VERSION ""

NS_ :

BS_:
BU_: ACC GW LAS BDC
BO_ 898 ACC_382: 64 ACC
 SG_ ACC_TarVehLngRange : 487|12@0+ (0.1000000000,0.0000000000) [0.0000000000|300.0000000000] "m"  LAS,GW
 SG_ ACC_Target5ZoneID : 449|5@0+ (1.0000000000,0.0000000000) [0.0000000000|31.0000000000] ""  LAS,GW,mADC
 SG_ ACC_Target5HeadingAngle : 443|10@0+ (0.0100000000,-3.1400000000) [-3.1400000000|3.1400000000] "rad"  LAS,GW,mADC
 SG_ ACC_Target5Direction : 446|3@0+ (1.0000000000,0.0000000000) [0.0000000000|7.0000000000] ""  LAS,GW,mADC
 SG_ ACC_Target5LatRange : 424|10@0+ (0.1000000000,-50.0000000000) [-50.0000000000|50.0000000000] "m"  LAS,GW,mADC
 SG_ ACC_Target5LngRange : 420|12@0+ (0.1000000000,-100.0000000000) [-100.0000000000|300.0000000000] "m"  LAS,GW,mADC
 SG_ ACC_Target5Type : 408|4@0+ (1.0000000000,0.0000000000) [0.0000000000|15.0000000000] ""  LAS,GW,mADC
 SG_ ACC_Target5ID : 414|6@0+ (1.0000000000,0.0000000000) [0.0000000000|63.0000000000] ""  LAS,GW,mADC
 SG_ ACC_Target5Detection : 401|3@0+ (1.0000000000,0.0000000000) [0.0000000000|7.0000000000] ""  LAS,GW,mADC
 SG_ ACC_Target4ZoneID : 406|5@0+ (1.0000000000,0.0000000000) [0.0000000000|31.0000000000] ""  LAS,GW,mADC
 SG_ ACC_Target4HeadingAngle : 384|10@0+ (0.0100000000,-3.1400000000) [-3.1400000000|3.1400000000] "rad"  LAS,GW,mADC
 SG_ ACC_Target4Direction : 387|3@0+ (1.0000000000,0.0000000000) [0.0000000000|7.0000000000] ""  LAS,GW,mADC
 SG_ ACC_Target4LatRange : 381|10@0+ (0.1000000000,-50.0000000000) [-50.0000000000|50.0000000000] "m"  LAS,GW,mADC
 SG_ ACC_Target4LngRange : 361|12@0+ (0.1000000000,-100.0000000000) [-100.0000000000|300.0000000000] "m"  LAS,GW,mADC
 SG_ ACC_Target4Type : 365|4@0+ (1.0000000000,0.0000000000) [0.0000000000|15.0000000000] ""  LAS,GW,mADC
 SG_ ACC_Target4ID : 355|6@0+ (1.0000000000,0.0000000000) [0.0000000000|63.0000000000] ""  LAS,GW,mADC
 SG_ ACC_Target4Detection : 358|3@0+ (1.0000000000,0.0000000000) [0.0000000000|7.0000000000] ""  LAS,GW,mADC
 SG_ ACC_Target3ZoneID : 347|5@0+ (1.0000000000,0.0000000000) [0.0000000000|31.0000000000] ""  LAS,GW,mADC
 SG_ ACC_Target3HeadingAngle : 341|10@0+ (0.0100000000,-3.1400000000) [-3.1400000000|3.1400000000] "rad"  LAS,GW,mADC
 SG_ ACC_Target3Direction : 328|3@0+ (1.0000000000,0.0000000000) [0.0000000000|7.0000000000] ""  LAS,GW,mADC
 SG_ ACC_Target3LatRange : 322|10@0+ (0.1000000000,-50.0000000000) [-50.0000000000|50.0000000000] "m"  LAS,GW,mADC
 SG_ ACC_Target3LngRange : 318|12@0+ (0.1000000000,-100.0000000000) [-100.0000000000|300.0000000000] "m"  LAS,GW,mADC
 SG_ ACC_Target3Type : 306|4@0+ (1.0000000000,0.0000000000) [0.0000000000|15.0000000000] ""  LAS,GW,mADC
 SG_ ACC_Target3ID : 296|6@0+ (1.0000000000,0.0000000000) [0.0000000000|63.0000000000] ""  LAS,GW,mADC
 SG_ ACC_Target3Detection : 299|3@0+ (1.0000000000,0.0000000000) [0.0000000000|7.0000000000] ""  LAS,GW,mADC
 SG_ ACC_Target2ZoneID : 288|5@0+ (1.0000000000,0.0000000000) [0.0000000000|31.0000000000] ""  LAS,GW,mADC
 SG_ ACC_Target2HeadingAngle : 282|10@0+ (0.0100000000,-3.1400000000) [-3.1400000000|3.1400000000] "rad"  LAS,GW,mADC
 SG_ ACC_Target2Direction : 285|3@0+ (1.0000000000,0.0000000000) [0.0000000000|7.0000000000] ""  LAS,GW,mADC
 SG_ ACC_Target2LatRange : 279|10@0+ (0.1000000000,-50.0000000000) [-50.0000000000|50.0000000000] "m"  LAS,GW,mADC
 SG_ ACC_Target2LngRange : 259|12@0+ (0.1000000000,-100.0000000000) [-100.0000000000|300.0000000000] "m"  LAS,GW,mADC
 SG_ ACC_Target2Type : 263|4@0+ (1.0000000000,0.0000000000) [0.0000000000|15.0000000000] ""  LAS,GW,mADC
 SG_ ACC_Target2ID : 253|6@0+ (1.0000000000,0.0000000000) [0.0000000000|63.0000000000] ""  LAS,GW,mADC
 SG_ ACC_Target2Detection : 240|3@0+ (1.0000000000,0.0000000000) [0.0000000000|7.0000000000] ""  LAS,GW,mADC
 SG_ ACC_Target1ZoneID : 247|5@0+ (1.0000000000,0.0000000000) [0.0000000000|31.0000000000] ""  LAS,GW,mADC
 SG_ ACC_Target1HeadingAngle : 225|10@0+ (0.0100000000,-3.1400000000) [-3.1400000000|3.1400000000] "rad"  LAS,GW,mADC
 SG_ ACC_Target1Direction : 202|3@0+ (1.0000000000,0.0000000000) [0.0000000000|7.0000000000] ""  LAS,GW,mADC
 SG_ ACC_Target1LatRange : 219|10@0+ (0.1000000000,-50.0000000000) [-50.0000000000|50.0000000000] "m"  LAS,GW,mADC
 SG_ ACC_Target1LngRange : 215|12@0+ (0.1000000000,-100.0000000000) [-100.0000000000|300.0000000000] "m"  LAS,GW,mADC
 SG_ ACC_Target1Type : 206|4@0+ (1.0000000000,0.0000000000) [0.0000000000|15.0000000000] ""  LAS,GW,mADC
 SG_ ACC_Target1ID : 196|6@0+ (1.0000000000,0.0000000000) [0.0000000000|63.0000000000] ""  LAS,GW,mADC
 SG_ ACC_Target1Detection : 199|3@0+ (1.0000000000,0.0000000000) [0.0000000000|7.0000000000] ""  LAS,GW,mADC
 SG_ ACC_RollingCounter_3E6 : 179|4@0+ (1.0000000000,0.0000000000) [0.0000000000|15.0000000000] ""  LAS,GW
 SG_ ACC_CRCCheck_3E6 : 191|8@0+ (1.0000000000,0.0000000000) [0.0000000000|255.0000000000] ""  LAS,GW
 SG_ ACC_CRCCheck_35C : 127|8@0+ (1.0000000000,0.0000000000) [0.0000000000|255.0000000000] ""  LAS,GW
 SG_ ACC_RollingCounter_35C : 115|4@0+ (1.0000000000,0.0000000000) [0.0000000000|15.0000000000] ""  LAS,GW
 SG_ ACC_CRCCheck_35D : 63|8@0+ (1.0000000000,0.0000000000) [0.0000000000|255.0000000000] ""  LAS,GW
 SG_ ACC_RollingCounter_35D : 51|4@0+ (1.0000000000,0.0000000000) [0.0000000000|15.0000000000] ""  LAS,GW
 SG_ ACC_LaneEquationStatus : 181|2@0+ (1.0000000000,0.0000000000) [0.0000000000|3.0000000000] ""  LAS,GW,mADC
 SG_ ACC_LaneEquationC3 : 161|12@0+ (0.0000004768,-0.0009760857) [-0.0009760857|0.0009760857] ""  LAS,GW,mADC
 SG_ ACC_LaneEquationC2 : 157|12@0+ (0.0000152588,-0.0312347412) [-0.0312347412|0.0312347412] ""  LAS,GW,mADC
 SG_ ACC_LaneEquationC1 : 137|12@0+ (0.0004882813,-1.0000000000) [-1.0000000000|0.9990234375] "rad"  LAS,GW,mADC
 SG_ ACC_LaneQuality : 134|6@0+ (0.0156250000,0.0000000000) [0.0000000000|0.9843750000] ""  LAS,GW

BO_ 676 GW_2A4: 64 GW
 SG_ LCDAR_AEBVehilceHoldReq : 131|1@0+ (1.0000000000,0.0000000000) [0.0000000000|1.0000000000] ""  ACC,LAS
 SG_ LCDAR_LDWShakeLevStatus : 133|2@0+ (1.0000000000,0.0000000000) [0.0000000000|3.0000000000] ""  ACC,LAS
 SG_ LCDAR_LDWVibrationWarningReq : 135|2@0+ (1.0000000000,0.0000000000) [0.0000000000|3.0000000000] ""  ACC,LAS
 SG_ LCDA_BSDLCAMode : 14|2@0+ (1.0000000000,0.0000000000) [0.0000000000|3.0000000000] ""  mADC,LAS,ACC
 SG_ LCDAR_RCTBStatus : 17|2@0+ (1.0000000000,0.0000000000) [0.0000000000|3.0000000000] ""  ACC,LAS,mADC
 SG_ LCDAR_CRCCheck_2AF : 63|8@0+ (1.0000000000,0.0000000000) [0.0000000000|255.0000000000] ""  LAS,ACC
 SG_ LCDAR_RollingCounter_2AF : 51|4@0+ (1.0000000000,0.0000000000) [0.0000000000|15.0000000000] ""  LAS,ACC
 SG_ LCDAR_ELK_oAlert : 25|2@0+ (1.0000000000,0.0000000000) [0.0000000000|3.0000000000] ""  LAS
 SG_ LCDAR_ELK_oStatus : 27|2@0+ (1.0000000000,0.0000000000) [0.0000000000|3.0000000000] ""  LAS
 SG_ LCDAR_Left_ELK_oAlert : 29|2@0+ (1.0000000000,0.0000000000) [0.0000000000|3.0000000000] ""  LAS
 SG_ LCDAR_RCTBActive : 19|1@0+ (1.0000000000,0.0000000000) [0.0000000000|1.0000000000] ""  ACC,LAS,mADC
 SG_ LCDAR_RCTBTargetDecel : 39|16@0+ (0.0005000000,-16.0000000000) [-16.0000000000|16.0000000000] "m/s2"  ACC,LAS
 SG_ LCDAR_SystemStatus : 12|3@0+ (1.0000000000,0.0000000000) [0.0000000000|7.0000000000] ""  ACC,LAS,mADC

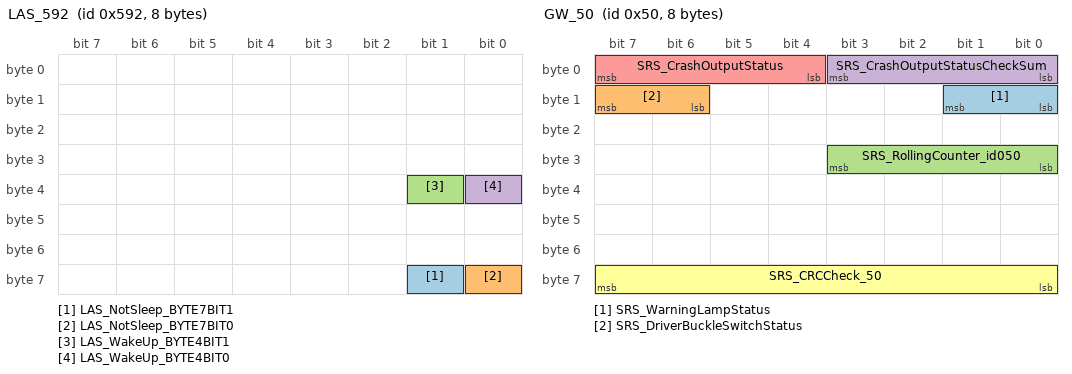
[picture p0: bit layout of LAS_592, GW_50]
BO_ 1426 LAS_592: 8 LAS
 SG_ LAS_NotSleep_BYTE7BIT1 : 57|1@0+ (1.0000000000,0.0000000000) [0.0000000000|1.0000000000] ""  GW
 SG_ LAS_NotSleep_BYTE7BIT0 : 56|1@0+ (1.0000000000,0.0000000000) [0.0000000000|1.0000000000] ""  GW
 SG_ LAS_WakeUp_BYTE4BIT1 : 33|1@0+ (1.0000000000,0.0000000000) [0.0000000000|1.0000000000] ""  GW
 SG_ LAS_WakeUp_BYTE4BIT0 : 32|1@0+ (1.0000000000,0.0000000000) [0.0000000000|1.0000000000] ""  GW

BO_ 80 GW_50: 8 GW
 SG_ SRS_WarningLampStatus : 9|2@0+ (1.0000000000,0.0000000000) [0.0000000000|3.0000000000] ""  ACC,LAS,mADC
 SG_ SRS_DriverBuckleSwitchStatus : 15|2@0+ (1.0000000000,0.0000000000) [0.0000000000|3.0000000000] ""  ACC,LAS,APA,mADC
 SG_ SRS_RollingCounter_id050 : 27|4@0+ (1.0000000000,0.0000000000) [0.0000000000|15.0000000000] ""  ACC,LAS,mADC
 SG_ SRS_CrashOutputStatusCheckSum : 3|4@0+ (1.0000000000,0.0000000000) [0.0000000000|15.0000000000] ""  ACC,LAS,mADC
 SG_ SRS_CrashOutputStatus : 7|4@0+ (1.0000000000,0.0000000000) [0.0000000000|15.0000000000] ""  ACC,LAS,APA,mADC
 SG_ SRS_CRCCheck_50 : 63|8@0+ (1.0000000000,0.0000000000) [0.0000000000|255.0000000000] ""  ACC,LAS,mADC

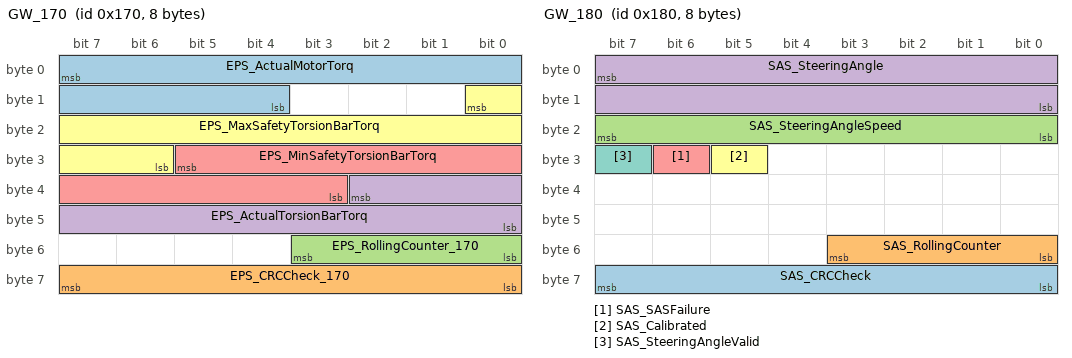
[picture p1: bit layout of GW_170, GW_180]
BO_ 368 GW_170: 8 GW
 SG_ EPS_ActualMotorTorq : 7|12@0+ (0.0100000000,-20.4800000000) [-20.4800000000|20.4600000000] "Nm"  LAS,mADC
 SG_ EPS_CRCCheck_170 : 63|8@0+ (1.0000000000,0.0000000000) [0.0000000000|255.0000000000] ""  mADC,ACC,LAS
 SG_ EPS_RollingCounter_170 : 51|4@0+ (1.0000000000,0.0000000000) [0.0000000000|15.0000000000] ""  ACC,LAS,mADC
 SG_ EPS_ActualTorsionBarTorq : 34|11@0+ (0.0200000000,-20.4800000000) [-20.4800000000|20.4400000000] "Nm"  LAS,mADC
 SG_ EPS_MinSafetyTorsionBarTorq : 29|11@0+ (0.0200000000,-20.4800000000) [-20.4800000000|20.4400000000] "Nm"  LAS,mADC
 SG_ EPS_MaxSafetyTorsionBarTorq : 8|11@0+ (0.0200000000,-20.4800000000) [-20.4800000000|20.4400000000] "Nm"  LAS,mADC

BO_ 384 GW_180: 8 GW
 SG_ SAS_CRCCheck : 63|8@0+ (1.0000000000,0.0000000000) [0.0000000000|255.0000000000] ""  APA,ACC,LAS,mADC
 SG_ SAS_RollingCounter : 51|4@0+ (1.0000000000,0.0000000000) [0.0000000000|15.0000000000] ""  APA,ACC,LAS,mADC
 SG_ SAS_SteeringAngleSpeed : 23|8@0+ (4.0000000000,0.0000000000) [0.0000000000|1016.0000000000] "deg/s"  APA,ACC,LAS,mADC
 SG_ SAS_SteeringAngle : 7|16@0- (0.1000000000,0.0000000000) [-780.0000000000|780.0000000000] "degree"  APA,ACC,LAS,mADC
 SG_ SAS_SASFailure : 30|1@0+ (1.0000000000,0.0000000000) [0.0000000000|1.0000000000] ""  APA,ACC,LAS,mADC
 SG_ SAS_Calibrated : 29|1@0+ (1.0000000000,0.0000000000) [0.0000000000|1.0000000000] ""  APA,ACC,LAS,mADC
 SG_ SAS_SteeringAngleValid : 31|1@0+ (1.0000000000,0.0000000000) [0.0000000000|1.0000000000] ""  APA,ACC,LAS,mADC

BO_ 580 ACC_244: 64 ACC
 SG_ ACC_AEBSpeedDropLevel : 162|2@0+ (1.0000000000,0.0000000000) [0.0000000000|3.0000000000] ""  LAS,mADC,GW
 SG_ ADS_ResetFlag_244 : 449|2@0+ (1.0000000000,0.0000000000) [0.0000000000|3.0000000000] ""  LAS,mADC,GW
 SG_ ADS_Authernticator_244 : 463|56@0+ (1.0000000000,0.0000000000) [0.0000000000|0.0000000000] ""  LAS,mADC,GW
 SG_ ADS_MesssageCounter_244 : 455|6@0+ (1.0000000000,0.0000000000) [0.0000000000|63.0000000000] ""  LAS,mADC,GW
 SG_ ADS_EOMTOReq : 155|2@0+ (1.0000000000,0.0000000000) [0.0000000000|3.0000000000] ""  LAS,GW
 SG_ ACC_HandsOnReq : 158|3@0+ (1.0000000000,0.0000000000) [0.0000000000|7.0000000000] ""  LAS,GW,APA,mADC
 SG_ ACC_LatTakeoverReq : 138|2@0+ (1.0000000000,0.0000000000) [0.0000000000|3.0000000000] ""  LAS,GW,APA,mADC
 SG_ ACC_LngTakeOverReq : 140|2@0+ (1.0000000000,0.0000000000) [0.0000000000|3.0000000000] ""  LAS,GW,APA,mADC
 SG_ ACC_LDWShakeLevStatus : 21|2@0+ (1.0000000000,0.0000000000) [0.0000000000|3.0000000000] ""  LAS,GW,mADC
 SG_ ACC_TextInfoForDriver : 30|6@0+ (1.0000000000,0.0000000000) [0.0000000000|63.0000000000] ""  LAS,GW,mADC
 SG_ ADS__RollingCounter_244 : 427|4@0+ (1.0000000000,0.0000000000) [0.0000000000|15.0000000000] ""  LAS,GW,mADC
 SG_ ADS_CRCCheck_244 : 439|16@0+ (1.0000000000,0.0000000000) [0.0000000000|65535.0000000000] ""  LAS,GW,mADC
 SG_ ACC_CRCCheck_25E : 127|8@0+ (1.0000000000,0.0000000000) [0.0000000000|255.0000000000] ""  LAS,GW,mADC
 SG_ ACC_RollingCounter_25E : 115|4@0+ (1.0000000000,0.0000000000) [0.0000000000|15.0000000000] ""  LAS,GW,mADC
 SG_ ACC_AEBCtrlType : 104|4@0+ (1.0000000000,0.0000000000) [0.0000000000|15.0000000000] ""  GW,LAS,APA,mADC
 SG_ ACC_FuelCutOffPrevention : 116|1@0+ (1.0000000000,0.0000000000) [0.0000000000|1.0000000000] ""  LAS,GW
 SG_ ACC_AccTrqReq : 88|14@0+ (5.0000000000,-5000.0000000000) [-5000.0000000000|5000.0000000000] "NM"  LAS,GW,mADC
 SG_ ACC_AccTrqReqActive : 106|1@0+ (1.0000000000,0.0000000000) [0.0000000000|1.0000000000] ""  LAS,GW,mADC
 SG_ ACC_AEBVehilceHoldReq : 90|1@0+ (1.0000000000,0.0000000000) [0.0000000000|1.0000000000] ""  LAS,GW,mADC
 SG_ ACC_FCWPreWarning : 91|1@0+ (1.0000000000,0.0000000000) [0.0000000000|1.0000000000] ""  LAS,GW,APA,mADC
 SG_ ACC_FCWLatentWarning : 92|1@0+ (1.0000000000,0.0000000000) [0.0000000000|1.0000000000] ""  LAS,GW,mADC
 SG_ ACC_FCWActive : 93|1@0+ (1.0000000000,0.0000000000) [0.0000000000|1.0000000000] ""  LAS,GW,mADC
 SG_ ACC_PrefillActive : 94|1@0+ (1.0000000000,0.0000000000) [0.0000000000|1.0000000000] ""  LAS,GW,mADC
 SG_ ACC_AWBActive : 95|1@0+ (1.0000000000,0.0000000000) [0.0000000000|1.0000000000] ""  LAS,GW,APA,mADC
 SG_ ACC_AWBlevel : 83|4@0+ (1.0000000000,0.0000000000) [0.0000000000|15.0000000000] ""  LAS,GW,mADC
 SG_ ACC_ABAActive : 84|1@0+ (1.0000000000,0.0000000000) [0.0000000000|1.0000000000] ""  LAS,GW,mADC
 SG_ ACC_ABAlevel : 86|2@0+ (1.0000000000,0.0000000000) [0.0000000000|3.0000000000] ""  LAS,GW,mADC
 SG_ ACC_AEBActive : 87|1@0+ (1.0000000000,0.0000000000) [0.0000000000|1.0000000000] ""  GW,APA,LAS,mADC
 SG_ ACC_AEBTargetDeceleration : 71|16@0+ (0.0005000000,-16.0000000000) [-16.0000000000|16.0000000000] "m/s2"  LAS,GW,mADC
 SG_ ACC_EmergencyDataRrdReq : 23|2@0+ (1.0000000000,0.0000000000) [0.0000000000|3.0000000000] ""  LAS,APA,GW,mADC
 SG_ ACC_CRCCheck_24E : 63|8@0+ (1.0000000000,0.0000000000) [0.0000000000|255.0000000000] ""  LAS,GW,mADC
 SG_ ACC_RollingCounter_24E : 51|4@0+ (1.0000000000,0.0000000000) [0.0000000000|15.0000000000] ""  LAS,GW,mADC
 SG_ ACC_Driveoff_Request : 55|1@0+ (1.0000000000,0.0000000000) [0.0000000000|1.0000000000] ""  LAS,GW,mADC
 SG_ ACC_ACCMode : 54|3@0+ (1.0000000000,0.0000000000) [0.0000000000|7.0000000000] ""  LAS,GW,APA,mADC
 SG_ ACC_CDDActive : 44|1@0+ (1.0000000000,0.0000000000) [0.0000000000|1.0000000000] ""  LAS,GW,mADC
 SG_ ACC_EngineStartStopRequest : 41|2@0+ (1.0000000000,0.0000000000) [0.0000000000|3.0000000000] ""  LAS,GW,mADC
 SG_ ACC_DecToStop : 31|1@0+ (1.0000000000,0.0000000000) [0.0000000000|1.0000000000] ""  LAS,GW,mADC
 SG_ ACC_TCUCreepProhibition : 32|1@0+ (1.0000000000,0.0000000000) [0.0000000000|1.0000000000] ""  LAS,GW
 SG_ ACC_LKAStatus : 13|2@0+ (1.0000000000,0.0000000000) [0.0000000000|3.0000000000] ""  LAS,GW,mADC
 SG_ ACC_LDWVibrationWarningReq : 11|2@0+ (1.0000000000,0.0000000000) [0.0000000000|3.0000000000] ""  LAS,GW,mADC
 SG_ ACC_LDWStatus : 9|2@0+ (1.0000000000,0.0000000000) [0.0000000000|3.0000000000] ""  LAS,GW,mADC
 SG_ ACC_ACCTargetAcceleration : 7|8@0+ (0.0500000000,-5.0000000000) [-5.0000000000|7.7500000000] "m/s2"  LAS,GW,mADC

BO_ 664 GW_298: 8 GW
 SG_ BCM_DriverDoorLockStatus : 44|2@0+ (1.0000000000,0.0000000000) [0.0000000000|3.0000000000] ""  ACC,LAS,APA,mADC
 SG_ BCM_LeftRearDoorStatus : 40|1@0+ (1.0000000000,0.0000000000) [0.0000000000|1.0000000000] ""  ACC,LAS,APA,mADC

BO_ 775 ACC_307: 64 ACC
 SG_ ACC_CSLmodeStatus : 14|1@0+ (1.0000000000,0.0000000000) [0.0000000000|1.0000000000] ""  LAS,mADC,GW
 SG_ ACC_CSLEnableStatus : 19|1@0+ (1.0000000000,0.0000000000) [0.0000000000|1.0000000000] ""  LAS,mADC,GW
 SG_ ACC_AEBTargetSelected : 235|3@0+ (1.0000000000,0.0000000000) [0.0000000000|7.0000000000] ""  LAS,GW
 SG_ ACC_AEBFeatureConfig : 84|4@0+ (1.0000000000,0.0000000000) [0.0000000000|15.0000000000] ""  LAS,GW
 SG_ ACC_LatDeviationDis : 55|3@0+ (1.0000000000,0.0000000000) [0.0000000000|7.0000000000] ""  LAS,GW
 SG_ ACC_LatDeviationReason : 34|3@0+ (1.0000000000,0.0000000000) [0.0000000000|7.0000000000] ""  LAS,GW,mADC
 SG_ ACC_IACCSuspendReason : 39|3@0+ (1.0000000000,0.0000000000) [0.0000000000|7.0000000000] ""  LAS,GW,mADC
 SG_ ACC_IACCProhibitionTime : 226|7@0+ (1.0000000000,0.0000000000) [0.0000000000|127.0000000000] "s"  LAS,GW,mADC
 SG_ ACC_Line_RR_Id : 479|8@0+ (1.0000000000,0.0000000000) [0.0000000000|255.0000000000] ""  LAS,GW,mADC
 SG_ ACC_Line_R_Id : 471|8@0+ (1.0000000000,0.0000000000) [0.0000000000|255.0000000000] ""  LAS,GW,mADC
 SG_ ACC_Line_LL_Id : 463|8@0+ (1.0000000000,0.0000000000) [0.0000000000|255.0000000000] ""  LAS,GW,mADC
 SG_ ACC_Line_L_Id : 455|8@0+ (1.0000000000,0.0000000000) [0.0000000000|255.0000000000] ""  LAS,GW,mADC
 SG_ ACC_RRLanecolor : 494|3@0+ (1.0000000000,0.0000000000) [0.0000000000|7.0000000000] ""  LAS,GW,mADC
 SG_ ACC_RLanecolor : 481|3@0+ (1.0000000000,0.0000000000) [0.0000000000|7.0000000000] ""  LAS,GW,mADC
 SG_ ACC_LLLanecolor : 484|3@0+ (1.0000000000,0.0000000000) [0.0000000000|7.0000000000] ""  LAS,GW,mADC
 SG_ ACC_LLanecolor : 487|3@0+ (1.0000000000,0.0000000000) [0.0000000000|7.0000000000] ""  LAS,GW,mADC
 SG_ ACC_RLaneDistanceFus : 415|7@0+ (0.0500000000,-5.0000000000) [-5.0000000000|1.0000000000] "m"  LAS,GW,mADC
 SG_ ACC_LLaneDistanceFus : 407|7@0+ (0.0500000000,-1.0000000000) [-1.0000000000|5.0000000000] "m"  LAS,GW,mADC
 SG_ ACC_RRLaneDis : 399|8@0+ (0.0500000000,-12.0000000000) [-12.0000000000|0.0000000000] "m"  LAS,GW,mADC
 SG_ ACC_LLLaneDis : 391|8@0+ (0.0500000000,0.0000000000) [0.0000000000|12.0000000000] "m"  LAS,GW,mADC
 SG_ ACC_Target7ZoneID : 375|5@0+ (1.0000000000,0.0000000000) [0.0000000000|31.0000000000] ""  LAS,GW,mADC
 SG_ ACC_Target7HeadingAngle : 353|10@0+ (0.0100000000,-3.1400000000) [-3.1400000000|3.1400000000] "rad"  LAS,GW,mADC
 SG_ ACC_Target7Direction : 330|3@0+ (1.0000000000,0.0000000000) [0.0000000000|7.0000000000] ""  LAS,GW,mADC
 SG_ ACC_Target7LatRange : 347|10@0+ (0.1000000000,-50.0000000000) [-50.0000000000|50.0000000000] "m"  LAS,GW,mADC
 SG_ ACC_Target7LngRange : 343|12@0+ (0.1000000000,-100.0000000000) [-100.0000000000|300.0000000000] "m"  LAS,GW,mADC
 SG_ ACC_Target7Type : 334|4@0+ (1.0000000000,0.0000000000) [0.0000000000|15.0000000000] ""  LAS,GW,mADC
 SG_ ACC_Target7ID : 324|6@0+ (1.0000000000,0.0000000000) [0.0000000000|63.0000000000] ""  LAS,GW,mADC
 SG_ ACC_Target7Detection : 327|3@0+ (1.0000000000,0.0000000000) [0.0000000000|7.0000000000] ""  LAS,GW,mADC
 SG_ ACC_Target6ZoneID : 311|5@0+ (1.0000000000,0.0000000000) [0.0000000000|31.0000000000] ""  LAS,GW,mADC
 SG_ ACC_Target6HeadingAngle : 289|10@0+ (0.0100000000,-3.1400000000) [-3.1400000000|3.1400000000] "rad"  LAS,GW,mADC
 SG_ ACC_Target6Direction : 266|3@0+ (1.0000000000,0.0000000000) [0.0000000000|7.0000000000] ""  LAS,GW,mADC
 SG_ ACC_Target6LatRange : 283|10@0+ (0.1000000000,-50.0000000000) [-50.0000000000|50.0000000000] "m"  LAS,GW,mADC
 SG_ ACC_Target6LngRange : 279|12@0+ (0.1000000000,-100.0000000000) [-100.0000000000|300.0000000000] "m"  LAS,GW,mADC
 SG_ ACC_Target6Type : 270|4@0+ (1.0000000000,0.0000000000) [0.0000000000|15.0000000000] ""  LAS,GW,mADC
 SG_ ACC_Target6ID : 260|6@0+ (1.0000000000,0.0000000000) [0.0000000000|63.0000000000] ""  LAS,GW,mADC
 SG_ ACC_Target6Detection : 263|3@0+ (1.0000000000,0.0000000000) [0.0000000000|7.0000000000] ""  LAS,GW,mADC
 SG_ ACC_AEBEnable : 27|2@0+ (1.0000000000,0.0000000000) [0.0000000000|3.0000000000] ""  LAS,GW,mADC
 SG_ ACC_VehicleStartRemindSts : 425|3@0+ (1.0000000000,0.0000000000) [0.0000000000|7.0000000000] ""  LAS,GW,mADC
 SG_ ACC_CRCCheck_35F : 255|8@0+ (1.0000000000,0.0000000000) [0.0000000000|255.0000000000] ""  LAS,GW,mADC
 SG_ ACC_RollingCounter_35F : 243|4@0+ (1.0000000000,0.0000000000) [0.0000000000|15.0000000000] ""  LAS,GW,mADC
 SG_ ACC_CSLAEnableStatus : 245|2@0+ (1.0000000000,0.0000000000) [0.0000000000|3.0000000000] ""  LAS,GW
 SG_ ACC_CSLSetReq : 227|1@0+ (1.0000000000,0.0000000000) [0.0000000000|1.0000000000] ""  LAS,GW,mADC
 SG_ ACC_CRCCheck_344 : 191|8@0+ (1.0000000000,0.0000000000) [0.0000000000|255.0000000000] ""  LAS,GW,mADC
 SG_ ACC_RollingCounter_344 : 179|4@0+ (1.0000000000,0.0000000000) [0.0000000000|15.0000000000] ""  LAS,GW,mADC
 SG_ ACC_CRCCheck_322 : 127|8@0+ (1.0000000000,0.0000000000) [0.0000000000|255.0000000000] ""  LAS,GW,mADC
 SG_ ACC_RollingCounter_322 : 115|4@0+ (1.0000000000,0.0000000000) [0.0000000000|15.0000000000] ""  LAS,GW,mADC
 SG_ ACC_ACCTargetRelSpd : 92|9@0+ (1.0000000000,-250.0000000000) [-250.0000000000|250.0000000000] "km/h"  LAS,GW
 SG_ ACC_FRadarCalibrationStatus : 94|2@0+ (1.0000000000,0.0000000000) [0.0000000000|3.0000000000] ""  LAS,GW,mADC
 SG_ ACC_CRCCheck_35E : 63|8@0+ (1.0000000000,0.0000000000) [0.0000000000|255.0000000000] ""  LAS,GW,mADC
 SG_ ACC_RollingCounter_35E : 51|4@0+ (1.0000000000,0.0000000000) [0.0000000000|15.0000000000] ""  LAS,GW,mADC
 SG_ ACC_FCWSettingStatus : 30|3@0+ (1.0000000000,0.0000000000) [0.0000000000|7.0000000000] ""  LAS,GW,mADC
 SG_ ACC_ACCEPBrequest : 23|1@0+ (1.0000000000,0.0000000000) [0.0000000000|1.0000000000] ""  LAS,GW,mADC
 SG_ ACC_ObjValid : 13|1@0+ (1.0000000000,0.0000000000) [0.0000000000|1.0000000000] ""  LAS,GW
 SG_ ACC_TimeGapSet : 18|3@0+ (1.0000000000,0.0000000000) [0.0000000000|7.0000000000] ""  LAS,GW,mADC
 SG_ ACC_DistanceLevel : 22|3@0+ (1.0000000000,0.0000000000) [0.0000000000|7.0000000000] ""  LAS,GW,mADC
 SG_ ACC_SetSpeed : 6|8@0+ (1.0000000000,0.0000000000) [0.0000000000|254.0000000000] "Km/h"  LAS,GW,mADC

BO_ 786 ACC_312: 64 ACC
 SG_ ACC_SBUNCountDown : 27|5@0+ (1.0000000000,0.0000000000) [0.0000000000|31.0000000000] ""  LAS,mADC,GW
 SG_ ACC_RRLaneQuality : 475|6@0+ (0.0156250000,0.0000000000) [0.0000000000|0.9843750000] ""  LAS,mADC,GW
 SG_ ACC_LLaneQuality : 471|6@0+ (0.0156250000,0.0000000000) [0.0000000000|0.9843750000] ""  LAS,mADC,GW
 SG_ ACC_horizenLongPos : 463|8@0+ (1.0000000000,0.0000000000) [0.0000000000|200.0000000000] "m"  LAS,mADC,GW
 SG_ ACC_ACCSysdeactiveReason : 371|5@0+ (1.0000000000,0.0000000000) [0.0000000000|31.0000000000] ""  LAS,mADC,GW
 SG_ ACC_AEBTargetFourWheelProb : 276|7@0+ (1.0000000000,0.0000000000) [0.0000000000|100.0000000000] "%"  LAS,GW
 SG_ ACC_AEBTargetProb : 38|7@0+ (1.0000000000,0.0000000000) [0.0000000000|100.0000000000] "%"  LAS,GW,mADC
 SG_ ACC_AEBTargetStatus : 278|2@0+ (1.0000000000,0.0000000000) [0.0000000000|3.0000000000] ""  LAS,mADC,GW
 SG_ ACC_AEBTargetAy : 270|8@0+ (0.1000000000,-12.0000000000) [-12.0000000000|12.0000000000] "m/s2"  LAS,mADC,GW
 SG_ ACC_AEBTargetAx : 263|9@0+ (0.1000000000,-16.0000000000) [-16.0000000000|16.0000000000] "m/s2"  LAS,mADC,GW
 SG_ ACC_CRCCheck_312 : 503|16@0+ (1.0000000000,0.0000000000) [0.0000000000|65535.0000000000] ""  LAS,mADC,GW
 SG_ ADS_SpdLimitedStatus : 79|2@0+ (1.0000000000,0.0000000000) [0.0000000000|3.0000000000] ""  LAS,mADC,GW
 SG_ ADS_AutoHeadlightshift_Req : 163|1@0+ (1.0000000000,0.0000000000) [0.0000000000|1.0000000000] ""  LAS,mADC,GW
 SG_ ADS_UDLCTurnLightReq : 154|3@0+ (1.0000000000,0.0000000000) [0.0000000000|7.0000000000] ""  LAS,mADC,GW
 SG_ ACC_Selflearning_status : 13|2@0+ (1.0000000000,0.0000000000) [0.0000000000|3.0000000000] ""  LAS,GW,mADC
 SG_ ACC_Selflearning_angle : 238|11@0+ (0.0100000000,-10.2500000000) [-10.2500000000|10.2200000000] "degree"  LAS,GW,mADC
 SG_ ADS_NDAAudioWarEnableStatus : 107|1@0+ (1.0000000000,0.0000000000) [0.0000000000|1.0000000000] ""  LAS,GW,mADC
 SG_ ADS_ADSVoiceRequest : 102|9@0+ (1.0000000000,0.0000000000) [0.0000000000|511.0000000000] ""  LAS,mADC,GW
 SG_ ADS_EOMWarnning : 71|3@0+ (1.0000000000,0.0000000000) [0.0000000000|7.0000000000] ""  LAS,GW,APA
 SG_ ADS_CRCCheck_3D7 : 255|8@0+ (1.0000000000,0.0000000000) [0.0000000000|255.0000000000] ""  LAS,GW
 SG_ ADS_RollingCounter_3D7 : 243|4@0+ (1.0000000000,0.0000000000) [0.0000000000|15.0000000000] ""  LAS,GW
 SG_ ACC_DriverWindowControl : 198|7@0+ (1.0000000000,0.0000000000) [0.0000000000|100.0000000000] "%"  LAS,GW,mADC
 SG_ ACC_AEBTargetDirection : 47|3@0+ (1.0000000000,0.0000000000) [0.0000000000|7.0000000000] ""  LAS,GW,mADC
 SG_ ACC_AEBTargetDetection : 44|1@0+ (1.0000000000,0.0000000000) [0.0000000000|1.0000000000] ""  LAS,GW,mADC
 SG_ ACC_AEBTargetType : 43|4@0+ (1.0000000000,0.0000000000) [0.0000000000|15.0000000000] ""  LAS,GW,mADC
 SG_ ACC_CRCCheck_3E4 : 63|8@0+ (1.0000000000,0.0000000000) [0.0000000000|255.0000000000] ""  LAS,GW,mADC
 SG_ ACC_RollingCounter_3E4 : 51|4@0+ (1.0000000000,0.0000000000) [0.0000000000|15.0000000000] ""  LAS,GW,mADC

BO_ 832 GW_340: 8 GW
 SG_ AC_FrBlowType : 2|3@0+ (1.0000000000,0.0000000000) [0.0000000000|7.0000000000] ""  ACC,LAS

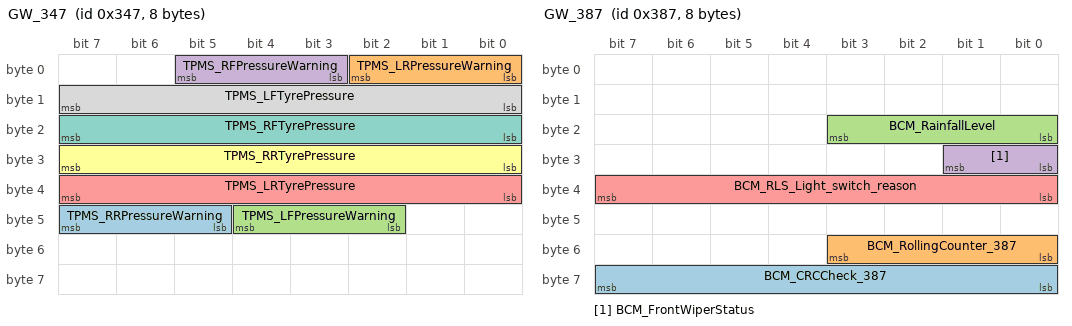
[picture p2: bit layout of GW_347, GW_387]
BO_ 839 GW_347: 8 GW
 SG_ TPMS_RRPressureWarning : 47|3@0+ (1.0000000000,0.0000000000) [0.0000000000|7.0000000000] ""  ACC,LAS,mADC
 SG_ TPMS_LRPressureWarning : 2|3@0+ (1.0000000000,0.0000000000) [0.0000000000|7.0000000000] ""  ACC,LAS,mADC
 SG_ TPMS_LFPressureWarning : 44|3@0+ (1.0000000000,0.0000000000) [0.0000000000|7.0000000000] ""  ACC,LAS,mADC
 SG_ TPMS_RFPressureWarning : 5|3@0+ (1.0000000000,0.0000000000) [0.0000000000|7.0000000000] ""  ACC,LAS,mADC
 SG_ TPMS_LRTyrePressure : 39|8@0+ (1.3730000000,0.0000000000) [0.0000000000|350.1150000000] "KPa"  ACC,LAS
 SG_ TPMS_RRTyrePressure : 31|8@0+ (1.3730000000,0.0000000000) [0.0000000000|350.1150000000] "KPa"  ACC,LAS
 SG_ TPMS_RFTyrePressure : 23|8@0+ (1.3730000000,0.0000000000) [0.0000000000|350.1150000000] "KPa"  ACC,LAS
 SG_ TPMS_LFTyrePressure : 15|8@0+ (1.3730000000,0.0000000000) [0.0000000000|350.1150000000] "KPa"  ACC,LAS

BO_ 869 GW_365: 32 GW
 SG_ IMS_DriverREyeDetect : 229|2@0+ (1.0000000000,0.0000000000) [0.0000000000|3.0000000000] ""  ACC,LAS,mADC
 SG_ IMS_DriverLEyeDetect : 231|2@0+ (1.0000000000,0.0000000000) [0.0000000000|3.0000000000] ""  ACC,LAS,mADC
 SG_ IMS_JawOffsetValue : 91|4@0+ (1.0000000000,0.0000000000) [0.0000000000|15.0000000000] "cm"  ACC,LAS,mADC
 SG_ IMS_BrowOffsetValue : 95|4@0+ (1.0000000000,0.0000000000) [0.0000000000|15.0000000000] "cm"  ACC,LAS,mADC
 SG_ IMS_DriverEyeClosestatus : 27|3@0+ (1.0000000000,0.0000000000) [0.0000000000|7.0000000000] ""  ACC,LAS,mADC
 SG_ IMS_RollingCounter_3A7 : 179|4@0+ (1.0000000000,0.0000000000) [0.0000000000|15.0000000000] ""  ACC,LAS
 SG_ IMS_CRCCheck_3A7 : 191|8@0+ (1.0000000000,0.0000000000) [0.0000000000|255.0000000000] ""  ACC,LAS
 SG_ IMS_RollingCounter_360 : 115|4@0+ (1.0000000000,0.0000000000) [0.0000000000|15.0000000000] ""  ACC,LAS
 SG_ IMS_CRCCheck_360 : 127|8@0+ (1.0000000000,0.0000000000) [0.0000000000|255.0000000000] ""  ACC,LAS
 SG_ IMS_HeadDetectSts_Yaw : 87|8@0+ (1.0000000000,-75.0000000000) [-75.0000000000|75.0000000000] "度"  ACC,LAS,mADC
 SG_ IMS_HeadDetectSts_Roll : 79|8@0+ (1.0000000000,-45.0000000000) [-45.0000000000|45.0000000000] "度"  ACC,LAS,mADC
 SG_ IMS_HeadDetectSts_Pitch : 71|8@0+ (1.0000000000,-25.0000000000) [-25.0000000000|45.0000000000] "度"  ACC,LAS,mADC
 SG_ IMS_RollingCounter_356 : 51|4@0+ (1.0000000000,0.0000000000) [0.0000000000|15.0000000000] ""  ACC,LAS
 SG_ IMS_CRCCheck_356 : 63|8@0+ (1.0000000000,0.0000000000) [0.0000000000|255.0000000000] ""  ACC,LAS
 SG_ IMS_IMSStatus : 0|3@0+ (1.0000000000,0.0000000000) [0.0000000000|7.0000000000] ""  ACC,LAS,mADC
 SG_ IMS_EyeGazeStatus : 21|8@0+ (1.0000000000,-75.0000000000) [-75.0000000000|75.0000000000] "度"  ACC,LAS,mADC
 SG_ IMS_EyeDetectSatus : 13|8@0+ (1.0000000000,0.0000000000) [0.0000000000|100.0000000000] "%"  ACC,LAS,mADC
 SG_ IMS_DrowsinessStatus : 3|3@0+ (1.0000000000,0.0000000000) [0.0000000000|7.0000000000] ""  ACC,LAS,mADC
 SG_ IMS_DriverHeadDetect : 5|2@0+ (1.0000000000,0.0000000000) [0.0000000000|3.0000000000] ""  ACC,LAS,mADC
 SG_ IMS_DistractionStatus : 7|2@0+ (1.0000000000,0.0000000000) [0.0000000000|3.0000000000] ""  ACC,LAS,mADC

BO_ 870 GW_366: 8 GW
 SG_ AC_EnvironmentalTemp : 23|8@0+ (0.5000000000,-40.0000000000) [-40.0000000000|87.0000000000] "degreeC"  ACC,LAS,mADC
 SG_ AC_EnvironmentalTempVD : 8|1@0+ (1.0000000000,0.0000000000) [0.0000000000|1.0000000000] ""  ACC,LAS,mADC

BO_ 903 GW_387: 8 GW
 SG_ BCM_CRCCheck_387 : 63|8@0+ (1.0000000000,0.0000000000) [0.0000000000|255.0000000000] ""  ACC,LAS,mADC
 SG_ BCM_RollingCounter_387 : 51|4@0+ (1.0000000000,0.0000000000) [0.0000000000|15.0000000000] ""  ACC,LAS,mADC
 SG_ BCM_RainfallLevel : 19|4@0+ (1.0000000000,0.0000000000) [0.0000000000|15.0000000000] ""  ACC,LAS,APA,mADC
 SG_ BCM_FrontWiperStatus : 25|2@0+ (1.0000000000,0.0000000000) [0.0000000000|3.0000000000] ""  APA,ACC,LAS,mADC
 SG_ BCM_RLS_Light_switch_reason : 39|8@0+ (1.0000000000,0.0000000000) [0.0000000000|255.0000000000] ""  ACC,APA,mADC,LAS,mADC

BO_ 912 GW_390: 8 GW
 SG_ BCM_SOH_LifePercent : 15|8@0+ (1.0000000000,0.0000000000) [0.0000000000|255.0000000000] "%"  ACC,LAS
 SG_ BCM_PMSLevel : 5|3@0+ (1.0000000000,0.0000000000) [0.0000000000|7.0000000000] ""  ACC,LAS,mADC

BO_ 918 GW_396: 8 GW
 SG_ BCM_SunroofStatus : 0|1@0+ (1.0000000000,0.0000000000) [0.0000000000|1.0000000000] ""  ACC,LAS,APA,mADC

BO_ 1287 GW_507: 64 GW
 SG_ HU_LDWSenStyle : 246|2@0+ (1.0000000000,0.0000000000) [0.0000000000|3.0000000000] ""  ACC,LAS,mADC
 SG_ HU_OverspeedWarningOffRatioset_EU : 287|6@0+ (0.5000000000,-3.0000000000) [-3.0000000000|63.0000000000] "%"  ACC,LAS,mADC
 SG_ HU_TSRSpeedLimitChangeSoundEn : 273|2@0+ (1.0000000000,0.0000000000) [0.0000000000|3.0000000000] ""  ACC,LAS,mADC
 SG_ HU_TSREnable : 275|2@0+ (1.0000000000,0.0000000000) [0.0000000000|3.0000000000] ""  ACC,LAS,mADC
 SG_ HU_CSLWarnOffsetTp : 222|2@0+ (1.0000000000,0.0000000000) [0.0000000000|3.0000000000] ""  ACC,LAS,mADC
 SG_ HU_CSLEnable : 208|2@0+ (1.0000000000,0.0000000000) [0.0000000000|3.0000000000] ""  ACC,LAS,mADC
 SG_ HU_CSLmode : 210|2@0+ (1.0000000000,0.0000000000) [0.0000000000|3.0000000000] ""  ACC,LAS,mADC
 SG_ HU_VC_CruiseSetSpeed : 151|8@0+ (1.0000000000,0.0000000000) [0.0000000000|255.0000000000] ""  ACC,LAS,mADC
 SG_ HU_VC_CruiseSetDistance : 142|3@0+ (1.0000000000,0.0000000000) [0.0000000000|7.0000000000] ""  ACC,LAS,mADC
 SG_ HU_VC_CruiseControl : 138|3@0+ (1.0000000000,0.0000000000) [0.0000000000|7.0000000000] ""  ACC,LAS,mADC
 SG_ HU_FCWSetting : 165|3@0+ (1.0000000000,0.0000000000) [0.0000000000|7.0000000000] ""  LAS,ACC,mADC
 SG_ HU_AutoBrakeEnable : 132|2@0+ (1.0000000000,0.0000000000) [0.0000000000|3.0000000000] ""  ACC,LAS,APA,mADC
 SG_ HU_IACCEnable : 29|2@0+ (1.0000000000,0.0000000000) [0.0000000000|3.0000000000] ""  LAS,mADC
 SG_ HU_HMAEnable : 75|2@0+ (1.0000000000,0.0000000000) [0.0000000000|3.0000000000] ""  LAS,mADC
 SG_ HU_TSRSwitch : 11|1@0+ (1.0000000000,0.0000000000) [0.0000000000|1.0000000000] ""  LAS,mADC
 SG_ HU_LASWarningModeSelection : 10|3@0+ (1.0000000000,0.0000000000) [0.0000000000|7.0000000000] ""  APA,mADC,LAS
 SG_ HU_LASModeSelection : 5|3@0+ (1.0000000000,0.0000000000) [0.0000000000|7.0000000000] ""  LAS,mADC
 SG_ HU_OverspeedWarningOffset : 239|6@0+ (1.0000000000,-10.0000000000) [-10.0000000000|47.0000000000] "km/h"  LAS,mADC
 SG_ HU_OverspeedWarningEnable : 33|2@0+ (1.0000000000,0.0000000000) [0.0000000000|3.0000000000] ""  LAS,mADC
 SG_ HU_OverspeedSoundWarEnable : 31|2@0+ (1.0000000000,0.0000000000) [0.0000000000|3.0000000000] ""  LAS,mADC
 SG_ HU_NDAAudioWarEnable : 169|2@0+ (1.0000000000,0.0000000000) [0.0000000000|3.0000000000] ""  ACC,LAS,mADC

BO_ 1302 GW_516: 32 GW
 SG_ HU_LocalTimeSystem : 111|2@0+ (1.0000000000,0.0000000000) [0.0000000000|3.0000000000] ""  APA,ACC,LAS,mADC
 SG_ HU_LocalTimeSecond : 109|6@0+ (1.0000000000,0.0000000000) [0.0000000000|59.0000000000] "second"  APA,ACC,LAS,mADC
 SG_ HU_LocalTimeMinute : 101|6@0+ (1.0000000000,0.0000000000) [0.0000000000|59.0000000000] "minute"  APA,ACC,LAS,mADC
 SG_ HU_LocalTimeHour : 92|5@0+ (1.0000000000,0.0000000000) [0.0000000000|23.0000000000] "hour"  APA,ACC,LAS,mADC
 SG_ HU_LocalTimeDate : 84|5@0+ (1.0000000000,0.0000000000) [1.0000000000|31.0000000000] "day"  APA,ACC,LAS,mADC
 SG_ HU_LocalTimeYear : 119|8@0+ (1.0000000000,2013.0000000000) [2013.0000000000|2268.0000000000] "year"  APA,ACC,LAS,mADC
 SG_ HU_LocalTimeMonth : 75|4@0+ (1.0000000000,0.0000000000) [1.0000000000|12.0000000000] "month"  APA,ACC,LAS,mADC
 SG_ HU_LocalTimeValid : 71|1@0+ (1.0000000000,0.0000000000) [0.0000000000|1.0000000000] ""  APA,ACC,LAS,mADC
 SG_ HU_CurrentLocationLatitude : 35|28@0+ (0.0000010000,-134.2177270000) [-90.0000000000|90.0000000000] "degree"  APA,ACC,LAS,mADC
 SG_ HU_CurrentLocationLongitude : 4|29@0+ (0.0000010000,-268.4354550000) [-180.0000000000|180.0000000000] "degree"  APA,ACC,LAS,mADC
 SG_ HU_CurrentLocationValid : 7|1@0+ (1.0000000000,0.0000000000) [0.0000000000|1.0000000000] ""  APA,ACC,LAS,mADC

BO_ 1328 GW_530: 8 GW
 SG_ IP_TotalOdometer : 23|24@0+ (0.1000000000,0.0000000000) [0.0000000000|999999.0000000000] "Km"  LAS,ACC,APA,mADC

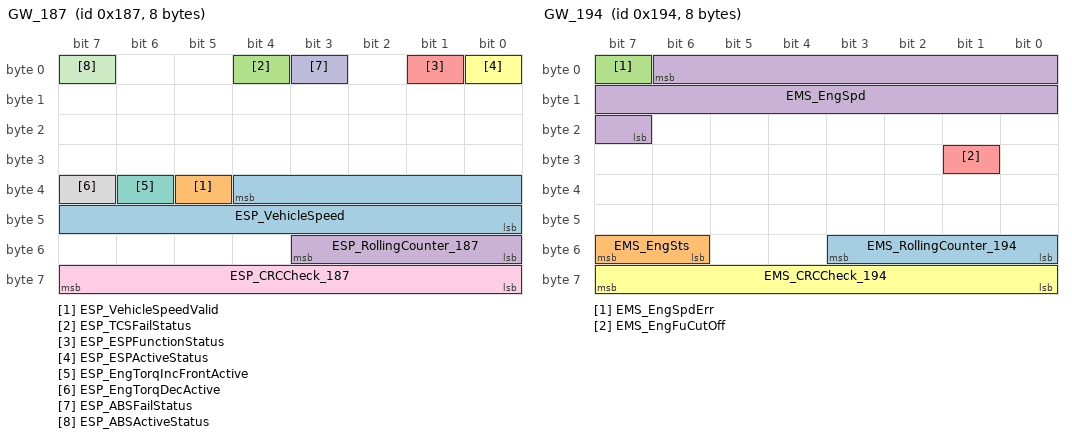
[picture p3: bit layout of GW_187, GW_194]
BO_ 391 GW_187: 8 GW
 SG_ ESP_VehicleSpeed : 36|13@0+ (0.0562500000,0.0000000000) [0.0000000000|360.0000000000] "km/h"  APA,ACC,LAS
 SG_ ESP_VehicleSpeedValid : 37|1@0+ (1.0000000000,0.0000000000) [0.0000000000|1.0000000000] ""  APA,ACC,LAS
 SG_ ESP_TCSFailStatus : 4|1@0+ (1.0000000000,0.0000000000) [0.0000000000|1.0000000000] ""  APA,ACC,LAS
 SG_ ESP_RollingCounter_187 : 51|4@0+ (1.0000000000,0.0000000000) [0.0000000000|15.0000000000] ""  ACC,LAS,APA
 SG_ ESP_ESPFunctionStatus : 1|1@0+ (1.0000000000,0.0000000000) [0.0000000000|1.0000000000] ""  APA,ACC,LAS
 SG_ ESP_ESPActiveStatus : 0|1@0+ (1.0000000000,0.0000000000) [0.0000000000|1.0000000000] ""  APA,ACC,LAS
 SG_ ESP_EngTorqIncFrontActive : 38|1@0+ (1.0000000000,0.0000000000) [0.0000000000|1.0000000000] ""  LAS,ACC,APA
 SG_ ESP_EngTorqDecActive : 39|1@0+ (1.0000000000,0.0000000000) [0.0000000000|1.0000000000] ""  LAS,ACC,APA
 SG_ ESP_CRCCheck_187 : 63|8@0+ (1.0000000000,0.0000000000) [0.0000000000|255.0000000000] ""  APA,ACC,LAS
 SG_ ESP_ABSFailStatus : 3|1@0+ (1.0000000000,0.0000000000) [0.0000000000|1.0000000000] ""  APA,ACC,LAS
 SG_ ESP_ABSActiveStatus : 7|1@0+ (1.0000000000,0.0000000000) [0.0000000000|1.0000000000] ""  ACC,LAS,APA

BO_ 407 GW_197: 8 GW
 SG_ ESP_RollingCounter_197 : 51|4@0+ (1.0000000000,0.0000000000) [0.0000000000|15.0000000000] ""  ACC,LAS,APA
 SG_ ESP_CRCCheck_197 : 63|8@0+ (1.0000000000,0.0000000000) [0.0000000000|255.0000000000] ""  APA,ACC,LAS

BO_ 404 GW_194: 8 GW
 SG_ EMS_RollingCounter_194 : 51|4@0+ (1.0000000000,0.0000000000) [0.0000000000|15.0000000000] ""  ACC,LAS
 SG_ EMS_EngSts : 55|2@0+ (1.0000000000,0.0000000000) [0.0000000000|3.0000000000] ""  APA,ACC,LAS
 SG_ EMS_EngSpdErr : 7|1@0+ (1.0000000000,0.0000000000) [0.0000000000|1.0000000000] ""  ACC,LAS
 SG_ EMS_EngSpd : 6|16@0+ (0.2500000000,0.0000000000) [0.0000000000|16383.5000000000] "Rpm"  ACC,LAS
 SG_ EMS_EngFuCutOff : 25|1@0+ (1.0000000000,0.0000000000) [0.0000000000|1.0000000000] ""  LAS,ACC
 SG_ EMS_CRCCheck_194 : 63|8@0+ (1.0000000000,0.0000000000) [0.0000000000|255.0000000000] ""  ACC,LAS,APA

BO_ 381 GW_17D: 64 GW
 SG_ PCU_PwrIndcdRealTqRearWhl : 391|15@0+ (1.0000000000,-5400.0000000000) [-5400.0000000000|12000.0000000000] "Nm"  ACC,LAS,APA,mADC
 SG_ PCU_PwrIndcdDrvrReqTqWhlRear : 392|15@0+ (1.0000000000,-5400.0000000000) [-5400.0000000000|12000.0000000000] "Nm"  ACC,LAS
 SG_ PCU_PwrTrainSts : 311|2@0+ (1.0000000000,0.0000000000) [0.0000000000|3.0000000000] ""  ACC,LAS,APA
 SG_ PCU_BrkPedlSts : 291|2@0+ (1.0000000000,0.0000000000) [0.0000000000|3.0000000000] ""  ACC,LAS,APA
 SG_ PCU_AccPedlVld : 288|1@0+ (1.0000000000,0.0000000000) [0.0000000000|1.0000000000] ""  ACC,LAS,APA,mADC
 SG_ PCU_AccPedl : 303|8@0+ (0.3920000000,0.0000000000) [0.0000000000|99.9600000000] "pct"  ACC,LAS,APA,mADC
 SG_ PCU_QECACC : 230|2@0+ (1.0000000000,0.0000000000) [0.0000000000|3.0000000000] ""  ACC,LAS,mADC
 SG_ PCU_PwrIndcdRealTqWhlFailr : 225|1@0+ (1.0000000000,0.0000000000) [0.0000000000|1.0000000000] ""  ACC,LAS,APA,mADC
 SG_ PCU_PwrIndcdRealTqFrontWhl : 199|15@0+ (1.0000000000,-5400.0000000000) [-5400.0000000000|12000.0000000000] "Nm"  ACC,LAS,APA,mADC
 SG_ PCU_PwrIndcdDrvrReqTqWhlFront : 200|15@0+ (1.0000000000,-5400.0000000000) [-5400.0000000000|12000.0000000000] "Nm"  ACC,LAS,APA,mADC
 SG_ PCU_ECGPOvrd : 231|1@0+ (1.0000000000,0.0000000000) [0.0000000000|1.0000000000] ""  ACC,LAS,mADC
 SG_ PCU_AccReqPossible : 228|1@0+ (1.0000000000,0.0000000000) [0.0000000000|1.0000000000] ""  ACC,LAS,mADC
 SG_ PCU_TarGearReqValid : 111|1@0+ (1.0000000000,0.0000000000) [0.0000000000|1.0000000000] ""  ACC,LAS
 SG_ PCU_TarGearReq : 99|4@0+ (1.0000000000,0.0000000000) [0.0000000000|15.0000000000] ""  ACC,LAS
 SG_ PCU_RealAccPedlVld : 79|1@0+ (1.0000000000,0.0000000000) [0.0000000000|1.0000000000] ""  ACC,LAS,APA,mADC
 SG_ PCU_RealAccPedl : 71|8@0+ (0.3920000000,0.0000000000) [0.0000000000|99.9600000000] "%"  LAS,APA,mADC,ACC

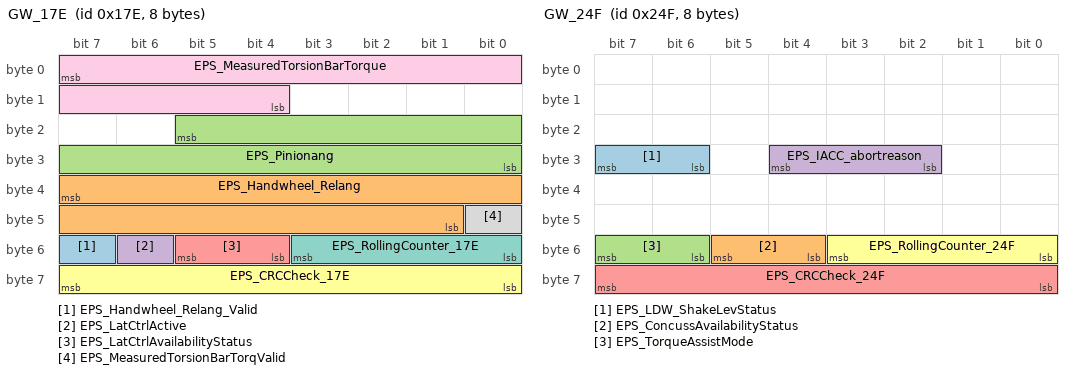
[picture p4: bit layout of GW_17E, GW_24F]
BO_ 382 GW_17E: 8 GW
 SG_ EPS_Handwheel_Relang_Valid : 55|1@0+ (1.0000000000,0.0000000000) [0.0000000000|1.0000000000] ""  LAS,mADC
 SG_ EPS_Handwheel_Relang : 39|15@0+ (0.1000000000,-1080.0000000000) [-1080.0000000000|1080.0000000000] "degree"  LAS,mADC
 SG_ EPS_Pinionang : 21|14@0+ (0.1000000000,-720.0000000000) [-720.0000000000|720.0000000000] "degree"  LAS,mADC
 SG_ EPS_LatCtrlActive : 54|1@0+ (1.0000000000,0.0000000000) [0.0000000000|1.0000000000] ""  LAS,mADC
 SG_ EPS_LatCtrlAvailabilityStatus : 53|2@0+ (1.0000000000,0.0000000000) [0.0000000000|3.0000000000] ""  LAS,mADC
 SG_ EPS_CRCCheck_17E : 63|8@0+ (1.0000000000,0.0000000000) [0.0000000000|255.0000000000] ""  ACC,LAS,mADC
 SG_ EPS_RollingCounter_17E : 51|4@0+ (1.0000000000,0.0000000000) [0.0000000000|15.0000000000] ""  ACC,LAS,mADC
 SG_ EPS_MeasuredTorsionBarTorqValid : 40|1@0+ (1.0000000000,0.0000000000) [0.0000000000|1.0000000000] ""  ACC,LAS,mADC
 SG_ EPS_MeasuredTorsionBarTorque : 7|12@0+ (0.0100000000,-20.4800000000) [-20.4800000000|20.4600000000] "Nm"  ACC,LAS,mADC

BO_ 442 ACC_1BA: 32 ACC
 SG_ ADS_Authernticator_1BA : 207|56@0+ (1.0000000000,0.0000000000) [0.0000000000|0.0000000000] ""  LAS,mADC,GW
 SG_ ADS_ResetFlag_1BA : 193|2@0+ (1.0000000000,0.0000000000) [0.0000000000|3.0000000000] ""  LAS,mADC,GW
 SG_ ADS_MesssageCounter_1BA : 199|6@0+ (1.0000000000,0.0000000000) [0.0000000000|63.0000000000] ""  LAS,mADC,GW
 SG_ ACC_LKAinhaitWarning : 111|2@0+ (1.0000000000,0.0000000000) [0.0000000000|3.0000000000] ""  LAS,mADC,GW
 SG_ ACC_CRCCheck_1BA_0 : 63|8@0+ (1.0000000000,0.0000000000) [0.0000000000|255.0000000000] ""  LAS,GW,mADC
 SG_ ACC_RollingCounter_1BA_0 : 51|4@0+ (1.0000000000,0.0000000000) [0.0000000000|15.0000000000] ""  LAS,GW,mADC
 SG_ ACC_LatAngReqActive : 35|1@0+ (1.0000000000,0.0000000000) [0.0000000000|1.0000000000] ""  LAS,GW,mADC
 SG_ ACC_LatAngReq : 17|14@0+ (0.1000000000,-720.0000000000) [-720.0000000000|720.0000000000] "degree"  LAS,GW,mADC
 SG_ ACC_MotorTorqueMinLimitRequest : 12|11@0+ (0.0200000000,-20.4800000000) [-20.4800000000|20.4400000000] "Nm"  LAS,GW,mADC
 SG_ ACC_MotorTorqueMaxLimitRequest : 7|11@0+ (0.0200000000,-20.4800000000) [-20.4800000000|20.4400000000] "Nm"  LAS,GW,mADC

BO_ 523 GW_20B: 64 GW
 SG_ ESP_AEBSpeedDropActive : 181|2@0+ (1.0000000000,0.0000000000) [0.0000000000|3.0000000000] ""  ACC,LAS,mADC
 SG_ ESP_VehicleStandstillVld : 286|1@0+ (1.0000000000,0.0000000000) [0.0000000000|1.0000000000] ""  ACC,LAS,mADC
 SG_ IBCU_BrkPedlStsGbVld : 303|2@0+ (1.0000000000,0.0000000000) [0.0000000000|2.0000000000] ""  ACC,LAS,APA,mADC
 SG_ IBCU_BrkPedoplStsGb : 295|8@0+ (1.0000000000,0.0000000000) [0.0000000000|255.0000000000] "%"  ACC,LAS,APA,mADC
 SG_ ESP_Vehicle_Speed_Reference : 103|13@0+ (0.0562500000,0.0000000000) [0.0000000000|360.0000000000] "km/h"  ACC,LAS,APA
 SG_ IBCU_precheckStatus : 309|2@0+ (1.0000000000,0.0000000000) [0.0000000000|3.0000000000] ""  ACC,LAS,APA
 SG_ IBCU_BrakeDiscHighTempWarning : 283|2@0+ (1.0000000000,0.0000000000) [0.0000000000|3.0000000000] ""  ACC,LAS,APA
 SG_ ESP_RollingCounter_20B : 491|4@0+ (1.0000000000,0.0000000000) [0.0000000000|15.0000000000] ""  ACC,LAS,mADC
 SG_ ESP_CRCCheck_20B : 503|16@0+ (1.0000000000,0.0000000000) [0.0000000000|65535.0000000000] ""  ACC,LAS,mADC
 SG_ Wheel_Speed_RR_Valid_Data : 71|1@0+ (1.0000000000,0.0000000000) [0.0000000000|1.0000000000] ""  APA,ACC,LAS,mADC
 SG_ Wheel_Speed_RR_Pulse : 231|8@0+ (1.0000000000,0.0000000000) [0.0000000000|254.0000000000] ""  APA,ACC,LAS,mADC
 SG_ Wheel_Speed_RR_Direction : 70|2@0+ (1.0000000000,0.0000000000) [0.0000000000|3.0000000000] ""  APA,ACC,LAS,mADC
 SG_ Wheel_Speed_RR_Data : 68|13@0+ (0.0562500000,0.0000000000) [0.0000000000|360.0000000000] "km/h"  APA,ACC,LAS,mADC
 SG_ Wheel_Speed_RL_Valid_Data : 87|1@0+ (1.0000000000,0.0000000000) [0.0000000000|1.0000000000] ""  APA,ACC,LAS,mADC
 SG_ Wheel_Speed_RL_Pulse : 239|8@0+ (1.0000000000,0.0000000000) [0.0000000000|254.0000000000] ""  APA,ACC,LAS,mADC
 SG_ Wheel_Speed_RL_Direction : 86|2@0+ (1.0000000000,0.0000000000) [0.0000000000|3.0000000000] ""  APA,ACC,LAS,mADC
 SG_ Wheel_Speed_RL_Data : 84|13@0+ (0.0562500000,0.0000000000) [0.0000000000|360.0000000000] "km/h"  APA,ACC,LAS,mADC
 SG_ Wheel_Speed_FR_Valid_Data : 7|1@0+ (1.0000000000,0.0000000000) [0.0000000000|1.0000000000] ""  APA,ACC,LAS,mADC
 SG_ Wheel_Speed_FR_Pulse : 223|8@0+ (1.0000000000,0.0000000000) [0.0000000000|254.0000000000] ""  APA,ACC,LAS,mADC
 SG_ Wheel_Speed_FR_Direction : 6|2@0+ (1.0000000000,0.0000000000) [0.0000000000|3.0000000000] ""  APA,ACC,LAS,mADC
 SG_ Wheel_Speed_FR_Data : 4|13@0+ (0.0562500000,0.0000000000) [0.0000000000|360.0000000000] "km/h"  APA,ACC,LAS,mADC
 SG_ Wheel_Speed_FL_Valid_Data : 23|1@0+ (1.0000000000,0.0000000000) [0.0000000000|1.0000000000] ""  APA,ACC,LAS,mADC
 SG_ Wheel_Speed_FL_Pulse : 215|8@0+ (1.0000000000,0.0000000000) [0.0000000000|254.0000000000] ""  APA,ACC,LAS,mADC
 SG_ Wheel_Speed_FL_Direction : 22|2@0+ (1.0000000000,0.0000000000) [0.0000000000|3.0000000000] ""  APA,ACC,LAS,mADC
 SG_ Wheel_Speed_FL_Data : 20|13@0+ (0.0562500000,0.0000000000) [0.0000000000|360.0000000000] "km/h"  APA,ACC,LAS,mADC
 SG_ ESP_VehicleStandstill : 267|1@0+ (1.0000000000,0.0000000000) [0.0000000000|1.0000000000] ""  APA,ACC,LAS,mADC
 SG_ ESP_VDCActive : 266|1@0+ (1.0000000000,0.0000000000) [0.0000000000|1.0000000000] ""  ACC,LAS,mADC
 SG_ ESP_TCSActive : 265|1@0+ (1.0000000000,0.0000000000) [0.0000000000|1.0000000000] ""  ACC,LAS,mADC
 SG_ ESP_RollingCounter_277 : 307|4@0+ (1.0000000000,0.0000000000) [0.0000000000|15.0000000000] ""  APA,ACC,LAS
 SG_ ESP_RollingCounter_258 : 243|4@0+ (1.0000000000,0.0000000000) [0.0000000000|15.0000000000] ""  APA,ACC,LAS
 SG_ ESP_RollingCounter_208 : 115|4@0+ (1.0000000000,0.0000000000) [0.0000000000|15.0000000000] ""  APA,ACC,LAS
 SG_ ESP_RollingCounter_206 : 51|4@0+ (1.0000000000,0.0000000000) [0.0000000000|15.0000000000] ""  APA,ACC,LAS
 SG_ ESP_QDCACC : 279|2@0+ (1.0000000000,0.0000000000) [0.0000000000|3.0000000000] ""  ACC,LAS,mADC
 SG_ ESP_PrefillAvailable : 259|1@0+ (1.0000000000,0.0000000000) [0.0000000000|1.0000000000] ""  ACC,LAS,APA,mADC
 SG_ ESP_PrefillActive : 260|1@0+ (1.0000000000,0.0000000000) [0.0000000000|1.0000000000] ""  ACC,LAS,APA,mADC
 SG_ ESP_OnlyABSActive : 264|1@0+ (1.0000000000,0.0000000000) [0.0000000000|1.0000000000] ""  ACC,LAS,mADC
 SG_ ESP_MasCylBrakePressureValid : 199|1@0+ (1.0000000000,0.0000000000) [0.0000000000|1.0000000000] ""  APA,ACC,LAS,mADC
 SG_ ESP_MasCylBrakePressure : 195|12@0+ (0.1000000000,0.0000000000) [0.0000000000|250.0000000000] "Bar"  APA,ACC,LAS,mADC
 SG_ ESP_HDC_STATUS : 274|2@0+ (1.0000000000,0.0000000000) [0.0000000000|3.0000000000] ""  ACC,LAS,mADC
 SG_ ESP_CRCCheck_277 : 319|8@0+ (1.0000000000,0.0000000000) [0.0000000000|255.0000000000] ""  APA,ACC,LAS
 SG_ ESP_CRCCheck_258 : 255|8@0+ (1.0000000000,0.0000000000) [0.0000000000|255.0000000000] ""  ACC,LAS,APA
 SG_ ESP_CRCCheck_208 : 127|8@0+ (1.0000000000,0.0000000000) [0.0000000000|255.0000000000] ""  APA,ACC,LAS
 SG_ ESP_CRCCheck_206 : 63|8@0+ (1.0000000000,0.0000000000) [0.0000000000|255.0000000000] ""  APA,ACC,LAS
 SG_ ESP_CDD_Available : 268|1@0+ (1.0000000000,0.0000000000) [0.0000000000|1.0000000000] ""  ACC,LAS,mADC
 SG_ ESP_CDD_Active : 269|1@0+ (1.0000000000,0.0000000000) [0.0000000000|1.0000000000] ""  ACC,LAS,mADC
 SG_ ESP_BrakeOverHeatBrakeDiscTemp : 270|1@0+ (1.0000000000,0.0000000000) [0.0000000000|1.0000000000] ""  ACC,LAS,mADC
 SG_ ESP_BrakeForce : 263|1@0+ (1.0000000000,0.0000000000) [0.0000000000|1.0000000000] ""  ACC,LAS,APA,mADC
 SG_ ESP_AWBavailable : 271|1@0+ (1.0000000000,0.0000000000) [0.0000000000|1.0000000000] ""  ACC,LAS,mADC
 SG_ ESP_AWBactive : 256|1@0+ (1.0000000000,0.0000000000) [0.0000000000|1.0000000000] ""  ACC,LAS,mADC
 SG_ ESP_AutoHoldAvailable : 246|1@0+ (1.0000000000,0.0000000000) [0.0000000000|1.0000000000] ""  LAS,ACC
 SG_ ESP_AutoHoldActive : 247|1@0+ (1.0000000000,0.0000000000) [0.0000000000|1.0000000000] ""  LAS,ACC,mADC
 SG_ ESP_AEBdecActive : 257|1@0+ (1.0000000000,0.0000000000) [0.0000000000|1.0000000000] ""  ACC,LAS,mADC
 SG_ ESP_AEBAvailable : 258|1@0+ (1.0000000000,0.0000000000) [0.0000000000|1.0000000000] ""  ACC,LAS,mADC
 SG_ ESP_ABAavailable : 261|1@0+ (1.0000000000,0.0000000000) [0.0000000000|1.0000000000] ""  ACC,LAS,mADC
 SG_ ESP_ABAactive : 262|1@0+ (1.0000000000,0.0000000000) [0.0000000000|1.0000000000] ""  ACC,LAS,mADC

BO_ 591 GW_24F: 8 GW
 SG_ EPS_LDW_ShakeLevStatus : 31|2@0+ (1.0000000000,0.0000000000) [0.0000000000|3.0000000000] ""  LAS,mADC
 SG_ EPS_ConcussAvailabilityStatus : 53|2@0+ (1.0000000000,0.0000000000) [0.0000000000|3.0000000000] ""  ACC,LAS,APA,mADC
 SG_ EPS_TorqueAssistMode : 55|2@0+ (1.0000000000,0.0000000000) [0.0000000000|3.0000000000] ""  ACC,LAS,APA,mADC
 SG_ EPS_IACC_abortreason : 28|3@0+ (1.0000000000,0.0000000000) [0.0000000000|7.0000000000] ""  LAS,APA,mADC
 SG_ EPS_CRCCheck_24F : 63|8@0+ (1.0000000000,0.0000000000) [0.0000000000|255.0000000000] ""  ACC,LAS,APA,mADC
 SG_ EPS_RollingCounter_24F : 51|4@0+ (1.0000000000,0.0000000000) [0.0000000000|15.0000000000] ""  ACC,LAS,APA,mADC

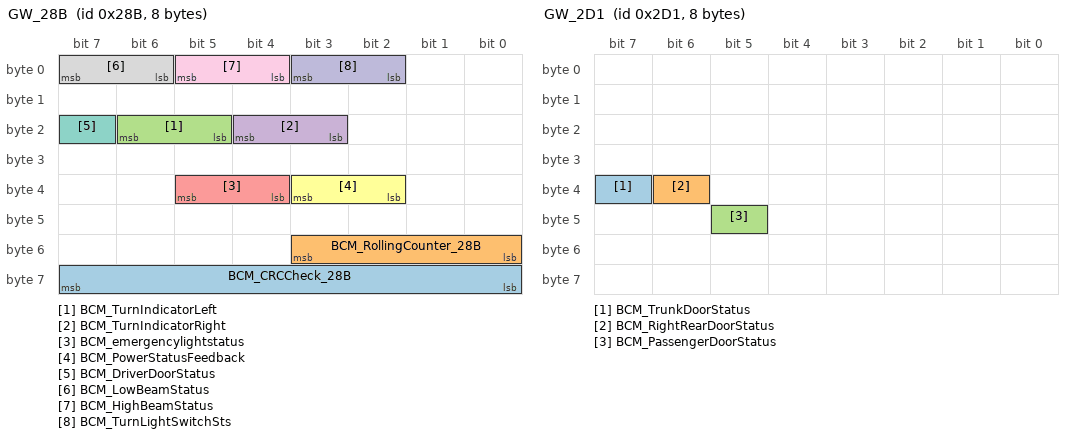
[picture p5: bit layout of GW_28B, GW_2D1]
BO_ 651 GW_28B: 8 GW
 SG_ BCM_CRCCheck_28B : 63|8@0+ (1.0000000000,0.0000000000) [0.0000000000|255.0000000000] ""  LAS,ACC,mADC
 SG_ BCM_RollingCounter_28B : 51|4@0+ (1.0000000000,0.0000000000) [0.0000000000|15.0000000000] ""  LAS,ACC,mADC
 SG_ BCM_TurnIndicatorLeft : 22|2@0+ (1.0000000000,0.0000000000) [0.0000000000|3.0000000000] ""  ACC,LAS,APA,mADC
 SG_ BCM_TurnIndicatorRight : 20|2@0+ (1.0000000000,0.0000000000) [0.0000000000|3.0000000000] ""  ACC,LAS,APA,mADC
 SG_ BCM_emergencylightstatus : 37|2@0+ (1.0000000000,0.0000000000) [0.0000000000|3.0000000000] ""  LAS,APA,mADC,ACC
 SG_ BCM_PowerStatusFeedback : 35|2@0+ (1.0000000000,0.0000000000) [0.0000000000|3.0000000000] ""  APA,ACC,LAS,mADC
 SG_ BCM_DriverDoorStatus : 23|1@0+ (1.0000000000,0.0000000000) [0.0000000000|1.0000000000] ""  APA,ACC,LAS,mADC
 SG_ BCM_LowBeamStatus : 7|2@0+ (1.0000000000,0.0000000000) [0.0000000000|3.0000000000] ""  LAS,APA,mADC
 SG_ BCM_HighBeamStatus : 5|2@0+ (1.0000000000,0.0000000000) [0.0000000000|3.0000000000] ""  LAS,APA,mADC
 SG_ BCM_TurnLightSwitchSts : 3|2@0+ (1.0000000000,0.0000000000) [0.0000000000|3.0000000000] ""  APA,LAS,ACC,mADC

BO_ 721 GW_2D1: 8 GW
 SG_ BCM_TrunkDoorStatus : 39|1@0+ (1.0000000000,0.0000000000) [0.0000000000|1.0000000000] ""  ACC,LAS,APA,mADC
 SG_ BCM_RightRearDoorStatus : 38|1@0+ (1.0000000000,0.0000000000) [0.0000000000|1.0000000000] ""  ACC,LAS,APA,mADC
 SG_ BCM_PassengerDoorStatus : 45|1@0+ (1.0000000000,0.0000000000) [0.0000000000|1.0000000000] ""  ACC,LAS,APA,mADC

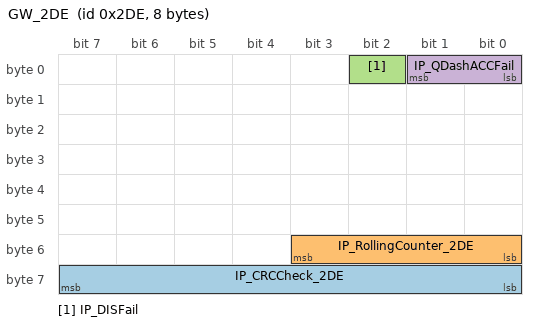
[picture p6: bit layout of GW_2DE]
BO_ 734 GW_2DE: 8 GW
 SG_ IP_CRCCheck_2DE : 63|8@0+ (1.0000000000,0.0000000000) [0.0000000000|255.0000000000] ""  ACC,APA,LAS,mADC
 SG_ IP_RollingCounter_2DE : 51|4@0+ (1.0000000000,0.0000000000) [0.0000000000|15.0000000000] ""  ACC,APA,LAS,mADC
 SG_ IP_DISFail : 2|1@0+ (1.0000000000,0.0000000000) [0.0000000000|1.0000000000] ""  ACC,LAS,mADC
 SG_ IP_QDashACCFail : 1|2@0+ (1.0000000000,0.0000000000) [0.0000000000|3.0000000000] ""  ACC,LAS,mADC

BO_ 794 ACC_31A: 64 ACC
 SG_ AD_AEBSysFltSts : 328|3@0+ (1.0000000000,0.0000000000) [0.0000000000|7.0000000000] ""  LAS,mADC,GW
 SG_ AD_FCWSysFltSts : 331|3@0+ (1.0000000000,0.0000000000) [0.0000000000|7.0000000000] ""  LAS,mADC,GW
 SG_ ACC_LDWSenStyle : 299|2@0+ (1.0000000000,0.0000000000) [0.0000000000|3.0000000000] ""  LAS,GW,mADC
 SG_ ACC_AEBTargetLatRelSpeed : 293|10@0+ (0.1250000000,-64.0000000000) [-64.0000000000|63.8750000000] "m/s"  LAS,GW,mADC
 SG_ ACC_HandsoffWarningExitReason : 42|3@0+ (1.0000000000,0.0000000000) [0.0000000000|7.0000000000] ""  LAS,GW
 SG_ ACC_LngTakeOverReqReason : 232|5@0+ (1.0000000000,0.0000000000) [0.0000000000|31.0000000000] ""  LAS,GW,mADC
 SG_ ACC_ELKAlert : 25|2@0+ (1.0000000000,0.0000000000) [0.0000000000|3.0000000000] ""  LAS,GW,mADC
 SG_ ACC_CRCCheck_367 : 255|8@0+ (1.0000000000,0.0000000000) [0.0000000000|255.0000000000] ""  LAS,GW
 SG_ ACC_RollingCounter_367 : 243|4@0+ (1.0000000000,0.0000000000) [0.0000000000|15.0000000000] ""  LAS,GW
 SG_ ACC_LatPathHeadingAngle : 227|11@0- (0.1000000000,0.0000000000) [-90.0000000000|90.0000000000] "degree"  LAS,GW,mADC
 SG_ ACC_LatPathDY : 221|10@0- (0.0100000000,0.0000000000) [-5.0000000000|5.0000000000] "m"  LAS,GW
 SG_ ACC_ELKEnableStatus : 222|1@0+ (1.0000000000,0.0000000000) [0.0000000000|1.0000000000] ""  LAS,GW,mADC
 SG_ ACC_ELKInterventionMode : 210|2@0+ (1.0000000000,0.0000000000) [0.0000000000|3.0000000000] ""  LAS,GW,mADC
 SG_ ACC_ELKMode : 213|3@0+ (1.0000000000,0.0000000000) [0.0000000000|7.0000000000] ""  LAS,GW,mADC
 SG_ ACC_CRCCheck_30D : 191|8@0+ (1.0000000000,0.0000000000) [0.0000000000|255.0000000000] ""  LAS,GW
 SG_ ACC_RollingCounter_30D : 179|4@0+ (1.0000000000,0.0000000000) [0.0000000000|15.0000000000] ""  LAS,GW
 SG_ ACC_RRLaneDetection : 174|2@0+ (1.0000000000,0.0000000000) [0.0000000000|3.0000000000] ""  LAS,GW,mADC
 SG_ ACC_LLLaneDetection : 167|2@0+ (1.0000000000,0.0000000000) [0.0000000000|3.0000000000] ""  LAS,GW,mADC
 SG_ ACC_HighBeamControl : 182|2@0+ (1.0000000000,0.0000000000) [0.0000000000|3.0000000000] ""  LAS,GW
 SG_ ACC_TargetBasedLateralControl : 150|2@0+ (1.0000000000,0.0000000000) [0.0000000000|3.0000000000] ""  LAS,GW,mADC
 SG_ ACC_IACCHWATextInfoForDriver : 128|6@0+ (1.0000000000,0.0000000000) [0.0000000000|63.0000000000] ""  LAS,GW,mADC
 SG_ ACC_EmergencyLightingRequest : 148|2@0+ (1.0000000000,0.0000000000) [0.0000000000|3.0000000000] ""  LAS,GW,mADC
 SG_ ACC_DriverHandsOffStatus : 137|2@0+ (1.0000000000,0.0000000000) [0.0000000000|3.0000000000] ""  LAS,GW,mADC
 SG_ ACC_IACCHWAMode : 135|3@0+ (1.0000000000,0.0000000000) [0.0000000000|7.0000000000] ""  LAS,GW,APA,mADC
 SG_ ACC_CRCCheck_30A : 127|8@0+ (1.0000000000,0.0000000000) [0.0000000000|255.0000000000] ""  LAS,GW
 SG_ ACC_RollingCounter_30A : 115|4@0+ (1.0000000000,0.0000000000) [0.0000000000|15.0000000000] ""  LAS,GW
 SG_ ACC_LaneChangeStatus : 117|2@0+ (1.0000000000,0.0000000000) [0.0000000000|3.0000000000] ""  LAS,GW,mADC
 SG_ ACC_RoadCurvatureFar : 109|7@0+ (0.0005000000,-0.0300000000) [-0.0300000000|0.0300000000] "1/m"  LAS,GW
 SG_ ACC_RoadCurvatureNear : 100|7@0+ (0.0005000000,-0.0300000000) [-0.0300000000|0.0300000000] "1/m"  LAS,GW
 SG_ ACC_RoadCurvature : 91|7@0+ (0.0005000000,-0.0300000000) [-0.0300000000|0.0300000000] "1/m"  LAS,GW
 SG_ ACC_IACCHWAEnable : 79|2@0+ (1.0000000000,0.0000000000) [0.0000000000|3.0000000000] ""  LAS,GW,mADC
 SG_ ACC_RLaneMarkerType : 71|4@0+ (1.0000000000,0.0000000000) [0.0000000000|15.0000000000] ""  LAS,GW,mADC
 SG_ ACC_LLaneMarkerType : 95|4@0+ (1.0000000000,0.0000000000) [0.0000000000|15.0000000000] ""  LAS,GW,mADC
 SG_ ACC_HostLaneRightStatus : 87|4@0+ (1.0000000000,0.0000000000) [0.0000000000|15.0000000000] ""  LAS,GW,mADC
 SG_ ACC_HostLaneLeftStatus : 83|4@0+ (1.0000000000,0.0000000000) [0.0000000000|15.0000000000] ""  LAS,GW,mADC
 SG_ ACC_LASWarningModeSelectionSts : 74|3@0+ (1.0000000000,0.0000000000) [0.0000000000|7.0000000000] ""  GW,LAS,mADC
 SG_ ACC_LASModeSelectionStatus : 66|3@0+ (1.0000000000,0.0000000000) [0.0000000000|7.0000000000] ""  LAS,GW,mADC
 SG_ ACC_CRCCheck_36D : 63|8@0+ (1.0000000000,0.0000000000) [0.0000000000|255.0000000000] ""  LAS,GW
 SG_ ACC_RollingCounter_36D : 51|4@0+ (1.0000000000,0.0000000000) [0.0000000000|15.0000000000] ""  LAS,GW
 SG_ ACC_FRadarFailureStatus : 53|2@0+ (1.0000000000,0.0000000000) [0.0000000000|3.0000000000] ""  LAS,GW,mADC
 SG_ ACC_AEBTargetLatRange : 21|10@0+ (0.1000000000,-50.0000000000) [-50.0000000000|50.0000000000] "m"  LAS,GW,mADC
 SG_ ACC_AEBTargetRelSpeed : 14|9@0+ (1.0000000000,-250.0000000000) [-250.0000000000|250.0000000000] "km/h"  LAS,GW,mADC
 SG_ ACC_AEBTargetLngRange : 7|9@0+ (0.5000000000,-70.0000000000) [-70.0000000000|180.0000000000] "m"  LAS,GW,mADC
 SG_ ACC_Voiceinfo : 47|5@0+ (1.0000000000,0.0000000000) [0.0000000000|31.0000000000] ""  LAS,GW,mADC
 SG_ ACC_AEBTargetmode : 33|2@0+ (1.0000000000,0.0000000000) [0.0000000000|3.0000000000] ""  LAS,GW,mADC
 SG_ ACC_AEBTextInfo : 37|4@0+ (1.0000000000,0.0000000000) [0.0000000000|15.0000000000] ""  LAS,GW,mADC
 SG_ ACC_AEBStatus : 39|2@0+ (1.0000000000,0.0000000000) [0.0000000000|3.0000000000] ""  LAS,GW,mADC

BO_ 853 GW_355: 8 GW
 SG_ EMS_CRCCheck_355 : 63|8@0+ (1.0000000000,0.0000000000) [0.0000000000|255.0000000000] ""  ACC,LAS
 SG_ EMS_RollingCounter_355 : 51|4@0+ (1.0000000000,0.0000000000) [0.0000000000|15.0000000000] ""  ACC,LAS

CM_ BO_ 898  " ";
CM_ SG_ 898 ACC_Target5ZoneID  " ";
CM_ SG_ 898 ACC_Target5HeadingAngle  " ";
CM_ SG_ 898 ACC_Target5Direction  " ";
CM_ SG_ 898 ACC_Target5LatRange  " ";
CM_ SG_ 898 ACC_Target5LngRange  " ";
CM_ SG_ 898 ACC_Target5Type  " ";
CM_ SG_ 898 ACC_Target5ID  " ";
CM_ SG_ 898 ACC_Target5Detection  " ";
CM_ SG_ 898 ACC_Target4ZoneID  "ACC 主控则ACC发送，LAS 主控则LAS发送 ";
CM_ SG_ 898 ACC_Target4HeadingAngle  "ACC 主控则ACC发送，LAS 主控则LAS发送 ";
CM_ SG_ 898 ACC_Target4Direction  "ACC 主控则ACC发送，LAS 主控则LAS发送 ";
CM_ SG_ 898 ACC_Target4LatRange  "ACC 主控则ACC发送，LAS 主控则LAS发送 ";
CM_ SG_ 898 ACC_Target4LngRange  "ACC 主控则ACC发送，LAS 主控则LAS发送 ";
CM_ SG_ 898 ACC_Target4Type  "ACC 主控则ACC发送，LAS 主控则LAS发送 ";
CM_ SG_ 898 ACC_Target4ID  "ACC 主控则ACC发送，LAS 主控则LAS发送 ";
CM_ SG_ 898 ACC_Target4Detection  "ACC 主控则ACC发送，LAS 主控则LAS发送 ";
CM_ SG_ 898 ACC_Target3ZoneID  "ACC 主控则ACC发送，LAS 主控则LAS发送 ";
CM_ SG_ 898 ACC_Target3HeadingAngle  "ACC 主控则ACC发送，LAS 主控则LAS发送 ";
CM_ SG_ 898 ACC_Target3Direction  "ACC 主控则ACC发送，LAS 主控则LAS发送 ";
CM_ SG_ 898 ACC_Target3LatRange  "ACC 主控则ACC发送，LAS 主控则LAS发送 ";
CM_ SG_ 898 ACC_Target3LngRange  "ACC 主控则ACC发送，LAS 主控则LAS发送 ";
CM_ SG_ 898 ACC_Target3Type  "ACC 主控则ACC发送，LAS 主控则LAS发送 ";
CM_ SG_ 898 ACC_Target3ID  "ACC 主控则ACC发送，LAS 主控则LAS发送 ";
CM_ SG_ 898 ACC_Target3Detection  "ACC 主控则ACC发送，LAS 主控则LAS发送 ";
CM_ SG_ 898 ACC_Target2ZoneID  "ACC 主控则ACC发送，LAS 主控则LAS发送 ";
CM_ SG_ 898 ACC_Target2HeadingAngle  "ACC 主控则ACC发送，LAS 主控则LAS发送 ";
CM_ SG_ 898 ACC_Target2Direction  "ACC 主控则ACC发送，LAS 主控则LAS发送 ";
CM_ SG_ 898 ACC_Target2LatRange  "ACC 主控则ACC发送，LAS 主控则LAS发送 ";
CM_ SG_ 898 ACC_Target2LngRange  "ACC 主控则ACC发送，LAS 主控则LAS发送 ";
CM_ SG_ 898 ACC_Target2Type  "ACC 主控则ACC发送，LAS 主控则LAS发送 ";
CM_ SG_ 898 ACC_Target2ID  "ACC 主控则ACC发送，LAS 主控则LAS发送 ";
CM_ SG_ 898 ACC_Target2Detection  "ACC 主控则ACC发送，LAS 主控则LAS发送 ";
CM_ SG_ 898 ACC_Target1ZoneID  "ACC 主控则ACC发送，LAS 主控则LAS发送 ";
CM_ SG_ 898 ACC_Target1HeadingAngle  "ACC 主控则ACC发送，LAS 主控则LAS发送 ";
CM_ SG_ 898 ACC_Target1Direction  "ACC 主控则ACC发送，LAS 主控则LAS发送 ";
CM_ SG_ 898 ACC_Target1LatRange  "ACC 主控则ACC发送，LAS 主控则LAS发送 ";
CM_ SG_ 898 ACC_Target1LngRange  "ACC 主控则ACC发送，LAS 主控则LAS发送 ";
CM_ SG_ 898 ACC_Target1Type  "ACC 主控则ACC发送，LAS 主控则LAS发送 ";
CM_ SG_ 898 ACC_Target1ID  "ACC 主控则ACC发送，LAS 主控则LAS发送 ";
CM_ SG_ 898 ACC_Target1Detection  "ACC 主控则ACC发送，LAS 主控则LAS发送 ";
CM_ SG_ 898 ACC_RollingCounter_3E6  " ";
CM_ SG_ 898 ACC_CRCCheck_3E6  "ACC 主控则ACC发送，LAS 主控则LAS发送 ";
CM_ SG_ 898 ACC_CRCCheck_35C  "ACC 主控则ACC发送，LAS 主控则LAS发送 ";
CM_ SG_ 898 ACC_RollingCounter_35C  "ACC 主控则ACC发送，LAS 主控则LAS发送 ";
CM_ SG_ 898 ACC_CRCCheck_35D  " ";
CM_ SG_ 898 ACC_RollingCounter_35D  " ";
CM_ SG_ 898 ACC_LaneEquationStatus  "ACC 主控则ACC发送，LAS 主控则LAS发送 ";
CM_ SG_ 898 ACC_LaneEquationC3  "ACC 主控则ACC发送，LAS 主控则LAS发送 ";
CM_ SG_ 898 ACC_LaneEquationC2  "ACC 主控则ACC发送，LAS 主控则LAS发送 ";
CM_ SG_ 898 ACC_LaneEquationC1  "ACC 主控则ACC发送，LAS 主控则LAS发送 ";
CM_ SG_ 898 ACC_LaneQuality  "ACC 主控则ACC发送，LAS 主控则LAS发送 ";

CM_ BO_ 676  " ";
CM_ SG_ 676 LCDAR_RCTBStatus  "ACC 主控则ACC接收，LAS 主控则LAS接收 ";
CM_ SG_ 676 LCDAR_CRCCheck_2AF  " ";
CM_ SG_ 676 LCDAR_RollingCounter_2AF  "rolling counter ";
CM_ SG_ 676 LCDAR_ELK_oAlert  " ";
CM_ SG_ 676 LCDAR_ELK_oStatus  " ";
CM_ SG_ 676 LCDAR_Left_ELK_oAlert  " ";
CM_ SG_ 676 LCDAR_RCTBActive  "ACC 主控则ACC接收，LAS 主控则LAS接收 ";
CM_ SG_ 676 LCDAR_RCTBTargetDecel  "ACC 主控则ACC接收，LAS 主控则LAS接收 ";

CM_ BO_ 1426  " ";
CM_ SG_ 1426 LAS_NotSleep_BYTE7BIT1  " ";
CM_ SG_ 1426 LAS_NotSleep_BYTE7BIT0  " ";
CM_ SG_ 1426 LAS_WakeUp_BYTE4BIT1  " ";
CM_ SG_ 1426 LAS_WakeUp_BYTE4BIT0  " ";

CM_ BO_ 80  " ";
CM_ SG_ 80 SRS_DriverBuckleSwitchStatus  " ";
CM_ SG_ 80 SRS_RollingCounter_id050  "ACM接收为AT专用 ";

CM_ BO_ 368  " ";
CM_ SG_ 368 EPS_ActualMotorTorq  " ";
CM_ SG_ 368 EPS_CRCCheck_170  "平台为10ms，CD569特例为8ms ";
CM_ SG_ 368 EPS_RollingCounter_170  "平台为10ms，CD569特例为8ms ";
CM_ SG_ 368 EPS_ActualTorsionBarTorq  "平台为10ms，CD569特例为8ms ";
CM_ SG_ 368 EPS_MinSafetyTorsionBarTorq  "平台为10ms，CD569特例为8ms ";
CM_ SG_ 368 EPS_MaxSafetyTorsionBarTorq  "平台为10ms，CD569特例为8ms ";

CM_ BO_ 384  " ";
CM_ SG_ 384 SAS_SteeringAngle  "APA配置接收方无BDC ";

CM_ BO_ 580  " ";
CM_ SG_ 580 ACC_AEBSpeedDropLevel  " ";
CM_ SG_ 580 ADS_ResetFlag_244  " ";
CM_ SG_ 580 ADS_Authernticator_244  " ";
CM_ SG_ 580 ADS_MesssageCounter_244  " ";
CM_ SG_ 580 ADS_EOMTOReq  "ACC 主控则ACC发送，LAS 主控则LAS发送 ";
CM_ SG_ 580 ACC_HandsOnReq  "ACC 主控则ACC发送，LAS 主控则LAS发送 ";
CM_ SG_ 580 ACC_LatTakeoverReq  "ACC 主控则ACC发送，LAS 主控则LAS发送 ";
CM_ SG_ 580 ACC_LngTakeOverReq  "ACC 主控则ACC发送，LAS 主控则LAS发送 ";
CM_ SG_ 580 ACC_LDWShakeLevStatus  "ACC 主控则ACC发送，LAS 主控则LAS发送 ";
CM_ SG_ 580 ACC_TextInfoForDriver  "ACC 主控则ACC发送，LAS 主控则LAS发送 ";
CM_ SG_ 580 ADS__RollingCounter_244  "ACC 主控则ACC发送，LAS 主控则LAS发送 ";
CM_ SG_ 580 ADS_CRCCheck_244  "ACC 主控则ACC发送，LAS 主控则LAS发送 ";
CM_ SG_ 580 ACC_CRCCheck_25E  "ACC 主控则ACC发送，LAS 主控则LAS发送 ";
CM_ SG_ 580 ACC_RollingCounter_25E  "ACC 主控则ACC发送，LAS 主控则LAS发送 ";
CM_ SG_ 580 ACC_AEBCtrlType  "ACC 主控则ACC发送，LAS 主控则LAS发送 ";
CM_ SG_ 580 ACC_FuelCutOffPrevention  " ";
CM_ SG_ 580 ACC_AccTrqReq  "ACC 主控则ACC发送，LAS 主控则LAS发送 ";
CM_ SG_ 580 ACC_AccTrqReqActive  "ACC 主控则ACC发送，LAS 主控则LAS发送 ";
CM_ SG_ 580 ACC_AEBVehilceHoldReq  "ACC 主控则ACC发送，LAS 主控则LAS发送 ";
CM_ SG_ 580 ACC_FCWPreWarning  "ACC 主控则ACC发送，LAS 主控则LAS发送 ";
CM_ SG_ 580 ACC_FCWLatentWarning  "ACC 主控则ACC发送，LAS 主控则LAS发送 ";
CM_ SG_ 580 ACC_FCWActive  "ACC 主控则ACC发送，LAS 主控则LAS发送 ";
CM_ SG_ 580 ACC_PrefillActive  "ACC 主控则ACC发送，LAS 主控则LAS发送 ";
CM_ SG_ 580 ACC_AWBActive  "ACC 主控则ACC发送，LAS 主控则LAS发送 ";
CM_ SG_ 580 ACC_AWBlevel  "ACC 主控则ACC发送，LAS 主控则LAS发送 ";
CM_ SG_ 580 ACC_ABAActive  "ACC 主控则ACC发送，LAS 主控则LAS发送 ";
CM_ SG_ 580 ACC_ABAlevel  "ACC 主控则ACC发送，LAS 主控则LAS发送 ";
CM_ SG_ 580 ACC_AEBActive  "ACC 主控则ACC发送，LAS 主控则LAS发送 ";
CM_ SG_ 580 ACC_AEBTargetDeceleration  "ACC 主控则ACC发送，LAS 主控则LAS发送 ";
CM_ SG_ 580 ACC_EmergencyDataRrdReq  "ACC 主控则ACC发送，LAS 主控则LAS发送 ";
CM_ SG_ 580 ACC_CRCCheck_24E  "ACC 主控则ACC发送，LAS 主控则LAS发送 ";
CM_ SG_ 580 ACC_RollingCounter_24E  "ACC 主控则ACC发送，LAS 主控则LAS发送 ";
CM_ SG_ 580 ACC_Driveoff_Request  "ACC 主控则ACC发送，LAS 主控则LAS发送 ";
CM_ SG_ 580 ACC_ACCMode  "ACC 主控则ACC发送，LAS 主控则LAS发送 ";
CM_ SG_ 580 ACC_CDDActive  "ACC 主控则ACC发送，LAS 主控则LAS发送 ";
CM_ SG_ 580 ACC_EngineStartStopRequest  "1、0x1= EngineAutoStopRequest (请求发动机进入STOP状态)；
0x2=EngineAutoStartRequest(请求发动机进入到START状态)；
2、ACC 主控则ACC发送，LAS 主控则LAS发送 ";
CM_ SG_ 580 ACC_DecToStop  "ACC 主控则ACC发送，LAS 主控则LAS发送 ";
CM_ SG_ 580 ACC_TCUCreepProhibition  "ACC 主控则ACC发送，LAS 主控则LAS发送 ";
CM_ SG_ 580 ACC_LKAStatus  "ACC 主控则ACC发送，LAS 主控则LAS发送 ";
CM_ SG_ 580 ACC_LDWVibrationWarningReq  "ACC 主控则ACC发送，LAS 主控则LAS发送，其余由APA或AVM发送 ";
CM_ SG_ 580 ACC_LDWStatus  "ACC 主控则ACC发送，LAS 主控则LAS发送，其余由APA或AVM发送 ";
CM_ SG_ 580 ACC_ACCTargetAcceleration  "1、ACC target acceleration for transmission.
2、ACC 主控则ACC发送，LAS 主控则LAS发送 ";

CM_ BO_ 664  " ";

CM_ BO_ 775  " ";
CM_ SG_ 775 ACC_CSLmodeStatus  " ";
CM_ SG_ 775 ACC_CSLEnableStatus  " ";
CM_ SG_ 775 ACC_AEBTargetSelected  "同C236 ";
CM_ SG_ 775 ACC_AEBFeatureConfig  "同C236 ";
CM_ SG_ 775 ACC_Line_RR_Id  "同一条车线未打断车线ID不变，一定距离内车线ID不重复 ";
CM_ SG_ 775 ACC_Line_R_Id  "同一条车线未打断车线ID不变，一定距离内车线ID不重复 ";
CM_ SG_ 775 ACC_Line_LL_Id  "同一条车线未打断车线ID不变，一定距离内车线ID不重复 ";
CM_ SG_ 775 ACC_Line_L_Id  "同一条车线未打断车线ID不变，一定距离内车线ID不重复 ";
CM_ SG_ 775 ACC_RLaneDistanceFus  "ACC 主控则ACC发送，LAS 主控则LAS发送 ";
CM_ SG_ 775 ACC_LLaneDistanceFus  "ACC 主控则ACC发送，LAS 主控则LAS发送 ";
CM_ SG_ 775 ACC_RRLaneDis  "ACC 主控则ACC发送，LAS 主控则LAS发送 ";
CM_ SG_ 775 ACC_LLLaneDis  "ACC 主控则ACC发送，LAS 主控则LAS发送 ";
CM_ SG_ 775 ACC_Target7ZoneID  "ACC 主控则ACC发送，LAS 主控则LAS发送 ";
CM_ SG_ 775 ACC_Target7HeadingAngle  "ACC 主控则ACC发送，LAS 主控则LAS发送 ";
CM_ SG_ 775 ACC_Target7Direction  "ACC 主控则ACC发送，LAS 主控则LAS发送 ";
CM_ SG_ 775 ACC_Target7LatRange  "ACC 主控则ACC发送，LAS 主控则LAS发送 ";
CM_ SG_ 775 ACC_Target7LngRange  "ACC 主控则ACC发送，LAS 主控则LAS发送 ";
CM_ SG_ 775 ACC_Target7Type  "ACC 主控则ACC发送，LAS 主控则LAS发送 ";
CM_ SG_ 775 ACC_Target7ID  "ACC 主控则ACC发送，LAS 主控则LAS发送 ";
CM_ SG_ 775 ACC_Target7Detection  "ACC 主控则ACC发送，LAS 主控则LAS发送 ";
CM_ SG_ 775 ACC_Target6ZoneID  "ACC 主控则ACC发送，LAS 主控则LAS发送 ";
CM_ SG_ 775 ACC_Target6HeadingAngle  "ACC 主控则ACC发送，LAS 主控则LAS发送 ";
CM_ SG_ 775 ACC_Target6Direction  "ACC 主控则ACC发送，LAS 主控则LAS发送 ";
CM_ SG_ 775 ACC_Target6LatRange  "ACC 主控则ACC发送，LAS 主控则LAS发送 ";
CM_ SG_ 775 ACC_Target6LngRange  "ACC 主控则ACC发送，LAS 主控则LAS发送 ";
CM_ SG_ 775 ACC_Target6Type  "ACC 主控则ACC发送，LAS 主控则LAS发送 ";
CM_ SG_ 775 ACC_Target6ID  "ACC 主控则ACC发送，LAS 主控则LAS发送 ";
CM_ SG_ 775 ACC_Target6Detection  "ACC 主控则ACC发送，LAS 主控则LAS发送 ";
CM_ SG_ 775 ACC_AEBEnable  "ACC 主控则ACC发送，LAS 主控则LAS发送 ";
CM_ SG_ 775 ACC_VehicleStartRemindSts  "ACC 主控则ACC发送，LAS 主控则LAS发送 ";
CM_ SG_ 775 ACC_CRCCheck_35F  "ACC 主控则ACC发送，LAS 主控则LAS发送 ";
CM_ SG_ 775 ACC_RollingCounter_35F  "ACC 主控则ACC发送，LAS 主控则LAS发送 ";
CM_ SG_ 775 ACC_CSLAEnableStatus  "ACC 主控则ACC发送，LAS 主控则LAS发送 ";
CM_ SG_ 775 ACC_CSLSetReq  "ACC 主控则ACC发送，LAS 主控则LAS发送 ";
CM_ SG_ 775 ACC_CRCCheck_344  "ACC 主控则ACC发送，LAS 主控则LAS发送 ";
CM_ SG_ 775 ACC_RollingCounter_344  "ACC 主控则ACC发送，LAS 主控则LAS发送 ";
CM_ SG_ 775 ACC_CRCCheck_322  "ACC 主控则ACC发送，LAS 主控则LAS发送 ";
CM_ SG_ 775 ACC_RollingCounter_322  "ACC 主控则ACC发送，LAS 主控则LAS发送 ";
CM_ SG_ 775 ACC_ACCTargetRelSpd  "ACC 主控则ACC发送，LAS 主控则LAS发送 ";
CM_ SG_ 775 ACC_CRCCheck_35E  "ACC 主控则ACC发送，LAS 主控则LAS发送 ";
CM_ SG_ 775 ACC_RollingCounter_35E  "ACC 主控则ACC发送，LAS 主控则LAS发送 ";
CM_ SG_ 775 ACC_FCWSettingStatus  "ACC 主控则ACC发送，LAS 主控则LAS发送 ";
CM_ SG_ 775 ACC_ACCEPBrequest  "ACC 主控则ACC发送，LAS 主控则LAS发送 ";
CM_ SG_ 775 ACC_ObjValid  "ACC 主控则ACC发送，LAS 主控则LAS发送 ";
CM_ SG_ 775 ACC_TimeGapSet  "ACC 主控则ACC发送，LAS 主控则LAS发送 ";
CM_ SG_ 775 ACC_DistanceLevel  "ACC 主控则ACC发送，LAS 主控则LAS发送 ";
CM_ SG_ 775 ACC_SetSpeed  "ACC 主控则ACC发送，LAS 主控则LAS发送 ";

CM_ BO_ 786  " ";
CM_ SG_ 786 ACC_SBUNCountDown  " ";
CM_ SG_ 786 ACC_RRLaneQuality  " ";
CM_ SG_ 786 ACC_LLaneQuality  " ";
CM_ SG_ 786 ACC_horizenLongPos  " ";
CM_ SG_ 786 ACC_ACCSysdeactiveReason  " ";
CM_ SG_ 786 ACC_AEBTargetFourWheelProb  "新增，取值范围同 ACC_AEBTargetProb ";
CM_ SG_ 786 ACC_AEBTargetProb  "借鉴C385 ";
CM_ SG_ 786 ADS_SpdLimitedStatus  " ";
CM_ SG_ 786 ADS_AutoHeadlightshift_Req  " ";
CM_ SG_ 786 ADS_UDLCTurnLightReq  " ";
CM_ SG_ 786 ACC_Selflearning_status  "ACC 主控则ACC发送，LAS 主控则LAS发送 ";
CM_ SG_ 786 ACC_Selflearning_angle  "ACC 主控则ACC发送，LAS 主控则LAS发送 ";
CM_ SG_ 786 ADS_NDAAudioWarEnableStatus  "ACC 主控则ACC发送，LAS 主控则LAS发送 ";
CM_ SG_ 786 ADS_ADSVoiceRequest  "ACC 主控则ACC发送，LAS 主控则LAS发送 ";
CM_ SG_ 786 ADS_EOMWarnning  " ";
CM_ SG_ 786 ADS_CRCCheck_3D7  " ";
CM_ SG_ 786 ADS_RollingCounter_3D7  " ";
CM_ SG_ 786 ACC_DriverWindowControl  "ACC 主控则ACC发送，LAS 主控则LAS发送 ";
CM_ SG_ 786 ACC_AEBTargetDirection  "ACC 主控则ACC发送，LAS 主控则LAS发送 ";
CM_ SG_ 786 ACC_AEBTargetDetection  "ACC 主控则ACC发送，LAS 主控则LAS发送 ";
CM_ SG_ 786 ACC_AEBTargetType  "ACC 主控则ACC发送，LAS 主控则LAS发送 ";
CM_ SG_ 786 ACC_CRCCheck_3E4  "ACC 主控则ACC发送，LAS 主控则LAS发送 ";
CM_ SG_ 786 ACC_RollingCounter_3E4  "ACC 主控则ACC发送，LAS 主控则LAS发送 ";

CM_ BO_ 832  "源端B_TMS_340或
HybridA_TMS_398,6 ";

CM_ BO_ 839  " ";
CM_ SG_ 839 TPMS_RRPressureWarning  "1、无效值是为转DBC
2、ACC 主控则ACC接收，LAS 主控则LAS接收 ";
CM_ SG_ 839 TPMS_LRPressureWarning  "1、无效值是为转DBC
2、ACC 主控则ACC接收，LAS 主控则LAS接收 ";
CM_ SG_ 839 TPMS_LFPressureWarning  "1、无效值是为转DBC
2、ACC 主控则ACC接收，LAS 主控则LAS接收 ";
CM_ SG_ 839 TPMS_RFPressureWarning  "1、无效值是为转DBC
2、ACC 主控则ACC接收，LAS 主控则LAS接收 ";
CM_ SG_ 839 TPMS_LRTyrePressure  "ACC 主控则ACC接收，LAS 主控则LAS接收 ";
CM_ SG_ 839 TPMS_RRTyrePressure  "ACC 主控则ACC接收，LAS 主控则LAS接收 ";
CM_ SG_ 839 TPMS_RFTyrePressure  "ACC 主控则ACC接收，LAS 主控则LAS接收 ";
CM_ SG_ 839 TPMS_LFTyrePressure  "ACC 主控则ACC接收，LAS 主控则LAS接收 ";

CM_ BO_ 869  " ";
CM_ SG_ 869 IMS_JawOffsetValue  " ";
CM_ SG_ 869 IMS_BrowOffsetValue  " ";
CM_ SG_ 869 IMS_HeadDetectSts_Yaw  " ";
CM_ SG_ 869 IMS_HeadDetectSts_Roll  " ";
CM_ SG_ 869 IMS_HeadDetectSts_Pitch  " ";
CM_ SG_ 869 IMS_IMSStatus  " ";
CM_ SG_ 869 IMS_EyeGazeStatus  " ";
CM_ SG_ 869 IMS_EyeDetectSatus  "10以下认为闭眼 ";
CM_ SG_ 869 IMS_DrowsinessStatus  " ";
CM_ SG_ 869 IMS_DriverHeadDetect  " ";
CM_ SG_ 869 IMS_DistractionStatus  " ";

CM_ BO_ 870  "源端B_TMS_366或
HybridA_TMS_398,3
（C857之前项目源端BCAN，C857之后项目源端HybridA） ";

CM_ BO_ 903  " ";

CM_ BO_ 912  " ";
CM_ SG_ 912 BCM_PMSLevel  "无效值是为转DBC ";

CM_ BO_ 918  " ";

CM_ BO_ 1287  " ";
CM_ SG_ 1287 HU_CSLWarnOffsetTp  " ";
CM_ SG_ 1287 HU_CSLEnable  " ";
CM_ SG_ 1287 HU_CSLmode  " ";
CM_ SG_ 1287 HU_VC_CruiseSetSpeed  "ACC 主控则ACC接收，LAS 主控则LAS接收 ";
CM_ SG_ 1287 HU_VC_CruiseSetDistance  "ACC 主控则ACC接收，LAS 主控则LAS接收 ";
CM_ SG_ 1287 HU_VC_CruiseControl  "ACC 主控则ACC接收，LAS 主控则LAS接收 ";
CM_ SG_ 1287 HU_FCWSetting  "ACC 主控则ACC接收，LAS 主控则LAS接收 ";
CM_ SG_ 1287 HU_AutoBrakeEnable  "ACC 主控则ACC接收，LAS 主控则LAS接收 ";
CM_ SG_ 1287 HU_IACCEnable  "513(周期)和514(事件)，当前多数项目使用514(事件)报文。 ";
CM_ SG_ 1287 HU_HMAEnable  "513(周期)和514(事件)，当前多数项目使用514(事件)报文。 ";
CM_ SG_ 1287 HU_TSRSwitch  "513(周期)和514(事件)，当前多数项目使用514(事件)报文。 ";
CM_ SG_ 1287 HU_LASWarningModeSelection  "513(周期)和514(事件)，当前多数项目使用514(事件)报文。 ";
CM_ SG_ 1287 HU_LASModeSelection  "513(周期)和514(事件)，当前多数项目使用514(事件)报文。 ";
CM_ SG_ 1287 HU_OverspeedWarningOffset  "513(周期)和514(事件)，当前多数项目使用514(事件)报文。 ";
CM_ SG_ 1287 HU_OverspeedWarningEnable  "513(周期)和514(事件)，当前多数项目使用514(事件)报文。 ";
CM_ SG_ 1287 HU_OverspeedSoundWarEnable  "513(周期)和514(事件)，当前多数项目使用514(事件)报文。 ";
CM_ SG_ 1287 HU_NDAAudioWarEnable  "ACC 主控则ACC接收，LAS 主控则LAS接收 ";

CM_ BO_ 1302  " ";

CM_ BO_ 1328  " ";
CM_ SG_ 1328 IP_TotalOdometer  "GW报文转发 ";

CM_ BO_ 391  "源端CHS_EPBi/IBCU_17A,0 ";
CM_ SG_ 391 ESP_VehicleSpeed  "TCU接收为DCT专用
ACM接收为AT/DCT专用 ";
CM_ SG_ 391 ESP_VehicleSpeedValid  "TCU接收为DCT专用 ";
CM_ SG_ 391 ESP_RollingCounter_187  "AT/DCT ";
CM_ SG_ 391 ESP_ESPActiveStatus  "TCU接收为DCT专用 ";
CM_ SG_ 391 ESP_EngTorqIncFrontActive  "ACC 主控则ACC接收，LAS 主控则LAS接收 ";
CM_ SG_ 391 ESP_EngTorqDecActive  "ACC 主控则ACC接收，LAS 主控则LAS接收 ";
CM_ SG_ 391 ESP_CRCCheck_187  "AT/DCT ";

CM_ BO_ 407  "源端CHS_IBCU/EPBi_17A,1 ";
CM_ SG_ 407 ESP_CRCCheck_197  " ";

CM_ BO_ 404  "源端HybridA_EMS/PDCU_17C,1 ";
CM_ SG_ 404 EMS_EngSts  "APA配置接收方无BDC ";
CM_ SG_ 404 EMS_EngFuCutOff  "ACC 主控则ACC接收，LAS 主控则LAS接收 ";

CM_ BO_ 381  " ";
CM_ SG_ 381 PCU_PwrIndcdRealTqRearWhl  "ACC 主控则ACC接收，LAS 主控则LAS接收 ";
CM_ SG_ 381 PCU_PwrIndcdDrvrReqTqWhlRear  "ACC 主控则ACC接收，LAS 主控则LAS接收 ";
CM_ SG_ 381 PCU_PwrTrainSts  "ACC 主控则ACC接收，LAS 主控则LAS接收 ";
CM_ SG_ 381 PCU_BrkPedlSts  "ACC 主控则ACC接收，LAS 主控则LAS接收 ";
CM_ SG_ 381 PCU_AccPedlVld  "ACC 主控则ACC接收，LAS 主控则LAS接收 ";
CM_ SG_ 381 PCU_AccPedl  "RMU法规要求
ACC 主控则ACC接收，LAS 主控则LAS接收 ";
CM_ SG_ 381 PCU_QECACC  "ACC 主控则ACC接收，LAS 主控则LAS接收 ";
CM_ SG_ 381 PCU_PwrIndcdRealTqWhlFailr  "ACC 主控则ACC接收，LAS 主控则LAS接收 ";
CM_ SG_ 381 PCU_PwrIndcdRealTqFrontWhl  "ACC 主控则ACC接收，LAS 主控则LAS接收 ";
CM_ SG_ 381 PCU_PwrIndcdDrvrReqTqWhlFront  "ACC 主控则ACC接收，LAS 主控则LAS接收 ";
CM_ SG_ 381 PCU_ECGPOvrd  "ACC 主控则ACC接收，LAS 主控则LAS接收 ";
CM_ SG_ 381 PCU_AccReqPossible  "ACC 主控则ACC接收，LAS 主控则LAS接收 ";
CM_ SG_ 381 PCU_TarGearReqValid  "ACC 主控则ACC接收，LAS 主控则LAS接收 ";
CM_ SG_ 381 PCU_TarGearReq  "ACC 主控则ACC接收，LAS 主控则LAS接收 ";
CM_ SG_ 381 PCU_RealAccPedlVld  "ACC 主控则ACC接收，LAS 主控则LAS接收 ";
CM_ SG_ 381 PCU_RealAccPedl  "APA配置接收方无BDC ";

CM_ BO_ 382  " ";
CM_ SG_ 382 EPS_Handwheel_Relang_Valid  " ";
CM_ SG_ 382 EPS_Handwheel_Relang  " ";
CM_ SG_ 382 EPS_Pinionang  " ";
CM_ SG_ 382 EPS_LatCtrlActive  "平台为10ms，CD569特例为8ms ";
CM_ SG_ 382 EPS_LatCtrlAvailabilityStatus  "平台为10ms，CD569特例为8ms ";
CM_ SG_ 382 EPS_CRCCheck_17E  "平台为10ms，CD569特例为8ms ";
CM_ SG_ 382 EPS_RollingCounter_17E  "1.rolling counter
2.平台为10ms，CD569特例为8ms ";
CM_ SG_ 382 EPS_MeasuredTorsionBarTorqValid  "平台为10ms，CD569特例为8ms ";
CM_ SG_ 382 EPS_MeasuredTorsionBarTorque  "平台为10ms，CD569特例为8ms ";

CM_ BO_ 442  " ";
CM_ SG_ 442 ADS_Authernticator_1BA  " ";
CM_ SG_ 442 ADS_ResetFlag_1BA  " ";
CM_ SG_ 442 ADS_MesssageCounter_1BA  " ";
CM_ SG_ 442 ACC_LKAinhaitWarning  " ";
CM_ SG_ 442 ACC_CRCCheck_1BA_0  "ACC 主控则ACC发送，LAS 主控则LAS发送 ";
CM_ SG_ 442 ACC_RollingCounter_1BA_0  "ACC 主控则ACC发送，LAS 主控则LAS发送 ";
CM_ SG_ 442 ACC_LatAngReqActive  "ACC 主控则ACC发送，LAS 主控则LAS发送 ";
CM_ SG_ 442 ACC_LatAngReq  "ACC 主控则ACC发送，LAS 主控则LAS发送 ";
CM_ SG_ 442 ACC_MotorTorqueMinLimitRequest  "ACC 主控则ACC发送，LAS 主控则LAS发送 ";
CM_ SG_ 442 ACC_MotorTorqueMaxLimitRequest  "ACC 主控则ACC发送，LAS 主控则LAS发送 ";

CM_ BO_ 523  " ";
CM_ SG_ 523 ESP_AEBSpeedDropActive  " ";
CM_ SG_ 523 ESP_VehicleStandstillVld  " ";
CM_ SG_ 523 IBCU_precheckStatus  "APA配置接收方无BDC ";
CM_ SG_ 523 Wheel_Speed_RR_Pulse  "All4wheelpulsesignalsaresentbyABSwithoutfiltering.Theriseedgeandfalledgearebothcountedinit,thewheelpulsemustbesequentialintheway0,1,2…254,0,1… ";
CM_ SG_ 523 Wheel_Speed_RR_Direction  "APA配置接收方无BDC ";
CM_ SG_ 523 Wheel_Speed_RR_Data  "APA配置接收方无BDC ";
CM_ SG_ 523 Wheel_Speed_RL_Pulse  "All4wheelpulsesignalsaresentbyABSwithoutfiltering.Theriseedgeandfalledgearebothcountedinit,thewheelpulsemustbesequentialintheway0,1,2…254,0,2… ";
CM_ SG_ 523 Wheel_Speed_RL_Direction  "APA配置接收方无BDC ";
CM_ SG_ 523 Wheel_Speed_RL_Data  "APA配置接收方无BDC ";
CM_ SG_ 523 Wheel_Speed_FR_Pulse  "All4wheelpulsesignalsaresentbyABSwithoutfiltering.Theriseedgeandfalledgearebothcountedinit,thewheelpulsemustbesequentialintheway0,1,2…254,0,3… ";
CM_ SG_ 523 Wheel_Speed_FR_Direction  "APA配置接收方无BDC ";
CM_ SG_ 523 Wheel_Speed_FR_Data  "APA配置接收方无BDC ";
CM_ SG_ 523 Wheel_Speed_FL_Pulse  "All4wheelpulsesignalsaresentbyABSwithoutfiltering.Theriseedgeandfalledgearebothcountedinit,thewheelpulsemustbesequentialintheway0,1,2…254,0,4… ";
CM_ SG_ 523 Wheel_Speed_FL_Direction  "APA配置接收方无BDC ";
CM_ SG_ 523 Wheel_Speed_FL_Data  "APA配置接收方无BDC ";
CM_ SG_ 523 ESP_VehicleStandstill  "APA配置接收方无BDC ";
CM_ SG_ 523 ESP_RollingCounter_277  "rollingcounter ";
CM_ SG_ 523 ESP_RollingCounter_258  "258 ";
CM_ SG_ 523 ESP_RollingCounter_208  "rollingcounter ";
CM_ SG_ 523 ESP_RollingCounter_206  "rollingcounter ";
CM_ SG_ 523 ESP_QDCACC  "ACC 主控则ACC接收，LAS 主控则LAS接收 ";
CM_ SG_ 523 ESP_PrefillAvailable  "ACC 主控则ACC接收，LAS 主控则LAS接收 ";
CM_ SG_ 523 ESP_PrefillActive  "ACC 主控则ACC接收，LAS 主控则LAS接收 ";
CM_ SG_ 523 ESP_MasCylBrakePressureValid  "258 ";
CM_ SG_ 523 ESP_MasCylBrakePressure  "indicatedthepressureofbrakemastercylinder,butnotthepressureofbrake ";
CM_ SG_ 523 ESP_CRCCheck_277  " ";
CM_ SG_ 523 ESP_CRCCheck_258  "258 ";
CM_ SG_ 523 ESP_CRCCheck_208  " ";
CM_ SG_ 523 ESP_CRCCheck_206  " ";
CM_ SG_ 523 ESP_CDD_Available  "ACC 主控则ACC接收，LAS 主控则LAS接收 ";
CM_ SG_ 523 ESP_CDD_Active  "ACC 主控则ACC接收，LAS 主控则LAS接收 ";
CM_ SG_ 523 ESP_BrakeForce  "APA配置接收方无BDC ";
CM_ SG_ 523 ESP_AWBavailable  "ACC 主控则ACC接收，LAS 主控则LAS接收 ";
CM_ SG_ 523 ESP_AWBactive  "ACC 主控则ACC接收，LAS 主控则LAS接收 ";
CM_ SG_ 523 ESP_AutoHoldAvailable  "258 ";
CM_ SG_ 523 ESP_AutoHoldActive  "258 ";
CM_ SG_ 523 ESP_AEBdecActive  "ACC 主控则ACC接收，LAS 主控则LAS接收 ";
CM_ SG_ 523 ESP_AEBAvailable  "ACC 主控则ACC接收，LAS 主控则LAS接收 ";
CM_ SG_ 523 ESP_ABAavailable  "ACC 主控则ACC接收，LAS 主控则LAS接收 ";
CM_ SG_ 523 ESP_ABAactive  "ACC 主控则ACC接收，LAS 主控则LAS接收 ";

CM_ BO_ 591  " ";
CM_ SG_ 591 EPS_LDW_ShakeLevStatus  " ";

CM_ BO_ 651  " ";

CM_ BO_ 721  " ";

CM_ BO_ 734  " ";
CM_ SG_ 734 IP_DISFail  "GW报文转发 ";
CM_ SG_ 734 IP_QDashACCFail  "ACC 主控则ACC接收，LAS 主控则LAS接收 ";

CM_ BO_ 794  " ";
CM_ SG_ 794 AD_AEBSysFltSts  " ";
CM_ SG_ 794 AD_FCWSysFltSts  " ";
CM_ SG_ 794 ACC_AEBTargetLatRelSpeed  "借鉴C385 ";
CM_ SG_ 794 ACC_ELKAlert  "ACC 主控则ACC发送，LAS 主控则LAS发送 ";
CM_ SG_ 794 ACC_CRCCheck_367  "ACC 主控则ACC发送，LAS 主控则LAS发送 ";
CM_ SG_ 794 ACC_RollingCounter_367  "ACC 主控则ACC发送，LAS 主控则LAS发送 ";
CM_ SG_ 794 ACC_LatPathHeadingAngle  "ACC 主控则ACC发送，LAS 主控则LAS发送 ";
CM_ SG_ 794 ACC_LatPathDY  "ACC 主控则ACC发送，LAS 主控则LAS发送 ";
CM_ SG_ 794 ACC_ELKEnableStatus  "ACC 主控则ACC发送，LAS 主控则LAS发送 ";
CM_ SG_ 794 ACC_ELKInterventionMode  "ACC 主控则ACC发送，LAS 主控则LAS发送 ";
CM_ SG_ 794 ACC_ELKMode  "ACC 主控则ACC发送，LAS 主控则LAS发送 ";
CM_ SG_ 794 ACC_CRCCheck_30D  "ACC 主控则ACC发送，LAS 主控则LAS发送 ";
CM_ SG_ 794 ACC_RollingCounter_30D  "ACC 主控则ACC发送，LAS 主控则LAS发送 ";
CM_ SG_ 794 ACC_RRLaneDetection  "ACC 主控则ACC发送，LAS 主控则LAS发送 ";
CM_ SG_ 794 ACC_LLLaneDetection  "ACC 主控则ACC发送，LAS 主控则LAS发送 ";
CM_ SG_ 794 ACC_HighBeamControl  "ACC 主控则ACC发送，LAS 主控则LAS发送 ";
CM_ SG_ 794 ACC_TargetBasedLateralControl  "ACC 主控则ACC发送，LAS 主控则LAS发送 ";
CM_ SG_ 794 ACC_IACCHWATextInfoForDriver  "ACC 主控则ACC发送，LAS 主控则LAS发送 ";
CM_ SG_ 794 ACC_EmergencyLightingRequest  "ACC 主控则ACC发送，LAS 主控则LAS发送 ";
CM_ SG_ 794 ACC_DriverHandsOffStatus  "ACC 主控则ACC发送，LAS 主控则LAS发送 ";
CM_ SG_ 794 ACC_IACCHWAMode  "ACC 主控则ACC发送，LAS 主控则LAS发送 ";
CM_ SG_ 794 ACC_CRCCheck_30A  "ACC 主控则ACC发送，LAS 主控则LAS发送 ";
CM_ SG_ 794 ACC_RollingCounter_30A  "ACC 主控则ACC发送，LAS 主控则LAS发送 ";
CM_ SG_ 794 ACC_LaneChangeStatus  "800W摄像头使用 ";
CM_ SG_ 794 ACC_RoadCurvatureFar  "1、向左为正，向右为负
2、ACC 主控则ACC发送，LAS 主控则LAS发送 ";
CM_ SG_ 794 ACC_RoadCurvatureNear  "1、向左为正，向右为负
2、ACC 主控则ACC发送，LAS 主控则LAS发送 ";
CM_ SG_ 794 ACC_RoadCurvature  "ACC 主控则ACC发送，LAS 主控则LAS发送 ";
CM_ SG_ 794 ACC_IACCHWAEnable  "ACC 主控则ACC发送，LAS 主控则LAS发送 ";
CM_ SG_ 794 ACC_RLaneMarkerType  "ACC 主控则ACC发送，LAS 主控则LAS发送，其余由APA或AVM发送 ";
CM_ SG_ 794 ACC_LLaneMarkerType  "ACC 主控则ACC发送，LAS 主控则LAS发送，其余由APA或AVM发送 ";
CM_ SG_ 794 ACC_HostLaneRightStatus  "ACC 主控则ACC发送，LAS 主控则LAS发送，其余由APA或AVM发送 ";
CM_ SG_ 794 ACC_HostLaneLeftStatus  "ACC 主控则ACC发送，LAS 主控则LAS发送，其余由APA或AVM发送 ";
CM_ SG_ 794 ACC_LASWarningModeSelectionSts  "ACC 主控则ACC发送，LAS 主控则LAS发送 ";
CM_ SG_ 794 ACC_LASModeSelectionStatus  "ACC 主控则ACC发送，LAS 主控则LAS发送 ";
CM_ SG_ 794 ACC_CRCCheck_36D  "ACC 主控则ACC发送，LAS 主控则LAS发送 ";
CM_ SG_ 794 ACC_RollingCounter_36D  "ACC 主控则ACC发送，LAS 主控则LAS发送 ";
CM_ SG_ 794 ACC_FRadarFailureStatus  " ";
CM_ SG_ 794 ACC_AEBTargetLatRange  "ACC 主控则ACC发送，LAS 主控则LAS发送 ";
CM_ SG_ 794 ACC_AEBTargetRelSpeed  "ACC 主控则ACC发送，LAS 主控则LAS发送 ";
CM_ SG_ 794 ACC_AEBTargetLngRange  "1、负数代表向后，正数代表向前，原点为前雷达波束发射面
2、ACC 主控则ACC发送，LAS 主控则LAS发送 ";
CM_ SG_ 794 ACC_Voiceinfo  "ACC 主控则ACC发送，LAS 主控则LAS发送 ";
CM_ SG_ 794 ACC_AEBTargetmode  "ACC 主控则ACC发送，LAS 主控则LAS发送 ";
CM_ SG_ 794 ACC_AEBTextInfo  "ACC 主控则ACC发送，LAS 主控则LAS发送 ";
CM_ SG_ 794 ACC_AEBStatus  "ACC 主控则ACC发送，LAS 主控则LAS发送 ";

CM_ BO_ 853  "源端P_EMS_355 ";
CM_ SG_ 853 EMS_CRCCheck_355  " ";

BA_DEF_ SG_  "GenSigStartValue" INT 0 0;
BA_DEF_ SG_  "GenSigInvalidValue" STRING  ;
BA_DEF_ SG_  "GenSigCycleTime" INT 0 0;
BA_DEF_ SG_  "GenSigSendType" ENUM  "Cyclic","OnWrite","OnWriteWithRepetition","OnChange","OnChangeWithRepetition","IfActive","IfActiveWithRepetition","NoSigSendType","NotUsed","NotUsed","NotUsed","NotUsed","NotUsed";
BA_DEF_  "Baudrate" INT 0 1000000;
BA_DEF_  "BusType" STRING ;
BA_DEF_  "NmType" STRING ;
BA_DEF_  "Manufacturer" STRING ;
BA_DEF_  "VersionYear" INT 2009 2210;
BA_DEF_  "VersionNumber" INT 0 65535;
BA_DEF_  "VersionMonth" INT 0 18;
BA_DEF_  "VersionDay" INT 0 49;
BA_DEF_ BU_  "NodeLayerModules" STRING ;
BA_DEF_ BU_  "ILUsed" ENUM  "No","Yes";
BA_DEF_  "GenNWMTalkNM" STRING ;
BA_DEF_  "GenNWMGotoMode_BusSleep" STRING ;
BA_DEF_  "GenNWMGotoMode_Awake" STRING ;
BA_DEF_  "GenNWMApCanWakeUp" STRING ;
BA_DEF_  "GenNWMApCanSleep" STRING ;
BA_DEF_  "GenNWMApCanOn" STRING ;
BA_DEF_  "GenNWMApCanOff" STRING ;
BA_DEF_  "GenNWMApCanNormal" STRING ;
BA_DEF_  "GenNWMApBusSleep" STRING ;
BA_DEF_ BO_  "GenMsgSendType" ENUM  "Cyclic","Event","NotUsed","NotUsed","NotUsed","Cyclic","NotUsed","IfActive","NoMsgSendType","NotUsed";
BA_DEF_ BO_  "GenMsgILSupport" ENUM  "No","Yes";
BA_DEF_ BO_  "GenMsgCycleTime" INT 0 65535;
BA_DEF_ BO_  "CANFD_BRS" ENUM  "0","1";
BA_DEF_ BO_  "VFrameFormat" ENUM  "StandardCAN","ExtendedCAN","reserved","reserved","reserved","reserved","reserved","reserved","reserved","reserved","reserved","reserved","reserved","reserved","StandardCAN_FD","ExtendedCAN_FD";
BA_DEF_DEF_  "GenSigStartValue" 0;
BA_DEF_DEF_  "GenSigInvalidValue" "/";
BA_DEF_DEF_  "GenSigCycleTime" 0;
BA_DEF_DEF_  "GenSigSendType" "Cyclic";
BA_DEF_DEF_  "Baudrate" 500000;
BA_DEF_DEF_  "BusType" "";
BA_DEF_DEF_  "NmType" "";
BA_DEF_DEF_  "Manufacturer" "CHANA";
BA_DEF_DEF_  "VersionYear" 2010;
BA_DEF_DEF_  "VersionNumber" 0;
BA_DEF_DEF_  "VersionMonth" 11;
BA_DEF_DEF_  "VersionDay" 0;
BA_DEF_DEF_  "NodeLayerModules" "CANoeILNLVector.dll";
BA_DEF_DEF_  "ILUsed" "Yes";
BA_DEF_DEF_  "GenNWMTalkNM" "TalkNM()";
BA_DEF_DEF_  "GenNWMGotoMode_BusSleep" "GotoMode_BusSleep()";
BA_DEF_DEF_  "GenNWMGotoMode_Awake" "GotoMode_Awake()";
BA_DEF_DEF_  "GenNWMApCanWakeUp" "apCanWakeUp()";
BA_DEF_DEF_  "GenNWMApCanSleep" "apCanSleep()";
BA_DEF_DEF_  "GenNWMApCanOn" "apCanOn()";
BA_DEF_DEF_  "GenNWMApCanOff" "apCanOff()";
BA_DEF_DEF_  "GenNWMApCanNormal" "apCanNormal()";
BA_DEF_DEF_  "GenNWMApBusSleep" "apBusSleep()";
BA_DEF_DEF_  "GenMsgSendType" "NoMsgSendType";
BA_DEF_DEF_  "GenMsgILSupport" "Yes";
BA_DEF_DEF_  "GenMsgCycleTime" 0;
BA_DEF_DEF_  "CANFD_BRS" "1";
BA_DEF_DEF_  "VFrameFormat" "StandardCAN";

BA_ "VersionYear" 2024;
BA_ "VersionNumber" 11;
BA_ "VersionDay" 19;
BA_ "Baudrate" 2000000;
BA_ "NmType" "OSEK";
BA_ "BusType" "CAN FD";
BA_ "GenMsgCycleTime" BO_ 898 100;
BA_ "GenMsgSendType" BO_ 898 0;
BA_ "VFrameFormat" BO_ 898 14;
BA_ "GenMsgCycleTime" BO_ 676 50;
BA_ "GenMsgSendType" BO_ 676 0;
BA_ "VFrameFormat" BO_ 676 14;
BA_ "GenMsgCycleTime" BO_ 1426 1000;
BA_ "GenMsgSendType" BO_ 1426 0;
BA_ "VFrameFormat" BO_ 1426 14;
BA_ "GenMsgCycleTime" BO_ 80 500;
BA_ "GenMsgSendType" BO_ 80 0;
BA_ "VFrameFormat" BO_ 80 14;
BA_ "GenMsgCycleTime" BO_ 368 10;
BA_ "GenMsgSendType" BO_ 368 0;
BA_ "VFrameFormat" BO_ 368 14;
BA_ "GenMsgCycleTime" BO_ 384 10;
BA_ "GenMsgSendType" BO_ 384 0;
BA_ "VFrameFormat" BO_ 384 14;
BA_ "GenMsgCycleTime" BO_ 580 20;
BA_ "GenMsgSendType" BO_ 580 0;
BA_ "VFrameFormat" BO_ 580 14;
BA_ "GenMsgCycleTime" BO_ 664 40;
BA_ "GenMsgSendType" BO_ 664 0;
BA_ "VFrameFormat" BO_ 664 14;
BA_ "GenMsgCycleTime" BO_ 775 100;
BA_ "GenMsgSendType" BO_ 775 0;
BA_ "VFrameFormat" BO_ 775 14;
BA_ "GenMsgCycleTime" BO_ 786 100;
BA_ "GenMsgSendType" BO_ 786 0;
BA_ "VFrameFormat" BO_ 786 14;
BA_ "GenMsgCycleTime" BO_ 832 100;
BA_ "GenMsgSendType" BO_ 832 0;
BA_ "VFrameFormat" BO_ 832 14;
BA_ "GenMsgCycleTime" BO_ 839 500;
BA_ "GenMsgSendType" BO_ 839 0;
BA_ "VFrameFormat" BO_ 839 14;
BA_ "GenMsgCycleTime" BO_ 869 100;
BA_ "GenMsgSendType" BO_ 869 0;
BA_ "VFrameFormat" BO_ 869 14;
BA_ "GenMsgCycleTime" BO_ 870 100;
BA_ "GenMsgSendType" BO_ 870 0;
BA_ "VFrameFormat" BO_ 870 14;
BA_ "GenMsgCycleTime" BO_ 903 100;
BA_ "GenMsgSendType" BO_ 903 0;
BA_ "VFrameFormat" BO_ 903 14;
BA_ "GenMsgCycleTime" BO_ 912 500;
BA_ "GenMsgSendType" BO_ 912 0;
BA_ "VFrameFormat" BO_ 912 14;
BA_ "GenMsgCycleTime" BO_ 918 100;
BA_ "GenMsgSendType" BO_ 918 0;
BA_ "VFrameFormat" BO_ 918 14;
BA_ "GenMsgSendType" BO_ 1287 1;
BA_ "VFrameFormat" BO_ 1287 14;
BA_ "GenMsgCycleTime" BO_ 1302 1000;
BA_ "GenMsgSendType" BO_ 1302 0;
BA_ "VFrameFormat" BO_ 1302 14;
BA_ "GenMsgCycleTime" BO_ 1328 500;
BA_ "GenMsgSendType" BO_ 1328 0;
BA_ "VFrameFormat" BO_ 1328 14;
BA_ "GenMsgCycleTime" BO_ 391 10;
BA_ "GenMsgSendType" BO_ 391 0;
BA_ "VFrameFormat" BO_ 391 14;
BA_ "GenMsgCycleTime" BO_ 407 10;
BA_ "GenMsgSendType" BO_ 407 0;
BA_ "VFrameFormat" BO_ 407 14;
BA_ "GenMsgCycleTime" BO_ 404 10;
BA_ "GenMsgSendType" BO_ 404 0;
BA_ "VFrameFormat" BO_ 404 14;
BA_ "GenMsgCycleTime" BO_ 381 10;
BA_ "GenMsgSendType" BO_ 381 0;
BA_ "VFrameFormat" BO_ 381 14;
BA_ "GenMsgCycleTime" BO_ 382 10;
BA_ "GenMsgSendType" BO_ 382 0;
BA_ "VFrameFormat" BO_ 382 14;
BA_ "GenMsgCycleTime" BO_ 442 10;
BA_ "GenMsgSendType" BO_ 442 0;
BA_ "VFrameFormat" BO_ 442 14;
BA_ "GenMsgCycleTime" BO_ 523 20;
BA_ "GenMsgSendType" BO_ 523 0;
BA_ "VFrameFormat" BO_ 523 14;
BA_ "GenMsgCycleTime" BO_ 591 20;
BA_ "GenMsgSendType" BO_ 591 0;
BA_ "VFrameFormat" BO_ 591 14;
BA_ "GenMsgCycleTime" BO_ 651 40;
BA_ "GenMsgSendType" BO_ 651 0;
BA_ "VFrameFormat" BO_ 651 14;
BA_ "GenMsgCycleTime" BO_ 721 40;
BA_ "GenMsgSendType" BO_ 721 0;
BA_ "VFrameFormat" BO_ 721 14;
BA_ "GenMsgCycleTime" BO_ 734 50;
BA_ "GenMsgSendType" BO_ 734 0;
BA_ "VFrameFormat" BO_ 734 14;
BA_ "GenMsgCycleTime" BO_ 794 100;
BA_ "GenMsgSendType" BO_ 794 0;
BA_ "VFrameFormat" BO_ 794 14;
BA_ "GenMsgCycleTime" BO_ 853 100;
BA_ "GenMsgSendType" BO_ 853 0;
BA_ "VFrameFormat" BO_ 853 14;
BA_ "GenSigCycleTime" SG_ 898 ACC_TarVehLngRange 100;
BA_ "GenSigStartValue" SG_ 898 ACC_TarVehLngRange 1500.000000;
BA_ "GenSigInvalidValue" SG_ 898 ACC_TarVehLngRange "4095";
BA_ "GenSigCycleTime" SG_ 898 ACC_Target5ZoneID 100;
BA_ "GenSigCycleTime" SG_ 898 ACC_Target5HeadingAngle 100;
BA_ "GenSigStartValue" SG_ 898 ACC_Target5HeadingAngle 314.000000;
BA_ "GenSigCycleTime" SG_ 898 ACC_Target5Direction 100;
BA_ "GenSigStartValue" SG_ 898 ACC_Target5Direction 5.000000;
BA_ "GenSigCycleTime" SG_ 898 ACC_Target5LatRange 100;
BA_ "GenSigStartValue" SG_ 898 ACC_Target5LatRange 500.000000;
BA_ "GenSigInvalidValue" SG_ 898 ACC_Target5LatRange "1023";
BA_ "GenSigCycleTime" SG_ 898 ACC_Target5LngRange 100;
BA_ "GenSigStartValue" SG_ 898 ACC_Target5LngRange 1500.000000;
BA_ "GenSigInvalidValue" SG_ 898 ACC_Target5LngRange "4095";
BA_ "GenSigCycleTime" SG_ 898 ACC_Target5Type 100;
BA_ "GenSigCycleTime" SG_ 898 ACC_Target5ID 100;
BA_ "GenSigCycleTime" SG_ 898 ACC_Target5Detection 100;
BA_ "GenSigCycleTime" SG_ 898 ACC_Target4ZoneID 100;
BA_ "GenSigCycleTime" SG_ 898 ACC_Target4HeadingAngle 100;
BA_ "GenSigStartValue" SG_ 898 ACC_Target4HeadingAngle 314.000000;
BA_ "GenSigCycleTime" SG_ 898 ACC_Target4Direction 100;
BA_ "GenSigStartValue" SG_ 898 ACC_Target4Direction 5.000000;
BA_ "GenSigCycleTime" SG_ 898 ACC_Target4LatRange 100;
BA_ "GenSigStartValue" SG_ 898 ACC_Target4LatRange 500.000000;
BA_ "GenSigInvalidValue" SG_ 898 ACC_Target4LatRange "1023";
BA_ "GenSigCycleTime" SG_ 898 ACC_Target4LngRange 100;
BA_ "GenSigStartValue" SG_ 898 ACC_Target4LngRange 1500.000000;
BA_ "GenSigInvalidValue" SG_ 898 ACC_Target4LngRange "4095";
BA_ "GenSigCycleTime" SG_ 898 ACC_Target4Type 100;
BA_ "GenSigCycleTime" SG_ 898 ACC_Target4ID 100;
BA_ "GenSigCycleTime" SG_ 898 ACC_Target4Detection 100;
BA_ "GenSigCycleTime" SG_ 898 ACC_Target3ZoneID 100;
BA_ "GenSigCycleTime" SG_ 898 ACC_Target3HeadingAngle 100;
BA_ "GenSigStartValue" SG_ 898 ACC_Target3HeadingAngle 314.000000;
BA_ "GenSigCycleTime" SG_ 898 ACC_Target3Direction 100;
BA_ "GenSigStartValue" SG_ 898 ACC_Target3Direction 5.000000;
BA_ "GenSigCycleTime" SG_ 898 ACC_Target3LatRange 100;
BA_ "GenSigStartValue" SG_ 898 ACC_Target3LatRange 500.000000;
BA_ "GenSigInvalidValue" SG_ 898 ACC_Target3LatRange "1023";
BA_ "GenSigCycleTime" SG_ 898 ACC_Target3LngRange 100;
BA_ "GenSigStartValue" SG_ 898 ACC_Target3LngRange 1500.000000;
BA_ "GenSigInvalidValue" SG_ 898 ACC_Target3LngRange "4095";
BA_ "GenSigCycleTime" SG_ 898 ACC_Target3Type 100;
BA_ "GenSigCycleTime" SG_ 898 ACC_Target3ID 100;
BA_ "GenSigCycleTime" SG_ 898 ACC_Target3Detection 100;
BA_ "GenSigCycleTime" SG_ 898 ACC_Target2ZoneID 100;
BA_ "GenSigCycleTime" SG_ 898 ACC_Target2HeadingAngle 100;
BA_ "GenSigStartValue" SG_ 898 ACC_Target2HeadingAngle 314.000000;
BA_ "GenSigCycleTime" SG_ 898 ACC_Target2Direction 100;
BA_ "GenSigStartValue" SG_ 898 ACC_Target2Direction 5.000000;
BA_ "GenSigCycleTime" SG_ 898 ACC_Target2LatRange 100;
BA_ "GenSigStartValue" SG_ 898 ACC_Target2LatRange 500.000000;
BA_ "GenSigInvalidValue" SG_ 898 ACC_Target2LatRange "1023";
BA_ "GenSigCycleTime" SG_ 898 ACC_Target2LngRange 100;
BA_ "GenSigStartValue" SG_ 898 ACC_Target2LngRange 1500.000000;
BA_ "GenSigInvalidValue" SG_ 898 ACC_Target2LngRange "4095";
BA_ "GenSigCycleTime" SG_ 898 ACC_Target2Type 100;
BA_ "GenSigCycleTime" SG_ 898 ACC_Target2ID 100;
BA_ "GenSigCycleTime" SG_ 898 ACC_Target2Detection 100;
BA_ "GenSigCycleTime" SG_ 898 ACC_Target1ZoneID 100;
BA_ "GenSigCycleTime" SG_ 898 ACC_Target1HeadingAngle 100;
BA_ "GenSigStartValue" SG_ 898 ACC_Target1HeadingAngle 314.000000;
BA_ "GenSigCycleTime" SG_ 898 ACC_Target1Direction 100;
BA_ "GenSigStartValue" SG_ 898 ACC_Target1Direction 5.000000;
BA_ "GenSigCycleTime" SG_ 898 ACC_Target1LatRange 100;
BA_ "GenSigStartValue" SG_ 898 ACC_Target1LatRange 500.000000;
BA_ "GenSigInvalidValue" SG_ 898 ACC_Target1LatRange "1023";
BA_ "GenSigCycleTime" SG_ 898 ACC_Target1LngRange 100;
BA_ "GenSigStartValue" SG_ 898 ACC_Target1LngRange 1500.000000;
BA_ "GenSigInvalidValue" SG_ 898 ACC_Target1LngRange "4095";
BA_ "GenSigCycleTime" SG_ 898 ACC_Target1Type 100;
BA_ "GenSigCycleTime" SG_ 898 ACC_Target1ID 100;
BA_ "GenSigCycleTime" SG_ 898 ACC_Target1Detection 100;
BA_ "GenSigCycleTime" SG_ 898 ACC_RollingCounter_3E6 100;
BA_ "GenSigCycleTime" SG_ 898 ACC_CRCCheck_3E6 100;
BA_ "GenSigCycleTime" SG_ 898 ACC_CRCCheck_35C 100;
BA_ "GenSigCycleTime" SG_ 898 ACC_RollingCounter_35C 100;
BA_ "GenSigCycleTime" SG_ 898 ACC_CRCCheck_35D 100;
BA_ "GenSigCycleTime" SG_ 898 ACC_RollingCounter_35D 100;
BA_ "GenSigCycleTime" SG_ 898 ACC_LaneEquationStatus 100;
BA_ "GenSigCycleTime" SG_ 898 ACC_LaneEquationC3 100;
BA_ "GenSigStartValue" SG_ 898 ACC_LaneEquationC3 2047.000000;
BA_ "GenSigCycleTime" SG_ 898 ACC_LaneEquationC2 100;
BA_ "GenSigStartValue" SG_ 898 ACC_LaneEquationC2 2047.000000;
BA_ "GenSigCycleTime" SG_ 898 ACC_LaneEquationC1 100;
BA_ "GenSigStartValue" SG_ 898 ACC_LaneEquationC1 2047.000000;
BA_ "GenSigCycleTime" SG_ 898 ACC_LaneQuality 100;

BA_ "GenSigCycleTime" SG_ 676 LCDAR_AEBVehilceHoldReq 50;
BA_ "GenSigCycleTime" SG_ 676 LCDAR_LDWShakeLevStatus 50;
BA_ "GenSigStartValue" SG_ 676 LCDAR_LDWShakeLevStatus 2.000000;
BA_ "GenSigCycleTime" SG_ 676 LCDAR_LDWVibrationWarningReq 50;
BA_ "GenSigCycleTime" SG_ 676 LCDA_BSDLCAMode 50;
BA_ "GenSigCycleTime" SG_ 676 LCDAR_RCTBStatus 50;
BA_ "GenSigInvalidValue" SG_ 676 LCDAR_RCTBStatus "3";
BA_ "GenSigCycleTime" SG_ 676 LCDAR_CRCCheck_2AF 50;
BA_ "GenSigCycleTime" SG_ 676 LCDAR_RollingCounter_2AF 50;
BA_ "GenSigCycleTime" SG_ 676 LCDAR_ELK_oAlert 50;
BA_ "GenSigCycleTime" SG_ 676 LCDAR_ELK_oStatus 50;
BA_ "GenSigInvalidValue" SG_ 676 LCDAR_ELK_oStatus "3";
BA_ "GenSigCycleTime" SG_ 676 LCDAR_Left_ELK_oAlert 50;
BA_ "GenSigCycleTime" SG_ 676 LCDAR_RCTBActive 50;
BA_ "GenSigInvalidValue" SG_ 676 LCDAR_RCTBActive "0";
BA_ "GenSigCycleTime" SG_ 676 LCDAR_RCTBTargetDecel 50;
BA_ "GenSigStartValue" SG_ 676 LCDAR_RCTBTargetDecel 32000.000000;
BA_ "GenSigCycleTime" SG_ 676 LCDAR_SystemStatus 50;
BA_ "GenSigStartValue" SG_ 676 LCDAR_SystemStatus 1.000000;
BA_ "GenSigInvalidValue" SG_ 676 LCDAR_SystemStatus "7";

BA_ "GenSigCycleTime" SG_ 1426 LAS_NotSleep_BYTE7BIT1 1000;
BA_ "GenSigCycleTime" SG_ 1426 LAS_NotSleep_BYTE7BIT0 1000;
BA_ "GenSigCycleTime" SG_ 1426 LAS_WakeUp_BYTE4BIT1 1000;
BA_ "GenSigCycleTime" SG_ 1426 LAS_WakeUp_BYTE4BIT0 1000;

BA_ "GenSigCycleTime" SG_ 80 SRS_WarningLampStatus 500;
BA_ "GenSigCycleTime" SG_ 80 SRS_DriverBuckleSwitchStatus 500;
BA_ "GenSigCycleTime" SG_ 80 SRS_RollingCounter_id050 500;
BA_ "GenSigCycleTime" SG_ 80 SRS_CrashOutputStatusCheckSum 500;
BA_ "GenSigCycleTime" SG_ 80 SRS_CrashOutputStatus 500;
BA_ "GenSigCycleTime" SG_ 80 SRS_CRCCheck_50 500;

BA_ "GenSigCycleTime" SG_ 368 EPS_ActualMotorTorq 10;
BA_ "GenSigStartValue" SG_ 368 EPS_ActualMotorTorq 2048.000000;
BA_ "GenSigInvalidValue" SG_ 368 EPS_ActualMotorTorq "4095";
BA_ "GenSigCycleTime" SG_ 368 EPS_CRCCheck_170 10;
BA_ "GenSigCycleTime" SG_ 368 EPS_RollingCounter_170 10;
BA_ "GenSigCycleTime" SG_ 368 EPS_ActualTorsionBarTorq 10;
BA_ "GenSigStartValue" SG_ 368 EPS_ActualTorsionBarTorq 1024.000000;
BA_ "GenSigInvalidValue" SG_ 368 EPS_ActualTorsionBarTorq "2047";
BA_ "GenSigCycleTime" SG_ 368 EPS_MinSafetyTorsionBarTorq 10;
BA_ "GenSigStartValue" SG_ 368 EPS_MinSafetyTorsionBarTorq 1024.000000;
BA_ "GenSigInvalidValue" SG_ 368 EPS_MinSafetyTorsionBarTorq "2047";
BA_ "GenSigCycleTime" SG_ 368 EPS_MaxSafetyTorsionBarTorq 10;
BA_ "GenSigStartValue" SG_ 368 EPS_MaxSafetyTorsionBarTorq 1024.000000;
BA_ "GenSigInvalidValue" SG_ 368 EPS_MaxSafetyTorsionBarTorq "2047";

BA_ "GenSigCycleTime" SG_ 384 SAS_CRCCheck 10;
BA_ "GenSigCycleTime" SG_ 384 SAS_RollingCounter 10;
BA_ "GenSigCycleTime" SG_ 384 SAS_SteeringAngleSpeed 10;
BA_ "GenSigInvalidValue" SG_ 384 SAS_SteeringAngleSpeed "255";
BA_ "GenSigCycleTime" SG_ 384 SAS_SteeringAngle 10;
BA_ "GenSigInvalidValue" SG_ 384 SAS_SteeringAngle "32767";
BA_ "GenSigCycleTime" SG_ 384 SAS_SASFailure 10;
BA_ "GenSigInvalidValue" SG_ 384 SAS_SASFailure "1";
BA_ "GenSigCycleTime" SG_ 384 SAS_Calibrated 10;
BA_ "GenSigCycleTime" SG_ 384 SAS_SteeringAngleValid 10;
BA_ "GenSigInvalidValue" SG_ 384 SAS_SteeringAngleValid "1";

BA_ "GenSigCycleTime" SG_ 580 ACC_AEBSpeedDropLevel 20;
BA_ "GenSigCycleTime" SG_ 580 ADS_ResetFlag_244 20;
BA_ "GenSigCycleTime" SG_ 580 ADS_Authernticator_244 20;
BA_ "GenSigCycleTime" SG_ 580 ADS_MesssageCounter_244 20;
BA_ "GenSigCycleTime" SG_ 580 ADS_EOMTOReq 20;
BA_ "GenSigCycleTime" SG_ 580 ACC_HandsOnReq 20;
BA_ "GenSigCycleTime" SG_ 580 ACC_LatTakeoverReq 20;
BA_ "GenSigCycleTime" SG_ 580 ACC_LngTakeOverReq 20;
BA_ "GenSigCycleTime" SG_ 580 ACC_LDWShakeLevStatus 20;
BA_ "GenSigStartValue" SG_ 580 ACC_LDWShakeLevStatus 2.000000;
BA_ "GenSigCycleTime" SG_ 580 ACC_TextInfoForDriver 20;
BA_ "GenSigCycleTime" SG_ 580 ADS__RollingCounter_244 20;
BA_ "GenSigCycleTime" SG_ 580 ADS_CRCCheck_244 20;
BA_ "GenSigCycleTime" SG_ 580 ACC_CRCCheck_25E 20;
BA_ "GenSigCycleTime" SG_ 580 ACC_RollingCounter_25E 20;
BA_ "GenSigCycleTime" SG_ 580 ACC_AEBCtrlType 20;
BA_ "GenSigCycleTime" SG_ 580 ACC_FuelCutOffPrevention 20;
BA_ "GenSigCycleTime" SG_ 580 ACC_AccTrqReq 20;
BA_ "GenSigCycleTime" SG_ 580 ACC_AccTrqReqActive 20;
BA_ "GenSigCycleTime" SG_ 580 ACC_AEBVehilceHoldReq 20;
BA_ "GenSigCycleTime" SG_ 580 ACC_FCWPreWarning 20;
BA_ "GenSigCycleTime" SG_ 580 ACC_FCWLatentWarning 20;
BA_ "GenSigCycleTime" SG_ 580 ACC_FCWActive 20;
BA_ "GenSigCycleTime" SG_ 580 ACC_PrefillActive 20;
BA_ "GenSigCycleTime" SG_ 580 ACC_AWBActive 20;
BA_ "GenSigCycleTime" SG_ 580 ACC_AWBlevel 20;
BA_ "GenSigCycleTime" SG_ 580 ACC_ABAActive 20;
BA_ "GenSigCycleTime" SG_ 580 ACC_ABAlevel 20;
BA_ "GenSigStartValue" SG_ 580 ACC_ABAlevel 3.000000;
BA_ "GenSigCycleTime" SG_ 580 ACC_AEBActive 20;
BA_ "GenSigCycleTime" SG_ 580 ACC_AEBTargetDeceleration 20;
BA_ "GenSigStartValue" SG_ 580 ACC_AEBTargetDeceleration 32000.000000;
BA_ "GenSigCycleTime" SG_ 580 ACC_EmergencyDataRrdReq 20;
BA_ "GenSigCycleTime" SG_ 580 ACC_CRCCheck_24E 20;
BA_ "GenSigCycleTime" SG_ 580 ACC_RollingCounter_24E 20;
BA_ "GenSigCycleTime" SG_ 580 ACC_Driveoff_Request 20;
BA_ "GenSigCycleTime" SG_ 580 ACC_ACCMode 20;
BA_ "GenSigInvalidValue" SG_ 580 ACC_ACCMode "7";
BA_ "GenSigCycleTime" SG_ 580 ACC_CDDActive 20;
BA_ "GenSigCycleTime" SG_ 580 ACC_EngineStartStopRequest 20;
BA_ "GenSigCycleTime" SG_ 580 ACC_DecToStop 20;
BA_ "GenSigCycleTime" SG_ 580 ACC_TCUCreepProhibition 20;
BA_ "GenSigCycleTime" SG_ 580 ACC_LKAStatus 20;
BA_ "GenSigInvalidValue" SG_ 580 ACC_LKAStatus "3";
BA_ "GenSigCycleTime" SG_ 580 ACC_LDWVibrationWarningReq 20;
BA_ "GenSigCycleTime" SG_ 580 ACC_LDWStatus 20;
BA_ "GenSigInvalidValue" SG_ 580 ACC_LDWStatus "3";
BA_ "GenSigCycleTime" SG_ 580 ACC_ACCTargetAcceleration 20;
BA_ "GenSigStartValue" SG_ 580 ACC_ACCTargetAcceleration 100.000000;

BA_ "GenSigCycleTime" SG_ 664 BCM_DriverDoorLockStatus 40;
BA_ "GenSigStartValue" SG_ 664 BCM_DriverDoorLockStatus 3.000000;
BA_ "GenSigCycleTime" SG_ 664 BCM_LeftRearDoorStatus 40;

BA_ "GenSigCycleTime" SG_ 775 ACC_CSLmodeStatus 100;
BA_ "GenSigCycleTime" SG_ 775 ACC_CSLEnableStatus 100;
BA_ "GenSigCycleTime" SG_ 775 ACC_AEBTargetSelected 100;
BA_ "GenSigInvalidValue" SG_ 775 ACC_AEBTargetSelected "7";
BA_ "GenSigCycleTime" SG_ 775 ACC_AEBFeatureConfig 100;
BA_ "GenSigInvalidValue" SG_ 775 ACC_AEBFeatureConfig "15";
BA_ "GenSigCycleTime" SG_ 775 ACC_LatDeviationDis 100;
BA_ "GenSigInvalidValue" SG_ 775 ACC_LatDeviationDis "0";
BA_ "GenSigCycleTime" SG_ 775 ACC_LatDeviationReason 100;
BA_ "GenSigInvalidValue" SG_ 775 ACC_LatDeviationReason "0";
BA_ "GenSigCycleTime" SG_ 775 ACC_IACCSuspendReason 100;
BA_ "GenSigInvalidValue" SG_ 775 ACC_IACCSuspendReason "0";
BA_ "GenSigCycleTime" SG_ 775 ACC_IACCProhibitionTime 100;
BA_ "GenSigCycleTime" SG_ 775 ACC_Line_RR_Id 100;
BA_ "GenSigCycleTime" SG_ 775 ACC_Line_R_Id 100;
BA_ "GenSigCycleTime" SG_ 775 ACC_Line_LL_Id 100;
BA_ "GenSigCycleTime" SG_ 775 ACC_Line_L_Id 100;
BA_ "GenSigCycleTime" SG_ 775 ACC_RRLanecolor 100;
BA_ "GenSigCycleTime" SG_ 775 ACC_RLanecolor 100;
BA_ "GenSigCycleTime" SG_ 775 ACC_LLLanecolor 100;
BA_ "GenSigCycleTime" SG_ 775 ACC_LLanecolor 100;
BA_ "GenSigCycleTime" SG_ 775 ACC_RLaneDistanceFus 100;
BA_ "GenSigStartValue" SG_ 775 ACC_RLaneDistanceFus 100.000000;
BA_ "GenSigCycleTime" SG_ 775 ACC_LLaneDistanceFus 100;
BA_ "GenSigStartValue" SG_ 775 ACC_LLaneDistanceFus 20.000000;
BA_ "GenSigCycleTime" SG_ 775 ACC_RRLaneDis 100;
BA_ "GenSigStartValue" SG_ 775 ACC_RRLaneDis 240.000000;
BA_ "GenSigCycleTime" SG_ 775 ACC_LLLaneDis 100;
BA_ "GenSigCycleTime" SG_ 775 ACC_Target7ZoneID 100;
BA_ "GenSigCycleTime" SG_ 775 ACC_Target7HeadingAngle 100;
BA_ "GenSigStartValue" SG_ 775 ACC_Target7HeadingAngle 314.000000;
BA_ "GenSigCycleTime" SG_ 775 ACC_Target7Direction 100;
BA_ "GenSigStartValue" SG_ 775 ACC_Target7Direction 5.000000;
BA_ "GenSigCycleTime" SG_ 775 ACC_Target7LatRange 100;
BA_ "GenSigStartValue" SG_ 775 ACC_Target7LatRange 500.000000;
BA_ "GenSigInvalidValue" SG_ 775 ACC_Target7LatRange "1023";
BA_ "GenSigCycleTime" SG_ 775 ACC_Target7LngRange 100;
BA_ "GenSigStartValue" SG_ 775 ACC_Target7LngRange 1500.000000;
BA_ "GenSigInvalidValue" SG_ 775 ACC_Target7LngRange "4095";
BA_ "GenSigCycleTime" SG_ 775 ACC_Target7Type 100;
BA_ "GenSigCycleTime" SG_ 775 ACC_Target7ID 100;
BA_ "GenSigCycleTime" SG_ 775 ACC_Target7Detection 100;
BA_ "GenSigCycleTime" SG_ 775 ACC_Target6ZoneID 100;
BA_ "GenSigCycleTime" SG_ 775 ACC_Target6HeadingAngle 100;
BA_ "GenSigStartValue" SG_ 775 ACC_Target6HeadingAngle 314.000000;
BA_ "GenSigCycleTime" SG_ 775 ACC_Target6Direction 100;
BA_ "GenSigStartValue" SG_ 775 ACC_Target6Direction 5.000000;
BA_ "GenSigCycleTime" SG_ 775 ACC_Target6LatRange 100;
BA_ "GenSigStartValue" SG_ 775 ACC_Target6LatRange 500.000000;
BA_ "GenSigInvalidValue" SG_ 775 ACC_Target6LatRange "1023";
BA_ "GenSigCycleTime" SG_ 775 ACC_Target6LngRange 100;
BA_ "GenSigStartValue" SG_ 775 ACC_Target6LngRange 1500.000000;
BA_ "GenSigInvalidValue" SG_ 775 ACC_Target6LngRange "4095";
BA_ "GenSigCycleTime" SG_ 775 ACC_Target6Type 100;
BA_ "GenSigCycleTime" SG_ 775 ACC_Target6ID 100;
BA_ "GenSigCycleTime" SG_ 775 ACC_Target6Detection 100;
BA_ "GenSigCycleTime" SG_ 775 ACC_AEBEnable 100;
BA_ "GenSigStartValue" SG_ 775 ACC_AEBEnable 1.000000;
BA_ "GenSigCycleTime" SG_ 775 ACC_VehicleStartRemindSts 100;
BA_ "GenSigCycleTime" SG_ 775 ACC_CRCCheck_35F 100;
BA_ "GenSigCycleTime" SG_ 775 ACC_RollingCounter_35F 100;
BA_ "GenSigCycleTime" SG_ 775 ACC_CSLAEnableStatus 100;
BA_ "GenSigInvalidValue" SG_ 775 ACC_CSLAEnableStatus "3";
BA_ "GenSigCycleTime" SG_ 775 ACC_CSLSetReq 100;
BA_ "GenSigCycleTime" SG_ 775 ACC_CRCCheck_344 100;
BA_ "GenSigCycleTime" SG_ 775 ACC_RollingCounter_344 100;
BA_ "GenSigCycleTime" SG_ 775 ACC_CRCCheck_322 100;
BA_ "GenSigCycleTime" SG_ 775 ACC_RollingCounter_322 100;
BA_ "GenSigCycleTime" SG_ 775 ACC_ACCTargetRelSpd 100;
BA_ "GenSigStartValue" SG_ 775 ACC_ACCTargetRelSpd 250.000000;
BA_ "GenSigCycleTime" SG_ 775 ACC_FRadarCalibrationStatus 100;
BA_ "GenSigInvalidValue" SG_ 775 ACC_FRadarCalibrationStatus "3";
BA_ "GenSigCycleTime" SG_ 775 ACC_CRCCheck_35E 100;
BA_ "GenSigCycleTime" SG_ 775 ACC_RollingCounter_35E 100;
BA_ "GenSigCycleTime" SG_ 775 ACC_FCWSettingStatus 100;
BA_ "GenSigStartValue" SG_ 775 ACC_FCWSettingStatus 1.000000;
BA_ "GenSigCycleTime" SG_ 775 ACC_ACCEPBrequest 100;
BA_ "GenSigCycleTime" SG_ 775 ACC_ObjValid 100;
BA_ "GenSigCycleTime" SG_ 775 ACC_TimeGapSet 100;
BA_ "GenSigCycleTime" SG_ 775 ACC_DistanceLevel 100;
BA_ "GenSigCycleTime" SG_ 775 ACC_SetSpeed 100;

BA_ "GenSigCycleTime" SG_ 786 ACC_SBUNCountDown 100;
BA_ "GenSigCycleTime" SG_ 786 ACC_RRLaneQuality 100;
BA_ "GenSigCycleTime" SG_ 786 ACC_LLaneQuality 100;
BA_ "GenSigCycleTime" SG_ 786 ACC_horizenLongPos 100;
BA_ "GenSigInvalidValue" SG_ 786 ACC_horizenLongPos "255";
BA_ "GenSigCycleTime" SG_ 786 ACC_ACCSysdeactiveReason 100;
BA_ "GenSigCycleTime" SG_ 786 ACC_AEBTargetFourWheelProb 100;
BA_ "GenSigCycleTime" SG_ 786 ACC_AEBTargetProb 100;
BA_ "GenSigCycleTime" SG_ 786 ACC_AEBTargetStatus 100;
BA_ "GenSigCycleTime" SG_ 786 ACC_AEBTargetAy 100;
BA_ "GenSigCycleTime" SG_ 786 ACC_AEBTargetAx 100;
BA_ "GenSigCycleTime" SG_ 786 ACC_CRCCheck_312 100;
BA_ "GenSigCycleTime" SG_ 786 ADS_SpdLimitedStatus 100;
BA_ "GenSigCycleTime" SG_ 786 ADS_AutoHeadlightshift_Req 100;
BA_ "GenSigCycleTime" SG_ 786 ADS_UDLCTurnLightReq 100;
BA_ "GenSigInvalidValue" SG_ 786 ADS_UDLCTurnLightReq "7";
BA_ "GenSigCycleTime" SG_ 786 ACC_Selflearning_status 100;
BA_ "GenSigCycleTime" SG_ 786 ACC_Selflearning_angle 100;
BA_ "GenSigCycleTime" SG_ 786 ADS_NDAAudioWarEnableStatus 100;
BA_ "GenSigCycleTime" SG_ 786 ADS_ADSVoiceRequest 100;
BA_ "GenSigCycleTime" SG_ 786 ADS_EOMWarnning 100;
BA_ "GenSigCycleTime" SG_ 786 ADS_CRCCheck_3D7 100;
BA_ "GenSigCycleTime" SG_ 786 ADS_RollingCounter_3D7 100;
BA_ "GenSigCycleTime" SG_ 786 ACC_DriverWindowControl 100;
BA_ "GenSigCycleTime" SG_ 786 ACC_AEBTargetDirection 100;
BA_ "GenSigStartValue" SG_ 786 ACC_AEBTargetDirection 5.000000;
BA_ "GenSigCycleTime" SG_ 786 ACC_AEBTargetDetection 100;
BA_ "GenSigCycleTime" SG_ 786 ACC_AEBTargetType 100;
BA_ "GenSigStartValue" SG_ 786 ACC_AEBTargetType 15.000000;
BA_ "GenSigCycleTime" SG_ 786 ACC_CRCCheck_3E4 100;
BA_ "GenSigCycleTime" SG_ 786 ACC_RollingCounter_3E4 100;

BA_ "GenSigCycleTime" SG_ 832 AC_FrBlowType 100;
BA_ "GenSigInvalidValue" SG_ 832 AC_FrBlowType "7";

BA_ "GenSigCycleTime" SG_ 839 TPMS_RRPressureWarning 500;
BA_ "GenSigCycleTime" SG_ 839 TPMS_LRPressureWarning 500;
BA_ "GenSigCycleTime" SG_ 839 TPMS_LFPressureWarning 500;
BA_ "GenSigInvalidValue" SG_ 839 TPMS_LFPressureWarning "0";
BA_ "GenSigCycleTime" SG_ 839 TPMS_RFPressureWarning 500;
BA_ "GenSigCycleTime" SG_ 839 TPMS_LRTyrePressure 500;
BA_ "GenSigInvalidValue" SG_ 839 TPMS_LRTyrePressure "255";
BA_ "GenSigCycleTime" SG_ 839 TPMS_RRTyrePressure 500;
BA_ "GenSigInvalidValue" SG_ 839 TPMS_RRTyrePressure "255";
BA_ "GenSigCycleTime" SG_ 839 TPMS_RFTyrePressure 500;
BA_ "GenSigInvalidValue" SG_ 839 TPMS_RFTyrePressure "255";
BA_ "GenSigCycleTime" SG_ 839 TPMS_LFTyrePressure 500;
BA_ "GenSigInvalidValue" SG_ 839 TPMS_LFTyrePressure "255";

BA_ "GenSigCycleTime" SG_ 869 IMS_DriverREyeDetect 100;
BA_ "GenSigInvalidValue" SG_ 869 IMS_DriverREyeDetect "0";
BA_ "GenSigCycleTime" SG_ 869 IMS_DriverLEyeDetect 100;
BA_ "GenSigInvalidValue" SG_ 869 IMS_DriverLEyeDetect "0";
BA_ "GenSigCycleTime" SG_ 869 IMS_JawOffsetValue 100;
BA_ "GenSigCycleTime" SG_ 869 IMS_BrowOffsetValue 100;
BA_ "GenSigCycleTime" SG_ 869 IMS_DriverEyeClosestatus 100;
BA_ "GenSigStartValue" SG_ 869 IMS_DriverEyeClosestatus 7.000000;
BA_ "GenSigInvalidValue" SG_ 869 IMS_DriverEyeClosestatus "7";
BA_ "GenSigCycleTime" SG_ 869 IMS_RollingCounter_3A7 100;
BA_ "GenSigCycleTime" SG_ 869 IMS_CRCCheck_3A7 100;
BA_ "GenSigCycleTime" SG_ 869 IMS_RollingCounter_360 100;
BA_ "GenSigCycleTime" SG_ 869 IMS_CRCCheck_360 100;
BA_ "GenSigCycleTime" SG_ 869 IMS_HeadDetectSts_Yaw 100;
BA_ "GenSigStartValue" SG_ 869 IMS_HeadDetectSts_Yaw 255.000000;
BA_ "GenSigInvalidValue" SG_ 869 IMS_HeadDetectSts_Yaw "255";
BA_ "GenSigCycleTime" SG_ 869 IMS_HeadDetectSts_Roll 100;
BA_ "GenSigStartValue" SG_ 869 IMS_HeadDetectSts_Roll 255.000000;
BA_ "GenSigInvalidValue" SG_ 869 IMS_HeadDetectSts_Roll "255";
BA_ "GenSigCycleTime" SG_ 869 IMS_HeadDetectSts_Pitch 100;
BA_ "GenSigStartValue" SG_ 869 IMS_HeadDetectSts_Pitch 255.000000;
BA_ "GenSigInvalidValue" SG_ 869 IMS_HeadDetectSts_Pitch "255";
BA_ "GenSigCycleTime" SG_ 869 IMS_RollingCounter_356 100;
BA_ "GenSigCycleTime" SG_ 869 IMS_CRCCheck_356 100;
BA_ "GenSigCycleTime" SG_ 869 IMS_IMSStatus 100;
BA_ "GenSigStartValue" SG_ 869 IMS_IMSStatus 1.000000;
BA_ "GenSigInvalidValue" SG_ 869 IMS_IMSStatus "7";
BA_ "GenSigCycleTime" SG_ 869 IMS_EyeGazeStatus 100;
BA_ "GenSigStartValue" SG_ 869 IMS_EyeGazeStatus 255.000000;
BA_ "GenSigInvalidValue" SG_ 869 IMS_EyeGazeStatus "255";
BA_ "GenSigCycleTime" SG_ 869 IMS_EyeDetectSatus 100;
BA_ "GenSigStartValue" SG_ 869 IMS_EyeDetectSatus 255.000000;
BA_ "GenSigInvalidValue" SG_ 869 IMS_EyeDetectSatus "255";
BA_ "GenSigCycleTime" SG_ 869 IMS_DrowsinessStatus 100;
BA_ "GenSigInvalidValue" SG_ 869 IMS_DrowsinessStatus "7";
BA_ "GenSigCycleTime" SG_ 869 IMS_DriverHeadDetect 100;
BA_ "GenSigInvalidValue" SG_ 869 IMS_DriverHeadDetect "0";
BA_ "GenSigCycleTime" SG_ 869 IMS_DistractionStatus 100;
BA_ "GenSigInvalidValue" SG_ 869 IMS_DistractionStatus "3";

BA_ "GenSigCycleTime" SG_ 870 AC_EnvironmentalTemp 100;
BA_ "GenSigStartValue" SG_ 870 AC_EnvironmentalTemp 255.000000;
BA_ "GenSigInvalidValue" SG_ 870 AC_EnvironmentalTemp "255";
BA_ "GenSigCycleTime" SG_ 870 AC_EnvironmentalTempVD 100;
BA_ "GenSigInvalidValue" SG_ 870 AC_EnvironmentalTempVD "1";

BA_ "GenSigCycleTime" SG_ 903 BCM_CRCCheck_387 100;
BA_ "GenSigCycleTime" SG_ 903 BCM_RollingCounter_387 100;
BA_ "GenSigCycleTime" SG_ 903 BCM_RainfallLevel 100;
BA_ "GenSigStartValue" SG_ 903 BCM_RainfallLevel 14.000000;
BA_ "GenSigInvalidValue" SG_ 903 BCM_RainfallLevel "15";
BA_ "GenSigCycleTime" SG_ 903 BCM_FrontWiperStatus 100;
BA_ "GenSigInvalidValue" SG_ 903 BCM_FrontWiperStatus "3";
BA_ "GenSigCycleTime" SG_ 903 BCM_RLS_Light_switch_reason 100;
BA_ "GenSigStartValue" SG_ 903 BCM_RLS_Light_switch_reason 255.000000;
BA_ "GenSigInvalidValue" SG_ 903 BCM_RLS_Light_switch_reason "255";

BA_ "GenSigCycleTime" SG_ 912 BCM_SOH_LifePercent 500;
BA_ "GenSigStartValue" SG_ 912 BCM_SOH_LifePercent 255.000000;
BA_ "GenSigInvalidValue" SG_ 912 BCM_SOH_LifePercent "255";
BA_ "GenSigCycleTime" SG_ 912 BCM_PMSLevel 500;

BA_ "GenSigCycleTime" SG_ 918 BCM_SunroofStatus 100;

BA_ "GenSigSendType" SG_ 1287 HU_LDWSenStyle 1;
BA_ "GenSigSendType" SG_ 1287 HU_OverspeedWarningOffRatioset_EU 1;
BA_ "GenSigStartValue" SG_ 1287 HU_OverspeedWarningOffRatioset_EU 47.000000;
BA_ "GenSigSendType" SG_ 1287 HU_TSRSpeedLimitChangeSoundEn 1;
BA_ "GenSigInvalidValue" SG_ 1287 HU_TSRSpeedLimitChangeSoundEn "0";
BA_ "GenSigSendType" SG_ 1287 HU_TSREnable 1;
BA_ "GenSigInvalidValue" SG_ 1287 HU_TSREnable "0";
BA_ "GenSigSendType" SG_ 1287 HU_CSLWarnOffsetTp 1;
BA_ "GenSigSendType" SG_ 1287 HU_CSLEnable 1;
BA_ "GenSigSendType" SG_ 1287 HU_CSLmode 1;
BA_ "GenSigSendType" SG_ 1287 HU_VC_CruiseSetSpeed 1;
BA_ "GenSigSendType" SG_ 1287 HU_VC_CruiseSetDistance 1;
BA_ "GenSigSendType" SG_ 1287 HU_VC_CruiseControl 1;
BA_ "GenSigSendType" SG_ 1287 HU_FCWSetting 1;
BA_ "GenSigSendType" SG_ 1287 HU_AutoBrakeEnable 1;
BA_ "GenSigSendType" SG_ 1287 HU_IACCEnable 1;
BA_ "GenSigSendType" SG_ 1287 HU_HMAEnable 1;
BA_ "GenSigSendType" SG_ 1287 HU_TSRSwitch 1;
BA_ "GenSigSendType" SG_ 1287 HU_LASWarningModeSelection 1;
BA_ "GenSigSendType" SG_ 1287 HU_LASModeSelection 1;
BA_ "GenSigSendType" SG_ 1287 HU_OverspeedWarningOffset 1;
BA_ "GenSigSendType" SG_ 1287 HU_OverspeedWarningEnable 1;
BA_ "GenSigSendType" SG_ 1287 HU_OverspeedSoundWarEnable 1;
BA_ "GenSigSendType" SG_ 1287 HU_NDAAudioWarEnable 1;

BA_ "GenSigCycleTime" SG_ 1302 HU_LocalTimeSystem 1000;
BA_ "GenSigCycleTime" SG_ 1302 HU_LocalTimeSecond 1000;
BA_ "GenSigInvalidValue" SG_ 1302 HU_LocalTimeSecond "0";
BA_ "GenSigCycleTime" SG_ 1302 HU_LocalTimeMinute 1000;
BA_ "GenSigInvalidValue" SG_ 1302 HU_LocalTimeMinute "0";
BA_ "GenSigCycleTime" SG_ 1302 HU_LocalTimeHour 1000;
BA_ "GenSigInvalidValue" SG_ 1302 HU_LocalTimeHour "0";
BA_ "GenSigCycleTime" SG_ 1302 HU_LocalTimeDate 1000;
BA_ "GenSigStartValue" SG_ 1302 HU_LocalTimeDate 1.000000;
BA_ "GenSigInvalidValue" SG_ 1302 HU_LocalTimeDate "1";
BA_ "GenSigCycleTime" SG_ 1302 HU_LocalTimeYear 1000;
BA_ "GenSigInvalidValue" SG_ 1302 HU_LocalTimeYear "0";
BA_ "GenSigCycleTime" SG_ 1302 HU_LocalTimeMonth 1000;
BA_ "GenSigStartValue" SG_ 1302 HU_LocalTimeMonth 1.000000;
BA_ "GenSigInvalidValue" SG_ 1302 HU_LocalTimeMonth "1";
BA_ "GenSigCycleTime" SG_ 1302 HU_LocalTimeValid 1000;
BA_ "GenSigInvalidValue" SG_ 1302 HU_LocalTimeValid "1";
BA_ "GenSigCycleTime" SG_ 1302 HU_CurrentLocationLatitude 1000;
BA_ "GenSigInvalidValue" SG_ 1302 HU_CurrentLocationLatitude "268435455";
BA_ "GenSigCycleTime" SG_ 1302 HU_CurrentLocationLongitude 1000;
BA_ "GenSigInvalidValue" SG_ 1302 HU_CurrentLocationLongitude "536870911";
BA_ "GenSigCycleTime" SG_ 1302 HU_CurrentLocationValid 1000;
BA_ "GenSigInvalidValue" SG_ 1302 HU_CurrentLocationValid "1";

BA_ "GenSigCycleTime" SG_ 1328 IP_TotalOdometer 500;
BA_ "GenSigInvalidValue" SG_ 1328 IP_TotalOdometer "16777215";

BA_ "GenSigCycleTime" SG_ 391 ESP_VehicleSpeed 10;
BA_ "GenSigInvalidValue" SG_ 391 ESP_VehicleSpeed "8191";
BA_ "GenSigCycleTime" SG_ 391 ESP_VehicleSpeedValid 10;
BA_ "GenSigInvalidValue" SG_ 391 ESP_VehicleSpeedValid "1";
BA_ "GenSigCycleTime" SG_ 391 ESP_TCSFailStatus 10;
BA_ "GenSigCycleTime" SG_ 391 ESP_RollingCounter_187 10;
BA_ "GenSigCycleTime" SG_ 391 ESP_ESPFunctionStatus 10;
BA_ "GenSigStartValue" SG_ 391 ESP_ESPFunctionStatus 1.000000;
BA_ "GenSigCycleTime" SG_ 391 ESP_ESPActiveStatus 10;
BA_ "GenSigCycleTime" SG_ 391 ESP_EngTorqIncFrontActive 10;
BA_ "GenSigCycleTime" SG_ 391 ESP_EngTorqDecActive 10;
BA_ "GenSigCycleTime" SG_ 391 ESP_CRCCheck_187 10;
BA_ "GenSigCycleTime" SG_ 391 ESP_ABSFailStatus 10;
BA_ "GenSigCycleTime" SG_ 391 ESP_ABSActiveStatus 10;

BA_ "GenSigCycleTime" SG_ 407 ESP_RollingCounter_197 10;
BA_ "GenSigCycleTime" SG_ 407 ESP_CRCCheck_197 10;

BA_ "GenSigCycleTime" SG_ 404 EMS_RollingCounter_194 10;
BA_ "GenSigCycleTime" SG_ 404 EMS_EngSts 10;
BA_ "GenSigCycleTime" SG_ 404 EMS_EngSpdErr 10;
BA_ "GenSigCycleTime" SG_ 404 EMS_EngSpd 10;
BA_ "GenSigInvalidValue" SG_ 404 EMS_EngSpd "65535";
BA_ "GenSigCycleTime" SG_ 404 EMS_EngFuCutOff 10;
BA_ "GenSigCycleTime" SG_ 404 EMS_CRCCheck_194 10;

BA_ "GenSigCycleTime" SG_ 381 PCU_PwrIndcdRealTqRearWhl 10;
BA_ "GenSigInvalidValue" SG_ 381 PCU_PwrIndcdRealTqRearWhl "32767";
BA_ "GenSigCycleTime" SG_ 381 PCU_PwrIndcdDrvrReqTqWhlRear 10;
BA_ "GenSigInvalidValue" SG_ 381 PCU_PwrIndcdDrvrReqTqWhlRear "32767";
BA_ "GenSigCycleTime" SG_ 381 PCU_PwrTrainSts 10;
BA_ "GenSigInvalidValue" SG_ 381 PCU_PwrTrainSts "3";
BA_ "GenSigCycleTime" SG_ 381 PCU_BrkPedlSts 10;
BA_ "GenSigCycleTime" SG_ 381 PCU_AccPedlVld 10;
BA_ "GenSigCycleTime" SG_ 381 PCU_AccPedl 10;
BA_ "GenSigCycleTime" SG_ 381 PCU_QECACC 10;
BA_ "GenSigCycleTime" SG_ 381 PCU_PwrIndcdRealTqWhlFailr 10;
BA_ "GenSigInvalidValue" SG_ 381 PCU_PwrIndcdRealTqWhlFailr "1";
BA_ "GenSigCycleTime" SG_ 381 PCU_PwrIndcdRealTqFrontWhl 10;
BA_ "GenSigInvalidValue" SG_ 381 PCU_PwrIndcdRealTqFrontWhl "32767";
BA_ "GenSigCycleTime" SG_ 381 PCU_PwrIndcdDrvrReqTqWhlFront 10;
BA_ "GenSigInvalidValue" SG_ 381 PCU_PwrIndcdDrvrReqTqWhlFront "32767";
BA_ "GenSigCycleTime" SG_ 381 PCU_ECGPOvrd 10;
BA_ "GenSigCycleTime" SG_ 381 PCU_AccReqPossible 10;
BA_ "GenSigCycleTime" SG_ 381 PCU_TarGearReqValid 10;
BA_ "GenSigCycleTime" SG_ 381 PCU_TarGearReq 10;
BA_ "GenSigInvalidValue" SG_ 381 PCU_TarGearReq "15";
BA_ "GenSigCycleTime" SG_ 381 PCU_RealAccPedlVld 10;
BA_ "GenSigCycleTime" SG_ 381 PCU_RealAccPedl 10;

BA_ "GenSigCycleTime" SG_ 382 EPS_Handwheel_Relang_Valid 10;
BA_ "GenSigInvalidValue" SG_ 382 EPS_Handwheel_Relang_Valid "1";
BA_ "GenSigCycleTime" SG_ 382 EPS_Handwheel_Relang 10;
BA_ "GenSigStartValue" SG_ 382 EPS_Handwheel_Relang 10800.000000;
BA_ "GenSigInvalidValue" SG_ 382 EPS_Handwheel_Relang "32767";
BA_ "GenSigCycleTime" SG_ 382 EPS_Pinionang 10;
BA_ "GenSigStartValue" SG_ 382 EPS_Pinionang 7200.000000;
BA_ "GenSigInvalidValue" SG_ 382 EPS_Pinionang "16383";
BA_ "GenSigCycleTime" SG_ 382 EPS_LatCtrlActive 10;
BA_ "GenSigInvalidValue" SG_ 382 EPS_LatCtrlActive "0";
BA_ "GenSigCycleTime" SG_ 382 EPS_LatCtrlAvailabilityStatus 10;
BA_ "GenSigInvalidValue" SG_ 382 EPS_LatCtrlAvailabilityStatus "2";
BA_ "GenSigCycleTime" SG_ 382 EPS_CRCCheck_17E 10;
BA_ "GenSigCycleTime" SG_ 382 EPS_RollingCounter_17E 10;
BA_ "GenSigCycleTime" SG_ 382 EPS_MeasuredTorsionBarTorqValid 10;
BA_ "GenSigInvalidValue" SG_ 382 EPS_MeasuredTorsionBarTorqValid "1";
BA_ "GenSigCycleTime" SG_ 382 EPS_MeasuredTorsionBarTorque 10;
BA_ "GenSigStartValue" SG_ 382 EPS_MeasuredTorsionBarTorque 2048.000000;
BA_ "GenSigInvalidValue" SG_ 382 EPS_MeasuredTorsionBarTorque "4095";

BA_ "GenSigCycleTime" SG_ 442 ADS_Authernticator_1BA 10;
BA_ "GenSigCycleTime" SG_ 442 ADS_ResetFlag_1BA 10;
BA_ "GenSigCycleTime" SG_ 442 ADS_MesssageCounter_1BA 10;
BA_ "GenSigCycleTime" SG_ 442 ACC_LKAinhaitWarning 10;
BA_ "GenSigCycleTime" SG_ 442 ACC_CRCCheck_1BA_0 10;
BA_ "GenSigCycleTime" SG_ 442 ACC_RollingCounter_1BA_0 10;
BA_ "GenSigCycleTime" SG_ 442 ACC_LatAngReqActive 10;
BA_ "GenSigCycleTime" SG_ 442 ACC_LatAngReq 10;
BA_ "GenSigStartValue" SG_ 442 ACC_LatAngReq 7200.000000;
BA_ "GenSigInvalidValue" SG_ 442 ACC_LatAngReq "14401";
BA_ "GenSigCycleTime" SG_ 442 ACC_MotorTorqueMinLimitRequest 10;
BA_ "GenSigStartValue" SG_ 442 ACC_MotorTorqueMinLimitRequest 1024.000000;
BA_ "GenSigCycleTime" SG_ 442 ACC_MotorTorqueMaxLimitRequest 10;
BA_ "GenSigStartValue" SG_ 442 ACC_MotorTorqueMaxLimitRequest 1024.000000;

BA_ "GenSigCycleTime" SG_ 523 ESP_AEBSpeedDropActive 20;
BA_ "GenSigCycleTime" SG_ 523 ESP_VehicleStandstillVld 20;
BA_ "GenSigInvalidValue" SG_ 523 ESP_VehicleStandstillVld "NA";
BA_ "GenSigCycleTime" SG_ 523 IBCU_BrkPedlStsGbVld 20;
BA_ "GenSigInvalidValue" SG_ 523 IBCU_BrkPedlStsGbVld "2";
BA_ "GenSigCycleTime" SG_ 523 IBCU_BrkPedoplStsGb 20;
BA_ "GenSigInvalidValue" SG_ 523 IBCU_BrkPedoplStsGb "255";
BA_ "GenSigCycleTime" SG_ 523 ESP_Vehicle_Speed_Reference 20;
BA_ "GenSigInvalidValue" SG_ 523 ESP_Vehicle_Speed_Reference "8191";
BA_ "GenSigCycleTime" SG_ 523 IBCU_precheckStatus 20;
BA_ "GenSigCycleTime" SG_ 523 IBCU_BrakeDiscHighTempWarning 20;
BA_ "GenSigCycleTime" SG_ 523 ESP_RollingCounter_20B 20;
BA_ "GenSigCycleTime" SG_ 523 ESP_CRCCheck_20B 20;
BA_ "GenSigCycleTime" SG_ 523 Wheel_Speed_RR_Valid_Data 20;
BA_ "GenSigInvalidValue" SG_ 523 Wheel_Speed_RR_Valid_Data "1";
BA_ "GenSigCycleTime" SG_ 523 Wheel_Speed_RR_Pulse 20;
BA_ "GenSigInvalidValue" SG_ 523 Wheel_Speed_RR_Pulse "255";
BA_ "GenSigCycleTime" SG_ 523 Wheel_Speed_RR_Direction 20;
BA_ "GenSigCycleTime" SG_ 523 Wheel_Speed_RR_Data 20;
BA_ "GenSigInvalidValue" SG_ 523 Wheel_Speed_RR_Data "8191";
BA_ "GenSigCycleTime" SG_ 523 Wheel_Speed_RL_Valid_Data 20;
BA_ "GenSigInvalidValue" SG_ 523 Wheel_Speed_RL_Valid_Data "1";
BA_ "GenSigCycleTime" SG_ 523 Wheel_Speed_RL_Pulse 20;
BA_ "GenSigInvalidValue" SG_ 523 Wheel_Speed_RL_Pulse "255";
BA_ "GenSigCycleTime" SG_ 523 Wheel_Speed_RL_Direction 20;
BA_ "GenSigInvalidValue" SG_ 523 Wheel_Speed_RL_Direction "3";
BA_ "GenSigCycleTime" SG_ 523 Wheel_Speed_RL_Data 20;
BA_ "GenSigInvalidValue" SG_ 523 Wheel_Speed_RL_Data "8191";
BA_ "GenSigCycleTime" SG_ 523 Wheel_Speed_FR_Valid_Data 20;
BA_ "GenSigInvalidValue" SG_ 523 Wheel_Speed_FR_Valid_Data "1";
BA_ "GenSigCycleTime" SG_ 523 Wheel_Speed_FR_Pulse 20;
BA_ "GenSigInvalidValue" SG_ 523 Wheel_Speed_FR_Pulse "255";
BA_ "GenSigCycleTime" SG_ 523 Wheel_Speed_FR_Direction 20;
BA_ "GenSigInvalidValue" SG_ 523 Wheel_Speed_FR_Direction "3";
BA_ "GenSigCycleTime" SG_ 523 Wheel_Speed_FR_Data 20;
BA_ "GenSigInvalidValue" SG_ 523 Wheel_Speed_FR_Data "8191";
BA_ "GenSigCycleTime" SG_ 523 Wheel_Speed_FL_Valid_Data 20;
BA_ "GenSigInvalidValue" SG_ 523 Wheel_Speed_FL_Valid_Data "1";
BA_ "GenSigCycleTime" SG_ 523 Wheel_Speed_FL_Pulse 20;
BA_ "GenSigInvalidValue" SG_ 523 Wheel_Speed_FL_Pulse "255";
BA_ "GenSigCycleTime" SG_ 523 Wheel_Speed_FL_Direction 20;
BA_ "GenSigInvalidValue" SG_ 523 Wheel_Speed_FL_Direction "3";
BA_ "GenSigCycleTime" SG_ 523 Wheel_Speed_FL_Data 20;
BA_ "GenSigInvalidValue" SG_ 523 Wheel_Speed_FL_Data "8191";
BA_ "GenSigCycleTime" SG_ 523 ESP_VehicleStandstill 20;
BA_ "GenSigCycleTime" SG_ 523 ESP_VDCActive 20;
BA_ "GenSigCycleTime" SG_ 523 ESP_TCSActive 20;
BA_ "GenSigCycleTime" SG_ 523 ESP_RollingCounter_277 20;
BA_ "GenSigCycleTime" SG_ 523 ESP_RollingCounter_258 20;
BA_ "GenSigCycleTime" SG_ 523 ESP_RollingCounter_208 20;
BA_ "GenSigCycleTime" SG_ 523 ESP_RollingCounter_206 20;
BA_ "GenSigCycleTime" SG_ 523 ESP_QDCACC 20;
BA_ "GenSigCycleTime" SG_ 523 ESP_PrefillAvailable 20;
BA_ "GenSigCycleTime" SG_ 523 ESP_PrefillActive 20;
BA_ "GenSigCycleTime" SG_ 523 ESP_OnlyABSActive 20;
BA_ "GenSigCycleTime" SG_ 523 ESP_MasCylBrakePressureValid 20;
BA_ "GenSigCycleTime" SG_ 523 ESP_MasCylBrakePressure 20;
BA_ "GenSigInvalidValue" SG_ 523 ESP_MasCylBrakePressure "4095";
BA_ "GenSigCycleTime" SG_ 523 ESP_HDC_STATUS 20;
BA_ "GenSigInvalidValue" SG_ 523 ESP_HDC_STATUS "3";
BA_ "GenSigCycleTime" SG_ 523 ESP_CRCCheck_277 20;
BA_ "GenSigCycleTime" SG_ 523 ESP_CRCCheck_258 20;
BA_ "GenSigCycleTime" SG_ 523 ESP_CRCCheck_208 20;
BA_ "GenSigCycleTime" SG_ 523 ESP_CRCCheck_206 20;
BA_ "GenSigCycleTime" SG_ 523 ESP_CDD_Available 20;
BA_ "GenSigCycleTime" SG_ 523 ESP_CDD_Active 20;
BA_ "GenSigCycleTime" SG_ 523 ESP_BrakeOverHeatBrakeDiscTemp 20;
BA_ "GenSigCycleTime" SG_ 523 ESP_BrakeForce 20;
BA_ "GenSigCycleTime" SG_ 523 ESP_AWBavailable 20;
BA_ "GenSigCycleTime" SG_ 523 ESP_AWBactive 20;
BA_ "GenSigCycleTime" SG_ 523 ESP_AutoHoldAvailable 20;
BA_ "GenSigCycleTime" SG_ 523 ESP_AutoHoldActive 20;
BA_ "GenSigCycleTime" SG_ 523 ESP_AEBdecActive 20;
BA_ "GenSigCycleTime" SG_ 523 ESP_AEBAvailable 20;
BA_ "GenSigCycleTime" SG_ 523 ESP_ABAavailable 20;
BA_ "GenSigCycleTime" SG_ 523 ESP_ABAactive 20;

BA_ "GenSigCycleTime" SG_ 591 EPS_LDW_ShakeLevStatus 20;
BA_ "GenSigCycleTime" SG_ 591 EPS_ConcussAvailabilityStatus 20;
BA_ "GenSigInvalidValue" SG_ 591 EPS_ConcussAvailabilityStatus "2";
BA_ "GenSigCycleTime" SG_ 591 EPS_TorqueAssistMode 20;
BA_ "GenSigStartValue" SG_ 591 EPS_TorqueAssistMode 3.000000;
BA_ "GenSigCycleTime" SG_ 591 EPS_IACC_abortreason 20;
BA_ "GenSigCycleTime" SG_ 591 EPS_CRCCheck_24F 20;
BA_ "GenSigCycleTime" SG_ 591 EPS_RollingCounter_24F 20;

BA_ "GenSigCycleTime" SG_ 651 BCM_CRCCheck_28B 40;
BA_ "GenSigCycleTime" SG_ 651 BCM_RollingCounter_28B 40;
BA_ "GenSigCycleTime" SG_ 651 BCM_TurnIndicatorLeft 40;
BA_ "GenSigInvalidValue" SG_ 651 BCM_TurnIndicatorLeft "3";
BA_ "GenSigCycleTime" SG_ 651 BCM_TurnIndicatorRight 40;
BA_ "GenSigInvalidValue" SG_ 651 BCM_TurnIndicatorRight "3";
BA_ "GenSigCycleTime" SG_ 651 BCM_emergencylightstatus 40;
BA_ "GenSigInvalidValue" SG_ 651 BCM_emergencylightstatus "3";
BA_ "GenSigCycleTime" SG_ 651 BCM_PowerStatusFeedback 40;
BA_ "GenSigCycleTime" SG_ 651 BCM_DriverDoorStatus 40;
BA_ "GenSigCycleTime" SG_ 651 BCM_LowBeamStatus 40;
BA_ "GenSigInvalidValue" SG_ 651 BCM_LowBeamStatus "3";
BA_ "GenSigCycleTime" SG_ 651 BCM_HighBeamStatus 40;
BA_ "GenSigInvalidValue" SG_ 651 BCM_HighBeamStatus "3";
BA_ "GenSigCycleTime" SG_ 651 BCM_TurnLightSwitchSts 40;
BA_ "GenSigInvalidValue" SG_ 651 BCM_TurnLightSwitchSts "3";

BA_ "GenSigCycleTime" SG_ 721 BCM_TrunkDoorStatus 40;
BA_ "GenSigCycleTime" SG_ 721 BCM_RightRearDoorStatus 40;
BA_ "GenSigCycleTime" SG_ 721 BCM_PassengerDoorStatus 40;

BA_ "GenSigCycleTime" SG_ 734 IP_CRCCheck_2DE 50;
BA_ "GenSigCycleTime" SG_ 734 IP_RollingCounter_2DE 50;
BA_ "GenSigCycleTime" SG_ 734 IP_DISFail 50;
BA_ "GenSigInvalidValue" SG_ 734 IP_DISFail "0";
BA_ "GenSigCycleTime" SG_ 734 IP_QDashACCFail 50;
BA_ "GenSigInvalidValue" SG_ 734 IP_QDashACCFail "0";

BA_ "GenSigCycleTime" SG_ 794 AD_AEBSysFltSts 100;
BA_ "GenSigInvalidValue" SG_ 794 AD_AEBSysFltSts "7";
BA_ "GenSigCycleTime" SG_ 794 AD_FCWSysFltSts 100;
BA_ "GenSigInvalidValue" SG_ 794 AD_FCWSysFltSts "7";
BA_ "GenSigCycleTime" SG_ 794 ACC_LDWSenStyle 100;
BA_ "GenSigCycleTime" SG_ 794 ACC_AEBTargetLatRelSpeed 100;
BA_ "GenSigCycleTime" SG_ 794 ACC_HandsoffWarningExitReason 100;
BA_ "GenSigInvalidValue" SG_ 794 ACC_HandsoffWarningExitReason "0";
BA_ "GenSigCycleTime" SG_ 794 ACC_LngTakeOverReqReason 100;
BA_ "GenSigInvalidValue" SG_ 794 ACC_LngTakeOverReqReason "0";
BA_ "GenSigCycleTime" SG_ 794 ACC_ELKAlert 100;
BA_ "GenSigCycleTime" SG_ 794 ACC_CRCCheck_367 100;
BA_ "GenSigCycleTime" SG_ 794 ACC_RollingCounter_367 100;
BA_ "GenSigCycleTime" SG_ 794 ACC_LatPathHeadingAngle 100;
BA_ "GenSigCycleTime" SG_ 794 ACC_LatPathDY 100;
BA_ "GenSigCycleTime" SG_ 794 ACC_ELKEnableStatus 100;
BA_ "GenSigCycleTime" SG_ 794 ACC_ELKInterventionMode 100;
BA_ "GenSigCycleTime" SG_ 794 ACC_ELKMode 100;
BA_ "GenSigInvalidValue" SG_ 794 ACC_ELKMode "3";
BA_ "GenSigCycleTime" SG_ 794 ACC_CRCCheck_30D 100;
BA_ "GenSigCycleTime" SG_ 794 ACC_RollingCounter_30D 100;
BA_ "GenSigCycleTime" SG_ 794 ACC_RRLaneDetection 100;
BA_ "GenSigCycleTime" SG_ 794 ACC_LLLaneDetection 100;
BA_ "GenSigCycleTime" SG_ 794 ACC_HighBeamControl 100;
BA_ "GenSigCycleTime" SG_ 794 ACC_TargetBasedLateralControl 100;
BA_ "GenSigCycleTime" SG_ 794 ACC_IACCHWATextInfoForDriver 100;
BA_ "GenSigCycleTime" SG_ 794 ACC_EmergencyLightingRequest 100;
BA_ "GenSigCycleTime" SG_ 794 ACC_DriverHandsOffStatus 100;
BA_ "GenSigInvalidValue" SG_ 794 ACC_DriverHandsOffStatus "3";
BA_ "GenSigCycleTime" SG_ 794 ACC_IACCHWAMode 100;
BA_ "GenSigInvalidValue" SG_ 794 ACC_IACCHWAMode "7";
BA_ "GenSigCycleTime" SG_ 794 ACC_CRCCheck_30A 100;
BA_ "GenSigCycleTime" SG_ 794 ACC_RollingCounter_30A 100;
BA_ "GenSigCycleTime" SG_ 794 ACC_LaneChangeStatus 100;
BA_ "GenSigCycleTime" SG_ 794 ACC_RoadCurvatureFar 100;
BA_ "GenSigStartValue" SG_ 794 ACC_RoadCurvatureFar 60.000000;
BA_ "GenSigCycleTime" SG_ 794 ACC_RoadCurvatureNear 100;
BA_ "GenSigStartValue" SG_ 794 ACC_RoadCurvatureNear 60.000000;
BA_ "GenSigCycleTime" SG_ 794 ACC_RoadCurvature 100;
BA_ "GenSigStartValue" SG_ 794 ACC_RoadCurvature 60.000000;
BA_ "GenSigCycleTime" SG_ 794 ACC_IACCHWAEnable 100;
BA_ "GenSigCycleTime" SG_ 794 ACC_RLaneMarkerType 100;
BA_ "GenSigStartValue" SG_ 794 ACC_RLaneMarkerType 7.000000;
BA_ "GenSigCycleTime" SG_ 794 ACC_LLaneMarkerType 100;
BA_ "GenSigStartValue" SG_ 794 ACC_LLaneMarkerType 7.000000;
BA_ "GenSigCycleTime" SG_ 794 ACC_HostLaneRightStatus 100;
BA_ "GenSigCycleTime" SG_ 794 ACC_HostLaneLeftStatus 100;
BA_ "GenSigCycleTime" SG_ 794 ACC_LASWarningModeSelectionSts 100;
BA_ "GenSigStartValue" SG_ 794 ACC_LASWarningModeSelectionSts 2.000000;
BA_ "GenSigCycleTime" SG_ 794 ACC_LASModeSelectionStatus 100;
BA_ "GenSigStartValue" SG_ 794 ACC_LASModeSelectionStatus 1.000000;
BA_ "GenSigCycleTime" SG_ 794 ACC_CRCCheck_36D 100;
BA_ "GenSigCycleTime" SG_ 794 ACC_RollingCounter_36D 100;
BA_ "GenSigCycleTime" SG_ 794 ACC_FRadarFailureStatus 100;
BA_ "GenSigInvalidValue" SG_ 794 ACC_FRadarFailureStatus "3";
BA_ "GenSigCycleTime" SG_ 794 ACC_AEBTargetLatRange 100;
BA_ "GenSigStartValue" SG_ 794 ACC_AEBTargetLatRange 500.000000;
BA_ "GenSigCycleTime" SG_ 794 ACC_AEBTargetRelSpeed 100;
BA_ "GenSigStartValue" SG_ 794 ACC_AEBTargetRelSpeed 250.000000;
BA_ "GenSigCycleTime" SG_ 794 ACC_AEBTargetLngRange 100;
BA_ "GenSigStartValue" SG_ 794 ACC_AEBTargetLngRange 500.000000;
BA_ "GenSigCycleTime" SG_ 794 ACC_Voiceinfo 100;
BA_ "GenSigCycleTime" SG_ 794 ACC_AEBTargetmode 100;
BA_ "GenSigCycleTime" SG_ 794 ACC_AEBTextInfo 100;
BA_ "GenSigCycleTime" SG_ 794 ACC_AEBStatus 100;
BA_ "GenSigInvalidValue" SG_ 794 ACC_AEBStatus "3";

BA_ "GenSigCycleTime" SG_ 853 EMS_CRCCheck_355 100;
BA_ "GenSigCycleTime" SG_ 853 EMS_RollingCounter_355 100;

VAL_ 898 ACC_TarVehLngRange 0 "0~300" 3001 "Reserved" 4095 "Invalid";
VAL_ 898 ACC_Target5ZoneID 0 "no zoneid" 1 "zoneid1-11
0xC=hostlane_zone
0xD=leftlane_zone
0xE=rightlane_zone
0xF=LLLane_zone
0x10=RRLane_zone
0x11=Ramp_zone" 18 "others" 19 "reserved";
VAL_ 898 ACC_Target5Direction 0 "Forward" 1 "OnComing" 2 "Left" 3 "Right" 4 "unknown" 5 "refer to headingangle" 6 "reserved";
VAL_ 898 ACC_Target5LatRange 0 "-50-50m" 1001 "reserved" 1023 "Invalid";
VAL_ 898 ACC_Target5LngRange 0 "-100~300" 4001 "reserved" 4095 "Invalid";
VAL_ 898 ACC_Target5Type 0 "no display" 1 "sedan" 2 "motorcycle" 3 "pedestrian" 4 "Bicycle" 5 "Bus" 6 "VAN" 7 "truck" 8 "Cone Consideration" 9 "Warning Column" 10 "Water Horse" 11 "Anti-Collision Bucket" 12 "others" 13 "animal" 14 "Non-road vehicle" 15 "CarWarningTriangle";
VAL_ 898 ACC_Target5ID 0 "";
VAL_ 898 ACC_Target5Detection 0 "not dectected" 1 "IP display" 2 "Front Target" 3 "IACC target" 4 "AEB target" 5 "dangerous target（ELK、UDLC、RCW, etc）" 6 "other target" 7 "reserved";
VAL_ 898 ACC_Target4ZoneID 0 "no zoneid" 1 "zoneid1-11
0xC=hostlane_zone
0xD=leftlane_zone
0xE=rightlane_zone
0xF=LLLane_zone
0x10=RRLane_zone
0x11=Ramp_zone" 18 "others" 19 "reserved";
VAL_ 898 ACC_Target4Direction 0 "Forward" 1 "OnComing" 2 "Left" 3 "Right" 4 "unknown" 5 "refer to headingangle" 6 "reserved";
VAL_ 898 ACC_Target4LatRange 0 "-50-50m" 1001 "reserved" 1023 "Invalid";
VAL_ 898 ACC_Target4LngRange 0 "-100~300" 4001 "reserved" 4095 "Invalid";
VAL_ 898 ACC_Target4Type 0 "no display" 1 "sedan" 2 "motorcycle" 3 "pedestrian" 4 "Bicycle" 5 "Bus" 6 "VAN" 7 "truck" 8 "Cone Consideration" 9 "Warning Column" 10 "Water Horse" 11 "Anti-Collision Bucket" 12 "others" 13 "animal" 14 "Non-road vehicle" 15 "CarWarningTriangle";
VAL_ 898 ACC_Target4ID 0 "";
VAL_ 898 ACC_Target4Detection 0 "not dectected" 1 "IP display" 2 "Front Target" 3 "IACC target" 4 "AEB target" 5 "dangerous target（ELK、UDLC、RCW, etc）" 6 "other target" 7 "reserved";
VAL_ 898 ACC_Target3ZoneID 0 "no zoneid" 1 "zoneid1-11
0xC=hostlane_zone
0xD=leftlane_zone
0xE=rightlane_zone
0xF=LLLane_zone
0x10=RRLane_zone
0x11=Ramp_zone" 18 "others" 19 "reserved";
VAL_ 898 ACC_Target3Direction 0 "Forward" 1 "OnComing" 2 "Left" 3 "Right" 4 "unknown" 5 "refer to headingangle" 6 "reserved";
VAL_ 898 ACC_Target3LatRange 0 "-50-50m" 1001 "reserved" 1023 "Invalid";
VAL_ 898 ACC_Target3LngRange 0 "-100~300" 4001 "reserved" 4095 "Invalid";
VAL_ 898 ACC_Target3Type 0 "no display" 1 "sedan" 2 "motorcycle" 3 "pedestrian" 4 "Bicycle" 5 "Bus" 6 "VAN" 7 "truck" 8 "Cone Consideration" 9 "Warning Column" 10 "Water Horse" 11 "Anti-Collision Bucket" 12 "others" 13 "animal" 14 "Non-road vehicle" 15 "CarWarningTriangle";
VAL_ 898 ACC_Target3ID 0 "";
VAL_ 898 ACC_Target3Detection 0 "not dectected" 1 "IP display" 2 "Front Target" 3 "IACC target" 4 "AEB target" 5 "dangerous target（ELK、UDLC、RCW, etc）" 6 "other target" 7 "reserved";
VAL_ 898 ACC_Target2ZoneID 0 "no zoneid" 1 "zoneid1-11
0xC=hostlane_zone
0xD=leftlane_zone
0xE=rightlane_zone
0xF=LLLane_zone
0x10=RRLane_zone
0x11=Ramp_zone" 18 "others" 19 "reserved";
VAL_ 898 ACC_Target2Direction 0 "Forward" 1 "OnComing" 2 "Left" 3 "Right" 4 "unknown" 5 "refer to headingangle" 6 "reserved";
VAL_ 898 ACC_Target2LatRange 0 "-50-50m" 1001 "reserved" 1023 "Invalid";
VAL_ 898 ACC_Target2LngRange 0 "-100~300" 4001 "reserved" 4095 "Invalid";
VAL_ 898 ACC_Target2Type 0 "no display" 1 "sedan" 2 "motorcycle" 3 "pedestrian" 4 "Bicycle" 5 "Bus" 6 "VAN" 7 "truck" 8 "Cone Consideration" 9 "Warning Column" 10 "Water Horse" 11 "Anti-Collision Bucket" 12 "others" 13 "animal" 14 "Non-road vehicle" 15 "CarWarningTriangle";
VAL_ 898 ACC_Target2ID 0 "";
VAL_ 898 ACC_Target2Detection 0 "not dectected" 1 "IP display" 2 "Front Target" 3 "IACC target" 4 "AEB target" 5 "dangerous target（ELK、UDLC、RCW, etc）" 6 "other target" 7 "reserved";
VAL_ 898 ACC_Target1ZoneID 0 "no zoneid" 1 "zoneid1-11
0xC=hostlane_zone
0xD=leftlane_zone
0xE=rightlane_zone
0xF=LLLane_zone
0x10=RRLane_zone
0x11=Ramp_zone" 18 "others" 19 "reserved";
VAL_ 898 ACC_Target1Direction 0 "Forward" 1 "OnComing" 2 "Left" 3 "Right" 4 "unknown" 5 "refer to headingangle" 6 "reserved";
VAL_ 898 ACC_Target1LatRange 0 "-50-50m" 1001 "reserved" 1023 "Invalid";
VAL_ 898 ACC_Target1LngRange 0 "-100~300" 4001 "reserved" 4095 "Invalid";
VAL_ 898 ACC_Target1Type 0 "no display" 1 "sedan" 2 "motorcycle" 3 "pedestrian" 4 "Bicycle" 5 "Bus" 6 "VAN" 7 "truck" 8 "Cone Consideration" 9 "Warning Column" 10 "Water Horse" 11 "Anti-Collision Bucket" 12 "others" 13 "animal" 14 "Non-road vehicle" 15 "CarWarningTriangle";
VAL_ 898 ACC_Target1ID 0 "";
VAL_ 898 ACC_Target1Detection 0 "not dectected" 1 "IP display" 2 "Front Target" 3 "IACC target" 4 "AEB target" 5 "dangerous target（ELK、UDLC、RCW, etc）" 6 "other target" 7 "reserved";
VAL_ 898 ACC_LaneEquationStatus 0 "no display" 1 "Left Lane" 2 "Right Lane" 3 "reserved";
VAL_ 898 ACC_LaneEquationC3 0 "y=C0+C1*x+(1/2)*C2*x^2+(1/6)*C3*x^3，其中C3为车道线曲率变化率，换算公式为(-2047 + (0x0 ~ 0xFFE))*2^(-21))";
VAL_ 898 ACC_LaneEquationC2 0 "y=C0+C1*x+(1/2)*C2*x^2+(1/6)*C3*x^3，其中C2为车道线曲率，换算公式为(-2047 + (0x0 ~ 0xFFE))*2^(-16))";
VAL_ 898 ACC_LaneEquationC1 0 "y=C0+C1*x+(1/2)*C2*x^2+(1/6)*C3*x^3，其中C1为车辆相对预期轨迹的角度，换算公式为-1+(0x0 ~ 0xFFE)*2^(-11))";
VAL_ 898 ACC_LaneQuality 0 "";

VAL_ 676 LCDAR_AEBVehilceHoldReq 0 " No hold" 1 " hold";
VAL_ 676 LCDAR_LDWShakeLevStatus 0 "reserved" 1 "low" 2 "normal" 3 "high";
VAL_ 676 LCDAR_LDWVibrationWarningReq 0 " No Warning不报警" 1 " Left Warning左报警" 2 "Right Warning右报警" 3 " reserved";
VAL_ 676 LCDA_BSDLCAMode 0 "Light" 1 "Light+Vibration" 2 "Light+Voice" 3 "OFF";
VAL_ 676 LCDAR_RCTBStatus 0 "OFF(关闭)" 1 "Inactive(未激活)" 2 "Active" 3 "Failure";
VAL_ 676 LCDAR_ELK_oAlert 0 "No warning" 1 "level 1" 2 "level 2" 3 "Reserved";
VAL_ 676 LCDAR_ELK_oStatus 0 "OFF(关闭)（预留）" 1 "Inactive(未激活)" 2 "Active" 3 "Failure";
VAL_ 676 LCDAR_Left_ELK_oAlert 0 "No warning" 1 "level 1" 2 "level 2" 3 "Reserved";
VAL_ 676 LCDAR_RCTBActive 0 " not Active" 1 " Active.";
VAL_ 676 LCDAR_SystemStatus 0 "Reserved" 1 "StartUp" 2 "Running" 3 "Blocked" 4 "Calibration" 5 "ShutDown" 6 "Hot" 7 "Failure";

VAL_ 1426 LAS_NotSleep_BYTE7BIT1 0 "Inactive" 1 " IGN硬线信号为ON档/总线电源挡位信号非OFF";
VAL_ 1426 LAS_NotSleep_BYTE7BIT0 0 "Inactive" 1 " CAN网络上其他节点不允许休眠";
VAL_ 1426 LAS_WakeUp_BYTE4BIT1 0 "Inactive" 1 " IG唤醒（若不接IG硬线则无此位）";
VAL_ 1426 LAS_WakeUp_BYTE4BIT0 0 "Inactive" 1 " CAN网络管理报文唤醒";

VAL_ 80 SRS_WarningLampStatus 0 "Lamp off" 1 "Lamp on" 2 "Lamp Flashing" 3 "Not Used";
VAL_ 80 SRS_DriverBuckleSwitchStatus 0 "Buckled" 1 "Unbuckle " 2 "Not Used" 3 "Not Used
Default value= 0x0";
VAL_ 80 SRS_CrashOutputStatusCheckSum 0 "(SRS_CrashOutputStatus) XOR 0xF";
VAL_ 80 SRS_CrashOutputStatus 0 "No Crash" 1 "crash " 2 "Not Used";
VAL_ 80 SRS_CRCCheck_50 0 "0xFF，XOR value=0xFF，input data reflected=No，Result data reflected=No，check=0x48，Magic check=0xC4）";

VAL_ 368 EPS_ActualMotorTorq 2047 "";
VAL_ 368 EPS_ActualTorsionBarTorq 2047 "";
VAL_ 368 EPS_MinSafetyTorsionBarTorq 2047 "";
VAL_ 368 EPS_MaxSafetyTorsionBarTorq 2047 "";

VAL_ 384 SAS_SASFailure 0 "No Failure" 1 "Failure";
VAL_ 384 SAS_Calibrated 0 "Calibrated" 1 " Not Calibrated";
VAL_ 384 SAS_SteeringAngleValid 0 "Valid" 1 "Invalid";

VAL_ 580 ACC_AEBSpeedDropLevel 0 "65kph（超过-8m/ss）" 1 "125kph（-8m/ss以内）" 2 " Reserved" 3 " Reserved";
VAL_ 580 ADS_EOMTOReq 0 "无请求" 1 "1级接管请求" 2 "2级接管请求" 3 "3级接管请求";
VAL_ 580 ACC_HandsOnReq 0 "no request" 1 "level 1 request" 2 "level 2 request" 3 "level 3 request" 4 "level 4 request" 5 "reserved";
VAL_ 580 ACC_LatTakeoverReq 0 "no request" 1 "level 1 request" 2 "level 2 request" 3 "reserved";
VAL_ 580 ACC_LngTakeOverReq 0 "no request" 1 "level 1 request" 2 "level 2 request" 3 "reserved";
VAL_ 580 ACC_LDWShakeLevStatus 0 "reserved" 1 "low" 2 "normal" 3 "high";
VAL_ 580 ACC_TextInfoForDriver 0 "no display" 1 "unable to activate ACC" 2 "ACC active control is cancelled" 3 "ACC error by Front Radar" 4 "ACC temporary unavailable by others" 5 "EPB activate" 6 "No forward gear" 7 "Seatbelt unbuckled" 8 "Engine No Running" 9 "ESP off" 10 "bonnet is Open" 11 "Speed over 150kph" 12 "ACC Error by EMS/VCU/TCU" 13 "拖车模式激活ACC预警" 14 "ACC Error by EPBI" 15 "ACC unintended exit warning" 16 "door is open" 17 "brake pedal is applied" 18 "speed reduce by ramp" 19 "speed reduce by tunnel" 20 "ACC error by Front Camera" 21 "speed reduce by condition" 22 "speed reduce by SpdLimited" 23 "ACC cannot active by Race mode" 24 "speed reduce by Tollstation" 25 "ACC cannot active by snow mode" 26 "SteeringAngle is over" 27 "emergency brake suddenly" 28 "前雷达不可用，ACC退出" 29 "前摄像头不可用，ACC退出" 30 "Bad weather" 31 "设定车速达到上限" 32 "设定车速达到下限" 33 "设定车速达到限速值" 34 "激活提示" 35 "退出提示-安全带解开" 36 "退出提示-开启车门" 37 "不可激活原因-纵向系统故障" 38 "加速提示-避让并行大车" 39 "减速提示-避让并行大车" 40 "减速提示-避让行人" 41 "减速提示-前方红灯" 42 "减速提示-减速带" 43 "不可激活原因-泊车功能激活" 44 "前方绿灯，车辆可通行" 45 "跟车起步提醒" 46 "减速提示-能见度低" 47 "不可激活原因-摄像头温度异常" 48 "不可激活原因-拖车功能激活" 49 "超车抑制提醒" 50 "不可激活原因-全地形功能激活" 51 "减速提示-服务区
0x34=减速提示-环岛
0x35=车流限速
0x36=危险场景，请接管车辆
0x37=对向车辆，请谨慎驾驶
0x38=建议降低巡航车速-光线暗
0x39=不可激活-功能开关未开
0x3A=减速提示-天气条件差";
VAL_ 580 ACC_AEBCtrlType 0 "no request" 1 "AEB C&U（AEB车辆）" 2 "AEB VRU（AEB行人）" 3 "AEB Cyclist（AEB骑行者）" 4 "EBA（制动辅助）" 5 "FCTB（前向横向AEB）" 6 "RCTB(后向横向AEB)" 7 "Reserved";
VAL_ 580 ACC_FuelCutOffPrevention 0 "no request" 1 "request";
VAL_ 580 ACC_AccTrqReqActive 0 " not Active" 1 " Active.";
VAL_ 580 ACC_AEBVehilceHoldReq 0 " No hold" 1 " hold";
VAL_ 580 ACC_FCWPreWarning 0 " no warning" 1 " warning";
VAL_ 580 ACC_FCWLatentWarning 0 " no warning" 1 " warning";
VAL_ 580 ACC_FCWActive 0 " not Active" 1 " Active";
VAL_ 580 ACC_PrefillActive 0 " not Active" 1 " Active";
VAL_ 580 ACC_AWBActive 0 " not Active" 1 " Active";
VAL_ 580 ACC_AWBlevel 0 "  no level" 1 "  level 1" 2 "  level 2" 3 "  level 3" 4 "  level 4" 5 " reserved";
VAL_ 580 ACC_ABAActive 0 " not Active" 1 " Active";
VAL_ 580 ACC_ABAlevel 0 " level 0" 1 "level 1" 2 " level 2" 3 " level 3";
VAL_ 580 ACC_AEBActive 0 " not Active" 1 " Active.";
VAL_ 580 ACC_EmergencyDataRrdReq 0 "no request" 1 "Event 1 Request" 2 "Event 2 Request" 3 "Image Record";
VAL_ 580 ACC_Driveoff_Request 0 " No request" 1 " request";
VAL_ 580 ACC_ACCMode 0 "OFF mode" 1 "Passive mode" 2 "StandBy mode" 3 " Active Control mode" 4 " Brake Only mode" 5 " Override" 6 " Stand Wait mode" 7 " Failure mode";
VAL_ 580 ACC_CDDActive 0 " not active" 1 " Active";
VAL_ 580 ACC_EngineStartStopRequest 0 "No request" 1 "EngineAutoStopRequest" 2 "EngineAutoStartRequest" 3 "reserved";
VAL_ 580 ACC_DecToStop 0 "no demand" 1 " demand";
VAL_ 580 ACC_TCUCreepProhibition 0 "no request" 1 "request";
VAL_ 580 ACC_LKAStatus 0 "Off" 1 "Standby" 2 "Active" 3 "Failure";
VAL_ 580 ACC_LDWVibrationWarningReq 0 " No Warning不报警" 1 " Left Warning左报警" 2 "Right Warning右报警" 3 " reserved";
VAL_ 580 ACC_LDWStatus 0 "";

VAL_ 664 BCM_DriverDoorLockStatus 0 "Lock" 1 "Unlock" 2 "Not used" 3 "Error";
VAL_ 664 BCM_LeftRearDoorStatus 0 "Close" 1 "Open";

VAL_ 775 ACC_CSLmodeStatus 0 "All Speed limit-sign" 1 "Road Camera";
VAL_ 775 ACC_CSLEnableStatus 0 "off" 1 "on";
VAL_ 775 ACC_AEBTargetSelected 0 " no object selected" 1 " only longitudinal object selected" 2 " only crossing object selected" 3 " both longitudinal & crossing object selected" 4 " LTA object selected" 5 " CPTA object selected" 6 " both LTA & CPTA object selected" 7 " Reserved";
VAL_ 775 ACC_AEBFeatureConfig 0 " AEBM not configured" 1 " AEBVru not configured" 2 " EBA not configured" 3 " AEBP not configured" 4 " Prewarning not configured" 5 " PrewarningVru not configured" 6 " AWB not configured" 7 " LTA not configured" 8 " CPTA not configured" 9 " Prefill not configured" 10 " HBA not configured" 11 " Reserved";
VAL_ 775 ACC_LatDeviationDis 0 "idle" 1 "0.1-0.5" 6 "Reserved";
VAL_ 775 ACC_LatDeviationReason 0 "idle" 1 "靠近本车道目标" 2 "弯道" 3 "护栏" 4 "锥形筒" 5 "Reserved" 7 "其他原因";
VAL_ 775 ACC_IACCSuspendReason 0 "idle" 1 "无控制信息（线、车、Freespace都不存在）" 2 "手拉方向盘" 3 "加速度过大" 4 "规划异常" 5 "转角或转速过大" 6 "Reserved" 7 "其他原因";
VAL_ 775 ACC_IACCProhibitionTime 0 " no prohibition" 1 " 0 ~ 99" 101 "Reserve";
VAL_ 775 ACC_RRLanecolor 0 "Not Detected" 1 "white" 2 "yellow" 3 "white plus yellow" 4 "unknown" 5 "reserved" 6 "reserved" 7 "Invalid";
VAL_ 775 ACC_RLanecolor 0 "Not Detected" 1 "white" 2 "yellow" 3 "white plus yellow" 4 "unknown" 5 "reserved" 6 "reserved" 7 "Invalid";
VAL_ 775 ACC_LLLanecolor 0 "Not Detected" 1 "white" 2 "yellow" 3 "white plus yellow" 4 "unknown" 5 "reserved" 6 "reserved" 7 "Invalid";
VAL_ 775 ACC_LLanecolor 0 "Not Detected" 1 "white" 2 "yellow" 3 "white plus yellow" 4 "unknown" 5 "reserved" 6 "reserved" 7 "Invalid";
VAL_ 775 ACC_RLaneDistanceFus 0 "-5-1" 120 "reserved";
VAL_ 775 ACC_LLaneDistanceFus 0 "-1-5" 121 "reserved";
VAL_ 775 ACC_RRLaneDis 0 "-12-0" 241 "reserved";
VAL_ 775 ACC_LLLaneDis 0 "0-12" 241 "reserved";
VAL_ 775 ACC_Target7ZoneID 0 "no zoneid" 1 "zoneid1-11
0xC=hostlane_zone
0xD=leftlane_zone
0xE=rightlane_zone
0xF=LLLane_zone
0x10=RRLane_zone
0x11=Ramp_zone" 18 "others" 19 "reserved";
VAL_ 775 ACC_Target7Direction 0 "Forward" 1 "OnComing" 2 "Left" 3 "Right" 4 "unknown" 5 "refer to headingangle" 6 "reserved";
VAL_ 775 ACC_Target7LatRange 0 "-50-50m" 1001 "reserved" 1023 "Invalid";
VAL_ 775 ACC_Target7LngRange 0 "-100~300" 4001 "reserved" 4095 "Invalid";
VAL_ 775 ACC_Target7Type 0 "no display" 1 "sedan" 2 "motorcycle" 3 "pedestrian" 4 "Bicycle" 5 "Bus" 6 "VAN" 7 "truck" 8 "Cone Consideration" 9 "Warning Column" 10 "Water Horse" 11 "Anti-Collision Bucket" 12 "others" 13 "animal" 14 "Non-road vehicle" 15 "CarWarningTriangle";
VAL_ 775 ACC_Target7ID 0 "";
VAL_ 775 ACC_Target7Detection 0 "not dectected" 1 "IP display" 2 "Front Target" 3 "IACC target" 4 "AEB target" 5 "dangerous target（ELK、UDLC、RCW, etc）" 6 "other target" 7 "reserved";
VAL_ 775 ACC_Target6ZoneID 0 "no zoneid" 1 "zoneid1-11
0xC=hostlane_zone
0xD=leftlane_zone
0xE=rightlane_zone
0xF=LLLane_zone
0x10=RRLane_zone
0x11=Ramp_zone" 18 "others" 19 "reserved";
VAL_ 775 ACC_Target6Direction 0 "Forward" 1 "OnComing" 2 "Left" 3 "Right" 4 "unknown" 5 "refer to headingangle" 6 "reserved";
VAL_ 775 ACC_Target6LatRange 0 "-50-50m" 1001 "reserved" 1023 "Invalid";
VAL_ 775 ACC_Target6LngRange 0 "-100~300" 4001 "reserved" 4095 "Invalid";
VAL_ 775 ACC_Target6Type 0 "no display" 1 "sedan" 2 "motorcycle" 3 "pedestrian" 4 "Bicycle" 5 "Bus" 6 "VAN" 7 "truck" 8 "Cone Consideration" 9 "Warning Column" 10 "Water Horse" 11 "Anti-Collision Bucket" 12 "others" 13 "animal" 14 "Non-road vehicle" 15 "CarWarningTriangle";
VAL_ 775 ACC_Target6ID 0 "";
VAL_ 775 ACC_Target6Detection 0 "not dectected" 1 "IP display" 2 "Front Target" 3 "IACC target" 4 "AEB target" 5 "dangerous target（ELK、UDLC、RCW, etc）" 6 "other target" 7 "reserved";
VAL_ 775 ACC_AEBEnable 0 "off" 1 "on" 2 "forbidden" 3 "reserved";
VAL_ 775 ACC_VehicleStartRemindSts 0 "off" 1 "passive" 2 "standby" 3 "active" 4 "failure " 5 "reserve";
VAL_ 775 ACC_CSLAEnableStatus 0 "OFF" 1 "All Speed-Limit" 2 "Road Camera" 3 "invalid";
VAL_ 775 ACC_CSLSetReq 0 "no request" 1 "request";
VAL_ 775 ACC_ACCTargetRelSpd 0 "-250-250" 501 "reserved";
VAL_ 775 ACC_FRadarCalibrationStatus 0 " Calibration is ok" 1 " Calibration In Process" 2 " Calibration never done" 3 "  Calibration Failed";
VAL_ 775 ACC_FCWSettingStatus 0 "early" 1 "normal" 2 "late" 3 "Off" 4 "forbidden" 5 "Reserved";
VAL_ 775 ACC_ACCEPBrequest 0 " no request" 1 "  request";
VAL_ 775 ACC_ObjValid 0 " no object" 1 " target object detected";
VAL_ 775 ACC_TimeGapSet 0 "no display" 1 "1.0S" 2 "1.4S" 3 "1.8S" 4 "2.4S" 5 "reserved";
VAL_ 775 ACC_DistanceLevel 0 "no display" 1 " Level 1" 2 "Level 2" 3 " Level 3" 4 "reserved";

VAL_ 786 ACC_SBUNCountDown 1 "0s
0x2=1s
0x3=2s
0x4=3s
0x5=4s
0x6=5s
0x7=6s
0x8=7s
0x9=8s
0xA=9s
0xB=10s
0xC=11s
0xD=12s
0xE=13s
0xF=14s
0x10=15s
0x11~0x1F=Reserved";
VAL_ 786 ACC_RRLaneQuality 0 "";
VAL_ 786 ACC_LLaneQuality 0 "";
VAL_ 786 ACC_horizenLongPos 0 " 0~200m" 201 "reserved" 254 "Out of Range" 255 "unknown";
VAL_ 786 ACC_ACCSysdeactiveReason 0 "无" 1 "纵向故障" 2 "ABS触发" 3 "驾驶员主动退出" 4 "安全停车退出" 5 "其他" 6 "ESP触发" 7 " TCS触发" 8 " VDC触发" 9 " AEB触发" 10 " APA触发" 11 " 驾驶模式不支持" 12 " 动力系统异常" 13 " 关联系统不可用" 14 " EPB拉起" 15 " 制动盘过热" 16 " 主驾车门打开" 17 " 驾驶员安全带未系" 18 " ESP功能未开启" 19 " 非前进挡" 20 " 车辆超速" 21 " 车辆状态不支持" 22 " 制动踏板踩下" 23 " 车速无效" 24 " 车辆后溜" 25 " 车辆碰撞" 26 " HDC激活" 27 " 跟停目标丢失" 28 " 超越模式超时" 29 "Reserve";
VAL_ 786 ACC_AEBTargetStatus 0 "No diaplay" 1 "静止" 2 "运动" 3 "reserved";
VAL_ 786 ADS_SpdLimitedStatus 0 "未限速" 1 "基于限速牌限速" 2 "基于电子眼限速" 3 "";
VAL_ 786 ADS_AutoHeadlightshift_Req 0 "Off" 1 "On";
VAL_ 786 ADS_UDLCTurnLightReq 0 " no request" 1 " Left Request OFF" 2 "  Right Request OFF" 3 "Left Request ON" 4 " Right Request ON" 5 "Reserved" 7 "Invalid";
VAL_ 786 ACC_Selflearning_status 0 "int" 1 "earning" 2 "completed" 3 "rsvrd";
VAL_ 786 ADS_NDAAudioWarEnableStatus 0 "OFF" 1 "ON";
VAL_ 786 ADS_ADSVoiceRequest 0 "no display" 1 "TakeOver" 2 "saft parking" 3 "deactivate" 4 "handsoff0" 5 "drowsiness" 6 "IACC Cancel" 7 "IACC active" 8 "IACC suspend" 9 "IACCorACC Override" 10 "ACC Cancel" 11 "ACC Active" 12 "TJP active" 13 "SeatPostureRectify" 14 "vehicle distance" 19 "speed out of range" 20 "lanechange to leftpath" 21 " lanechange to rightpath" 22 "lane change return" 23 "lanechange to left side soon" 24 "lanechange to right side soon" 25 "plz lanechange for PathThroughRamp in right side" 26 "plz lanechange for PathThroughRamp in left side" 31 "lanechange condition not support" 32 "waiting lanechange timeout" 33 "Be careful of complex road condition" 34 "Be careful of confluence ahead" 35 "frequent accidents" 36 "Congestion ahead" 37 " plz override for PathThroughRamp" 38 " plz override because of toll station ahead" 39 "recommend TJP" 40 "SpdLimit" 41 "NID cancle" 42 "NID active" 43 "NID out" 44 "Bad weather lead to NID out" 45 "sharp turn lead to NID out" 46 "Toll Station lead to NID out" 47 "accidents lead to NID out" 48 "roadworks lead to NID out" 49 " NID out after 300m" 50 " NID out after 200m" 51 " NID out after 100m" 52 "concetrate" 53 "concetrate to see road" 54 "NID out after 1000m" 55 "sharp turn Plz watch out" 56 "leaving out current road plz watch out" 57 "merge in main road plz watch out" 58 "ramp ahead to turn left" 59 "ramp ahead to turn right" 60 "merge in main road" 61 "turn left right now" 62 "turn right right now" 63 "overtakeing left" 64 "overtaking right" 65 "heavy braking" 66 "over speed" 67 "前方红绿灯，智能限速" 68 "前方人行横道，请注意减速慢行" 69 "前方人行横道，智能限速" 70 "前方收费站，请注意减速慢行" 71 "前方收费站，智能限速" 72 "前方弯道，智能限速" 73 "智能加速避让并行车辆" 74 "智能减速避让并行车辆" 75 "主动加速提醒" 76 "您正处于弯道中，辅助驾驶IACC无法激活" 77 "激活失败，请先减速到120KM/H" 78 "激活失败，请先关闭转向灯" 79 "请手握方向盘，观察路况" 80 "请打开车灯" 81 "停车完成" 82 "您未进行智能驾驶用户认证，请谨慎操作！" 83 "您已超速接近系统控制极限，IACC即将退出" 84 "车辆临时靠左行驶，避让并行车辆" 85 "车辆临时靠右行驶，避让并行车辆 " 86 "车辆临时靠左行驶，避让护栏" 87 "车辆临时靠右行驶，避让护栏" 88 "请关闭转向灯（换道完成或回退对中完成时）" 89 "两边车道均可变道" 90 "左侧车道支持变道" 91 "右侧车道支持变道" 92 "请在主机中打开主动换道设置开关" 93 "车速超出范围，自动换道条件不满足" 94 "雨量过大，自动换道条件不满足" 95 "换道尝试超时中止" 96 "推荐向左换道，道路更畅通" 97 "推荐向左换道，超越前车" 98 "推荐向左换道，避让前方障碍物" 99 "推荐向左换道，避让前方异常车辆" 100 "推荐向左换道，道路前方有道路施工" 101 "推荐向左换道，提前避让右侧汇入车辆" 102 "推荐向左换道，前方道路即将向左合并" 103 "推荐向左换道，避让右侧大型车辆" 104 "推荐向左换道，避让后方大型车辆" 105 "推荐您向右换道，道路更畅通" 106 "推荐向右换道，超越前车" 107 "推荐向右换道，避让前方障碍物" 108 "推荐向右换道，避让前方异常车辆" 109 "推荐向右换道，道路前方有道路施工" 110 "推荐向右换道，提前避让左侧汇入车辆" 111 "推荐向右换道，前方道路即将向右合并" 112 "推荐向右换道，避让左侧大型车辆" 113 "推荐向右换道，避让后方大型车辆" 114 "当前急弯，暂不支持辅助换道" 115 "向左自动换道，道路更畅通" 116 "向左自动换道，超越前车" 117 "向左自动换道，避让前方障碍物" 118 "向左自动换道，避让前方异常车辆" 119 "向左自动换道，道路前方有道路施工" 120 "向左自动换道，提前避让右侧汇入车辆" 121 "向左自动换道，前方道路即将向左合并" 122 "向左自动换道，避让右侧大型车辆" 123 "向左自动换道，避让后方大型车辆" 124 "向右自动换道，道路更畅通" 125 "向右自动换道，超越前车" 126 "向右自动换道，避让前方障碍物" 127 "向右自动换道，避让前方异常车辆" 128 "向右自动换道，道路前方有道路施工" 129 "向右自动换道，提前避让左侧汇入车辆" 130 "向右自动换道，前方道路即将向左合并" 131 "向右自动换道，避让左侧大型车辆" 132 "向右自动换道，避让后方大型车辆" 133 "取消换道" 134 "避让侧后方来车，取消自动换道" 135 "避让危险车辆，取消自动换道" 136 "避让行人，取消自动换道" 137 "避让障碍物，取消自动换道" 138 "前方道路汇流，即将向左换道" 139 "前方道路汇流，即将向右换道" 140 "前方道路施工，即将向左换道" 141 "前方道路施工，即将向右换道" 142 "前方交通事故，即将向左换道" 143 "前方交通事故，即将向右换道" 144 "正在继续换道" 145 "前方接近匝道，推荐向左换道" 146 "前方接近匝道，推荐向右换道" 147 "前方汇入主路，推荐向右换道" 148 "前方汇入主路，推荐向左换道" 149 "推荐向左换道" 150 "推荐向右换道" 151 "前方车辆行驶缓慢，推荐向左超车" 152 "前方车辆行驶缓慢，推荐向右超车" 153 "车道合并，推荐向左换道" 154 "车道合并，推荐向右换道" 155 "前方路口汇流，推荐向左换道" 156 "前方路口汇流，推荐向右换道" 157 "前方交通事故，推荐向左换道" 158 "前方交通事故，推荐向右换道" 159 "道路天气环境较差，请手握方向盘" 160 "前方道路变化，请手握方向盘" 161 "超出坡度或曲率范围，请手握方向盘" 162 "前方交通事故，请手握方向盘" 163 "前方道路施工，请手握方向盘" 164 "前方经过环岛，请手握方向盘" 165 "前方经过服务区，请手握方向盘" 166 "前方经过隧道，请手握方向盘" 167 "前方经过匝道，请手握方向盘" 168 "超出电子围栏或无法定位，请手握方向盘" 169 "道路颠簸，请手握方向盘" 170 "前方存在行人，请手握方向盘" 171 "系统异常，请手握方向盘" 172 "油门超越，请手握方向盘" 173 "请保持ESP功能开启" 174 "请保持挡位为D挡或S挡" 175 "请系好安全带" 176 "前方道路汇流，推荐向左换道" 177 "前方道路汇流，推荐向右换道" 178 "请注意侧方车辆，谨慎驾驶" 179 "请立即接管刹车" 180 "请立即接管方向盘" 181 "NID out after 2000m" 182 "NID out after 500m" 183 "NID3.0自动激活" 184 "道路原因需要手动汇入左侧主路 " 185 "道路原因需要手动汇入右侧主路" 186 "道路原因需要手动进入左侧匝道" 187 "道路原因需要手动进入右侧匝道" 188 "左车辆切入趋势-不减速" 189 "左车辆切入-减速" 190 "右车辆切入趋势-不减速" 191 "右车辆切入-减速" 192 "左车辆切入趋势-不减速" 193 "右车辆切入趋势-不减速" 194 " bonnet is Open;" 195 "BAACC不可激活-安全带" 196 "ACC/IACC不可激活-超速" 197 "ACC不可激活-发动机" 198 "ACC不可激活-未开启ESP" 199 "ACC不可激活-车门未关" 200 "ACC不可激活-未松开制动踏板" 201 "ACC/IACC不可激活-系统故障" 202 "ACC不可激活-仪表故障" 203 "ACC不可激活-正在APA模式" 204 "ACC不可激活-雪地模式" 205 "ACC/IACC不可激活-转向角过大" 206 "ACC/IACC不可激活-请注意安全驾驶（注意力，疲劳）" 207 "ACC不可激活-道路湿滑" 208 "ACC不可激活-后备箱打开" 209 "ACC不可激活-胎压不正常" 210 "ACC/IACC不可激活-天气条件差" 211 "ACC不可激活-道路颠簸" 212 "ACC不可激活-前方行人" 213 "ACC不可激活-前方骑行者" 214 "ACC不可激活-道路弯道过大" 215 "ACC不可激活-道路坡度过大" 216 "ACC/IACC不可激活-转向灯" 217 "ACC/IACC不可激活-脱手" 218 "IACC/ACC不可激活-主动转向" 219 "ACC不可激活-赛道模式" 220 "ACC待机可激活" 221 "定速巡航稳定 " 222 "跟车巡航稳定" 223 "前方慢车，减速跟车行驶" 224 "车辆减速-速度超过限速" 225 "车辆减速-经过隧道" 226 "车辆减速-前方红绿灯" 227 "车辆减速-前方人行横道" 228 "车辆减速-前方收费站" 229 "车辆减速-前方弯道" 230 "res恢复设定的速度" 231 "主动提速提示" 232 "意外退出提示-前雷达不可用" 233 "意外退出提示-前摄像头不可用" 234 "意外退出提示-安全带解开" 235 "意外退出提示-车门打开" 236 "意外退出提示- ESP功能关闭" 237 "意外退出提示-挡位切换" 238 "IACC不可激活-车道线" 239 "IACC不可激活-行车数据记录异常" 240 "IACC不可激活-曲率" 241 "IACC不可激活-未对中" 242 "IACC不可激活-航向角过大" 243 "IACC不可激活-横向控制无效" 244 "IACC不可激活-安全停车中" 245 "IACC可激活" 246 "车道线对中" 247 "车道线丢失" 248 "脱手报警" 249 "IACC意外退出-雨刮故障" 250 "IACC意外退出-远近光灯故障" 251 "IACC意外退出-电量过低" 252 "IACC意外退出-制动盘过热" 253 "IACC意外退出-转向灯故障" 254 "IACC意外退出-灯光故障" 255 "IACC意外退出-系统故障" 256 "IACC意外退出-胎压异常" 257 "IACC意外退出-胎温异常" 258 "IACC意外退出-数据记录异常" 259 "IACC意外退出-道路天气环境较差" 260 "IACC意外退出-超出坡度或曲率范围" 261 "IACC意外退出-前方道路施工" 262 "IACC意外退出-道路颠簸" 263 "IACC意外退出-道路湿滑" 264 "IACC意外退出-危险目标" 265 "IACC意外退出-前方存在骑行者" 266 "IACC意外退出-前方存在行人" 267 "IACC意外退出-请求系好安全带" 268 "IACC意外退出-油门超越中，请安全驾驶" 269 "NID3.0可激活待机" 270 "NID3.0自动激活" 271 "NID3.0意外退出 " 272 "急减速" 273 "IACC中断" 274 "IACC恢复" 275 "DDSAS已激活" 276 "" 277 "" 278 "" 279 "" 280 "" 281 "" 282 "" 283 "安全带解开，ACC计时退出" 285 "安全带解开，IACC计时退出" 286 "IACC激活到中断" 287 "车门打开，ACC计时退出" 288 "车门打开，IACC计时退出" 289 "" 290 "领航智驾已暂停" 511 "reserved";
VAL_ 786 ADS_EOMWarnning 0 "no warnning" 1 "L1 warnning" 2 "L2 warnning" 3 "L3 warnning" 4 "Reserved";
VAL_ 786 ACC_DriverWindowControl 0 " No Request" 1 " 0%~100% (支持百分比形式)" 102 " Reserved";
VAL_ 786 ACC_AEBTargetDirection 0 "Forward" 1 "OnComing" 2 "Left" 3 "Right" 4 "unknown" 5 "no display" 6 "reserved";
VAL_ 786 ACC_AEBTargetDetection 0 "no detected" 1 "detected";
VAL_ 786 ACC_AEBTargetType 0 "no display" 1 "sedan" 2 "motorcycle" 3 "pedestrian" 4 "Bicycle" 5 "Bus" 6 "van" 7 "truck" 8 "reserved" 15 "other";

VAL_ 832 AC_FrBlowType 0 "blow face" 1 "blow face/blow feet" 2 "blow feet" 3 "blow fee/defroster" 4 "defroster" 5 "blowface/defroster" 6 " blowface/blowfeet/defroster" 7 "Invalid";

VAL_ 839 TPMS_RRPressureWarning 0 "No warning" 1 "High pressure warning" 2 "Low pressure warning" 3 "Quik leakage" 4 "Lost Sensor" 5 "Sensor battery low" 6 "Sensor failure" 7 "Reserved";
VAL_ 839 TPMS_LRPressureWarning 0 "No warning" 1 "High pressure warning" 2 "Low pressure warning" 3 "Quik leakage" 4 "Lost Sensor" 5 "Sensor battery low" 6 "Sensor failure" 7 "Reserved";
VAL_ 839 TPMS_LFPressureWarning 0 "No warning" 1 "High pressure warning" 2 "Low pressure warning" 3 "Quik leakage" 4 "Lost Sensor" 5 "Sensor battery low" 6 "Sensor failure" 7 "Reserved";
VAL_ 839 TPMS_RFPressureWarning 0 "No warning" 1 "High pressure warning" 2 "Low pressure warning" 3 "Quik leakage" 4 "Lost Sensor" 5 "Sensor battery low" 6 "Sensor failure" 7 "Reserved";

VAL_ 869 IMS_DriverREyeDetect 0 "Invalid" 1 "Not detected" 2 "detected" 5 "Reserved";
VAL_ 869 IMS_DriverLEyeDetect 0 "Invalid" 1 "Not detected" 2 "detected" 4 "Reserved";
VAL_ 869 IMS_JawOffsetValue 0 " 0cm" 1 "1cm~15cm";
VAL_ 869 IMS_BrowOffsetValue 0 " 0cm" 1 "1cm~15cm";
VAL_ 869 IMS_DriverEyeClosestatus 0 " both eyes close" 1 "left eye close" 2 " right ?eye close" 3 "both eyes open" 4 " Reserved" 7 " Invalid";
VAL_ 869 IMS_HeadDetectSts_Yaw 0 "-75~75" 152 "Reserved" 255 "invalid";
VAL_ 869 IMS_HeadDetectSts_Roll 0 "-45~45" 92 "Reserved" 255 "invalid";
VAL_ 869 IMS_HeadDetectSts_Pitch 0 "-25~45" 72 "Reserved" 255 "invalid";
VAL_ 869 IMS_IMSStatus 0 " Off" 1 " Standby" 2 " Active" 3 " Camera Blocked" 4 " Failure" 5 " Reserved" 7 " Invalid";
VAL_ 869 IMS_EyeGazeStatus 0 "-75~75" 152 "Reserved" 255 "invalid";
VAL_ 869 IMS_EyeDetectSatus 0 "0~100%" 101 "Reserved" 255 "invalid   ";
VAL_ 869 IMS_DrowsinessStatus 0 " Awake" 1 " Slightly Drowsy" 2 " Drowsy" 3 "Microsleep" 4 " Reserved" 5 " Unavailable" 6 "Unknown" 7 " Invalid";
VAL_ 869 IMS_DriverHeadDetect 0 "Invalid" 1 "Not detected" 2 "detected" 3 "Reserved";
VAL_ 869 IMS_DistractionStatus 0 " Not Distracted" 1 " Distracted" 2 "Unknown" 3 " Invalid";

VAL_ 870 AC_EnvironmentalTemp 0 "-40~87℃" 255 "Invalid";
VAL_ 870 AC_EnvironmentalTempVD 0 "Valid" 1 "Invalid";

VAL_ 903 BCM_RainfallLevel 0 "No rain" 1 "Level 1" 2 "Level 2" 3 "Level 3" 4 "Level 4" 5 "Level 5?" 6 "Level 6" 7 "Level 7" 8 "Level 8" 9 "Level 9" 10 "Level 10" 11 "Level 11" 12 "Level 12" 13 "level 13" 14 "init value" 15 "Invalid value";
VAL_ 903 BCM_FrontWiperStatus 0 "OFF" 1 "Low" 2 "High" 3 "Error";

VAL_ 912 BCM_SOH_LifePercent 0 "%0-100%" 101 "Reserved" 255 "invalid";
VAL_ 912 BCM_PMSLevel 0 "电量正常" 1 "电量低" 2 "电量消耗过多" 3 "预留Reserved";

VAL_ 918 BCM_SunroofStatus 0 "Close" 1 "Open";

VAL_ 1287 HU_LDWSenStyle 0 "Inactive" 1 "early" 2 "late" 3 "Reserved";
VAL_ 1287 HU_OverspeedWarningOffRatioset_EU 0 "-3%~3%" 13 "Reserved" 46 "Inactive" 47 "Invalid.";
VAL_ 1287 HU_TSRSpeedLimitChangeSoundEn 0 "Inactive" 1 "Off" 2 "On" 3 "Reserved";
VAL_ 1287 HU_TSREnable 0 "Inactive" 1 "Off" 2 "On" 3 "Reserved";
VAL_ 1287 HU_CSLWarnOffsetTp 0 "inactive" 1 "Absolute" 2 "Related" 3 "reserved";
VAL_ 1287 HU_CSLEnable 0 "inactive" 1 "off" 2 "on" 3 "reserved";
VAL_ 1287 HU_CSLmode 0 "inactive" 1 "All Speed limit-sign" 2 "Road Camera" 3 "reserved";
VAL_ 1287 HU_VC_CruiseSetSpeed 0 "No Request" 1 "1-250" 251 "Reserved" 255 "Invalid";
VAL_ 1287 HU_VC_CruiseSetDistance 0 "No Request" 1 "Level 1" 2 "Level 2" 3 "Level 3" 4 "Level 4" 5 "Level 5" 6 "reserved" 7 "Invalid";
VAL_ 1287 HU_VC_CruiseControl 0 "No Request" 1 "ACC Activate" 2 "ACC Resume" 3 "IACC Activate" 4 "IACC Resume" 5 "Cancel" 6 "Reserved" 7 "Invalid";
VAL_ 1287 HU_FCWSetting 0 "Early" 1 "Normal" 2 "Late" 3 "Off" 4 "Reserved" 7 "Invalid";
VAL_ 1287 HU_AutoBrakeEnable 0 "off" 1 "on" 2 "reserved" 3 "Invalid";
VAL_ 1287 HU_IACCEnable 0 "inactive 未激活" 1 "ACC 自适应巡航" 2 "IACC 巡航驾驶辅助" 3 "NID 导航驾驶辅助";
VAL_ 1287 HU_HMAEnable 0 "off" 1 "on" 2 "reserved" 3 "Invalid";
VAL_ 1287 HU_TSRSwitch 0 "off" 1 "on";
VAL_ 1287 HU_LASWarningModeSelection 0 "inactive" 1 "visual" 2 "sound" 3 "vibration" 4 "sound and vibration" 5 "Reserved";
VAL_ 1287 HU_LASModeSelection 0 "Inactive" 1 "LDW" 2 "LKA" 3 "LDW+LKA" 4 "Reserved" 7 "OFF";
VAL_ 1287 HU_OverspeedWarningOffset 0 "-10~20km/h" 31 "Reserved" 47 "Invalid.";
VAL_ 1287 HU_OverspeedWarningEnable 0 "Inactive" 1 "OFF" 2 "ON" 3 "Reserved";
VAL_ 1287 HU_OverspeedSoundWarEnable 0 "Inactive" 1 "Off" 2 "On" 3 " Reserved";
VAL_ 1287 HU_NDAAudioWarEnable 0 "Inactive" 1 "Off" 2 "On" 3 " Reserved";

VAL_ 1302 HU_LocalTimeSystem 0 "24h" 1 "12h" 2 "Reserved" 3 "Invalid";
VAL_ 1302 HU_LocalTimeValid 0 "Valid" 1 "Not Valid";
VAL_ 1302 HU_CurrentLocationLatitude 134217727 "";
VAL_ 1302 HU_CurrentLocationLongitude 268435455 "";
VAL_ 1302 HU_CurrentLocationValid 0 "Valid" 1 "Not Valid";

VAL_ 391 ESP_VehicleSpeed 0 "0~360km/h" 6401 "Reserved" 8191 "Invalid
APA2.0接收";
VAL_ 391 ESP_VehicleSpeedValid 0 "Valid" 1 "NotValid";
VAL_ 391 ESP_TCSFailStatus 0 "Noerror" 1 "Error";
VAL_ 391 ESP_ESPFunctionStatus 0 "OFF" 1 "ON";
VAL_ 391 ESP_ESPActiveStatus 0 "NotActive" 1 "Active";
VAL_ 391 ESP_EngTorqIncFrontActive 0 "NotActive" 1 "Active";
VAL_ 391 ESP_EngTorqDecActive 0 "NotActive" 1 "Active";
VAL_ 391 ESP_ABSFailStatus 0 "Noerror" 1 "Error";
VAL_ 391 ESP_ABSActiveStatus 0 "NotActive" 1 "Active";

VAL_ 404 EMS_EngSts 3 "Reserved" 2 "Running" 1 "Crank" 0 "Stop";
VAL_ 404 EMS_EngSpdErr 0 "No error" 1 "Error";
VAL_ 404 EMS_EngFuCutOff 1 "True" 0 "False";

VAL_ 381 PCU_PwrTrainSts 3 "预留" 2 "Running" 1 "Crank" 0 "Stop";
VAL_ 381 PCU_BrkPedlSts 0 "Not Pressed" 1 "Pressed" 2 "Reserved" 3 "Error";
VAL_ 381 PCU_AccPedlVld 1 "invalid" 0 "valid";
VAL_ 381 PCU_QECACC 0 "no error" 1 "reversible error" 2 "irreversible error" 3 "not defined";
VAL_ 381 PCU_PwrIndcdRealTqWhlFailr 0 "valid" 1 "invalid";
VAL_ 381 PCU_ECGPOvrd 0 "no override" 1 "driver override";
VAL_ 381 PCU_AccReqPossible 0 "noerror" 1 "error";
VAL_ 381 PCU_TarGearReqValid 0 "Valid" 1 "Invalid";
VAL_ 381 PCU_TarGearReq 0 "Initial value" 1 "1st gear" 2 "2nd gear" 3 "3rd gear" 4 "4th gear" 5 "5th gear" 6 "6th gear" 7 "7th gear" 8 "8th gear" 9 "Reverse" 10 "Neutral" 11 "Reserved" 12 "Reserved" 14 "Reserved" 15 "Invalid";
VAL_ 381 PCU_RealAccPedlVld 1 "invalid" 0 "valid";

VAL_ 382 EPS_Handwheel_Relang_Valid 0 "valid" 1 "invalid";
VAL_ 382 EPS_Pinionang 14410 "Reserved";
VAL_ 382 EPS_LatCtrlActive 0 "Not Actived" 1 "Actived";
VAL_ 382 EPS_LatCtrlAvailabilityStatus 0 "not Availability " 1 "Availability" 2 "failure" 3 "reserved";
VAL_ 382 EPS_MeasuredTorsionBarTorqValid 0 "可用" 1 "不可用";
VAL_ 382 EPS_MeasuredTorsionBarTorque 0 "(Measured Torsion Bar Torque – 0x800)*0.01
?方向盘左打为正。
?在EPS ECU 开始助力之前、Initial 值输出为(0)。
?异常状态（确定故障）的情况下、Invalid 值输出为(0xFFF)。";

VAL_ 442 ACC_LKAinhaitWarning 0 "no warning" 1 "left warning" 2 "right warning";
VAL_ 442 ACC_LatAngReqActive 0 "not Active" 1 "Active";
VAL_ 442 ACC_LatAngReq 14410 "Reserved";
VAL_ 442 ACC_MotorTorqueMinLimitRequest 2047 " Reserved";
VAL_ 442 ACC_MotorTorqueMaxLimitRequest 2047 " Reserved";

VAL_ 523 ESP_AEBSpeedDropActive 0 "65kph（超过-8m/ss）" 1 "125kph（-8m/ss以内）" 2 " Reserved" 3 " Reserved";
VAL_ 523 ESP_VehicleStandstillVld 0 "valid" 1 "Invalid";
VAL_ 523 IBCU_BrkPedlStsGbVld 0 "NotInitialized" 1 "Normal" 2 "Invalid";
VAL_ 523 IBCU_BrkPedoplStsGb 0 " 制动未踩下" 101 " 制动踩下" 254 "异常";
VAL_ 523 ESP_Vehicle_Speed_Reference 0 "0~360km/h" 6401 "Reserved" 8191 "Invalid";
VAL_ 523 IBCU_precheckStatus 0 "not checked" 1 "in checking" 2 "checked" 3 "failed";
VAL_ 523 IBCU_BrakeDiscHighTempWarning 0 "no failure" 1 "OverheatLevel1" 2 "OverheatLevel2" 3 "reserved";
VAL_ 523 Wheel_Speed_RR_Valid_Data 0 "Valid" 1 "NotValid";
VAL_ 523 Wheel_Speed_RR_Direction 0 "Forward" 1 "backward" 2 "Standstill" 3 "Invalid";
VAL_ 523 Wheel_Speed_RL_Valid_Data 0 "Valid" 1 "NotValid";
VAL_ 523 Wheel_Speed_RL_Direction 0 "Forward" 1 "backward" 2 "Standstill" 3 "Invalid";
VAL_ 523 Wheel_Speed_FR_Valid_Data 0 "Valid" 1 "NotValid";
VAL_ 523 Wheel_Speed_FR_Direction 0 "Forward" 1 "backward" 2 "Standstill" 3 "Invalid";
VAL_ 523 Wheel_Speed_FL_Valid_Data 0 "Valid" 1 "NotValid";
VAL_ 523 Wheel_Speed_FL_Direction 0 "Forward" 1 "backward" 2 "Standstill" 3 "Invalid";
VAL_ 523 ESP_VehicleStandstill 0 "notstandstill" 1 "standstill";
VAL_ 523 ESP_VDCActive 0 "NotActive" 1 "Active";
VAL_ 523 ESP_TCSActive 0 "NotActive" 1 "Active";
VAL_ 523 ESP_QDCACC 0 "noerror" 1 "error" 2 "reserved" 3 "reserved";
VAL_ 523 ESP_PrefillAvailable 0 "notavailable" 1 "available";
VAL_ 523 ESP_PrefillActive 0 "notactive" 1 "active";
VAL_ 523 ESP_OnlyABSActive 0 "NotActive" 1 "Active";
VAL_ 523 ESP_MasCylBrakePressureValid 0 "Valid" 1 "Invalid";
VAL_ 523 ESP_HDC_STATUS 0 "OFF" 1 "ON" 2 "Standby" 3 "Error";
VAL_ 523 ESP_CDD_Available 0 "notavailable" 1 "available";
VAL_ 523 ESP_CDD_Active 0 "notactive" 1 "active";
VAL_ 523 ESP_BrakeOverHeatBrakeDiscTemp 0 "nothigh" 1 "temptoohigh";
VAL_ 523 ESP_BrakeForce 0 "nobrakeforce" 1 "havebrakeforce";
VAL_ 523 ESP_AWBavailable 0 "notavailable" 1 "available";
VAL_ 523 ESP_AWBactive 0 "notactive" 1 "active";
VAL_ 523 ESP_AutoHoldAvailable 0 "Valid" 1 "Invalid";
VAL_ 523 ESP_AutoHoldActive 0 "NotActive" 1 "Active";
VAL_ 523 ESP_AEBdecActive 0 "notactive" 1 "active";
VAL_ 523 ESP_AEBAvailable 0 "notavailable" 1 "available";
VAL_ 523 ESP_ABAavailable 0 "notavailable" 1 "available";
VAL_ 523 ESP_ABAactive 0 "notactive" 1 "active";

VAL_ 591 EPS_LDW_ShakeLevStatus 0 "reserved" 1 "low" 2 "normal" 3 "high";
VAL_ 591 EPS_ConcussAvailabilityStatus 0 "Concuss Availability 震动可用但是未震动" 1 "Concuss Active震动激活中" 2 "EPS Concuss failure  EPS震动故障不可用" 3 "reserved";
VAL_ 591 EPS_TorqueAssistMode 0 "Normal" 1 "light" 2 "heavy" 3 "unknow";
VAL_ 591 EPS_IACC_abortreason 0 "NO_DRIVING_INTERUPTION" 1 "DRIVER_RECOVERY(Over ride)" 2 "VEHICLE_SPEED ERROR" 3 "REQUEST ERROR" 4 "DAE_THERMAL_SECURITY" 5 "OTHER_DEFAULT" 6 "ADAS message Error（CD569项目0x6=Reserved）" 7 "Reserved";

VAL_ 651 BCM_TurnIndicatorLeft 0 "OFF" 1 "ON" 2 "Not used" 3 "Error";
VAL_ 651 BCM_TurnIndicatorRight 0 "OFF" 1 "ON" 2 "Not used" 3 "Error";
VAL_ 651 BCM_emergencylightstatus 0 "OFF" 1 "ON" 2 "Not used" 3 "Error（故障）";
VAL_ 651 BCM_PowerStatusFeedback 0 "OFF" 1 "ACC" 2 "ON" 3 "Start";
VAL_ 651 BCM_DriverDoorStatus 0 "Close" 1 "Open";
VAL_ 651 BCM_LowBeamStatus 0 "OFF" 1 "ON" 2 "Not used" 3 "Reserved";
VAL_ 651 BCM_HighBeamStatus 0 "OFF" 1 "ON" 2 "Not used" 3 "Reserved";
VAL_ 651 BCM_TurnLightSwitchSts 0 "Not Actived" 1 "Left Actived" 2 "Right Actived" 3 "Invalid";

VAL_ 721 BCM_TrunkDoorStatus 0 "Close" 1 "Open";
VAL_ 721 BCM_RightRearDoorStatus 0 "Close" 1 "Open";
VAL_ 721 BCM_PassengerDoorStatus 0 "Close" 1 "Open";

VAL_ 734 IP_DISFail 0 "no error" 1 "error";
VAL_ 734 IP_QDashACCFail 0 "no error" 1 "error" 2 "reserved" 3 "reserved";

VAL_ 794 AD_AEBSysFltSts 0 "No error" 1 "Performance degradation" 2 "system temporary unvailable" 3 "Service required" 4 "Reserved";
VAL_ 794 AD_FCWSysFltSts 0 "No error" 1 "Performance degradation" 2 "system temporary unvailable" 3 "Service required" 4 "Reserved";
VAL_ 794 ACC_LDWSenStyle 0 "early" 1 "late" 2 "Reserved" 3 "Reserved";
VAL_ 794 ACC_HandsoffWarningExitReason 0 "idle" 1 "手握方向盘" 2 "手拉方向盘" 3 "按下方向盘按键" 4 "搬动操纵杆" 5 "功能退出" 6 "最小安全策略执行完成" 7 "其他原因";
VAL_ 794 ACC_LngTakeOverReqReason 0 "无报警" 1 "控制器、传感器故障" 2 "关联子系统故障" 3 "超过纵向控制能力限制" 4 "前方存在危险目标（如行人、锥形筒等障碍物）" 5 "车道线置信度低" 6 "超过车速、曲率、方向盘转角等阈值限制" 7 "非安全状态（ESP、TCS、AEB等触发）" 8 "触发风险减缓" 9 "超出ODD范围" 10 "预留";
VAL_ 794 ACC_ELKAlert 0 "No warning" 1 "left Warning" 2 "right Warning" 3 "reserved";
VAL_ 794 ACC_ELKEnableStatus 0 "off" 1 "on";
VAL_ 794 ACC_ELKInterventionMode 0 " off" 1 " Road edge" 2 " Overtaking" 3 " Oncoming.";
VAL_ 794 ACC_ELKMode 0 " off" 1 " passive" 2 "active" 3 " fault" 4 " reserved.";
VAL_ 794 ACC_RRLaneDetection 0 "not detected" 1 "Dashed" 2 "solid" 3 "fence/road edge";
VAL_ 794 ACC_LLLaneDetection 0 "not detected" 1 "Dashed" 2 "solid" 3 "fence/road edge";
VAL_ 794 ACC_HighBeamControl 0 "No Request" 1 "Request" 2 "Reserved";
VAL_ 794 ACC_TargetBasedLateralControl 0 "no lateral control" 1 "around Based" 2 "lane based" 3 "target based";
VAL_ 794 ACC_IACCHWATextInfoForDriver 0 "no display" 1 "IACC Cancel" 2 "IACC deactivate" 3 "IACC unintended exit" 4 "unable to activate IACC" 5 "lane condition not available" 6 "ADR/DVR Status not Match" 7 "longitudinal control not available" 8 "IACC not available by EPS" 9 "exceed speed limit" 10 "driver overrides steering" 11 "caution about driving safty" 12 " system error" 13 " prohibition request for safestop" 14 "turn light switch on" 15 "Hands on plz" 16 " Please turn on IACC in incall " 17 " unable to active in curve" 18 " unable to active for not in lane/crossing lane" 19 "Longitude Exit" 20 "takeover request with safety stoping" 21 "takeover request with safety stop completed" 22 "other system error" 23 "unable to active in Bad weather" 24 "Prohibition request for rdf" 25 "Lights OFF please" 26 "智慧偏移，避让大型车辆" 27 " Driver Drowsy or Distracted" 28 "HWA recommend" 29 "lane missing" 30 "请注意侧方车辆，谨慎驾驶" 31 "系统退出-安全带解开" 32 "系统状态-暂停状态" 33 "系统退出-车门开启" 34 "邻车道大车压迫-偏移避让正在偏移，避让车辆" 35 "锥形桶等障碍物-偏移避让" 36 "护栏压迫-偏移避让" 37 "智慧偏移，避让小车";
VAL_ 794 ACC_EmergencyLightingRequest 0 "no request" 1 "Level1" 2 "Level2" 3 "OFF";
VAL_ 794 ACC_DriverHandsOffStatus 0 "hands off" 1 "hands on Level1" 2 "hand on Level2" 3 "unkown";
VAL_ 794 ACC_IACCHWAMode 0 "off" 1 "standby" 2 "passive" 3 "active" 4 "suspend" 5 " prohibition" 6 "reserved" 7 "failure";
VAL_ 794 ACC_LaneChangeStatus 0 "未变道" 1 "向左变道中" 2 "向右变道中" 3 "变道结束";
VAL_ 794 ACC_RoadCurvatureFar 0 "-0.03-0.03" 121 "reserved";
VAL_ 794 ACC_RoadCurvatureNear 0 "-0.03-0.03" 121 "reserved";
VAL_ 794 ACC_RoadCurvature 0 "-0.03-0.03" 121 "reserved";
VAL_ 794 ACC_IACCHWAEnable 0 "ACC=自适应巡航（默认）" 1 "IACC=巡航驾驶辅助" 2 "NID 导航驾驶辅助" 3 "Reserved";
VAL_ 794 ACC_RLaneMarkerType 0 "Dashed" 1 "solid" 2 "road edge" 3 "double lane mark" 4 "Botts' dots" 5 "other" 6 "fence" 7 "no display" 8 "Fishbone" 9 "Dashed_Fishbone";
VAL_ 794 ACC_LLaneMarkerType 0 "Dashed" 1 "solid" 2 "road edge" 3 "double lane mark" 4 "Botts' dots" 5 "other" 6 "fence" 7 "no display" 8 "Fishbone" 9 "Dashed_Fishbone";
VAL_ 794 ACC_HostLaneRightStatus 0 "No_display" 1 "Tracking" 2 "Intervention" 3 "Warning 
0x4=Centering " 5 "Crossing " 6 "UDLC_Wait_Active" 7 "ACCactive" 8 "UDLC_Not_Active" 9 " IACCactive" 10 "NIDactive";
VAL_ 794 ACC_HostLaneLeftStatus 0 "No_display" 1 "Tracking" 2 "Intervention" 3 "Warning 
0x4=Centering " 5 "Crossing " 6 "UDLC_Wait_Active" 7 "ACCactive" 8 "UDLC_Not_Active" 9 " IACCactive" 10 "NIDactive";
VAL_ 794 ACC_LASWarningModeSelectionSts 0 "Reserved" 1 "sound" 2 "vibration" 3 "sound and vibration" 4 "Reserved";
VAL_ 794 ACC_LASModeSelectionStatus 0 "Reserved" 1 "LDW" 2 "LKA" 3 "LDW+LKA" 4 "Reserved" 7 "OFF";
VAL_ 794 ACC_FRadarFailureStatus 0 " no failure" 1 "blind" 2 "reversible failure" 3 " irrversible failure";
VAL_ 794 ACC_AEBTargetLatRange 0 "-50-50m" 1001 "reserved";
VAL_ 794 ACC_AEBTargetRelSpeed 0 "-250-250" 501 "reserved";
VAL_ 794 ACC_AEBTargetLngRange 0 "-70~180" 501 "reserved" 511 "no display";
VAL_ 794 ACC_Voiceinfo 0 "no voice" 1 "latentWarning voive" 2 "FCW/AEB voice" 3 "ACC object detect voice" 4 "ACC object disappeared voice" 5 "ACC/IACC takeover request voice" 6 "Lane Left dangerous warning  voice" 7 "Lane Right dangerous warning  voice" 8 "reserved" 9 "IACC Active voice" 10 "IACC exit voice" 11 "reserved" 12 "reserved" 13 "cruise unintended exit" 14 "TrafficWarning" 15 "reserved";
VAL_ 794 ACC_AEBTargetmode 0 "none" 1 "video only mode" 2 "rader only mode" 3 "fusion mode";
VAL_ 794 ACC_AEBTextInfo 0 "no display" 1 "AEB Error by camera" 2 "AEB Error by FR" 3 "AEB Error by Dasy" 4 "AEB Error by FCR" 5 "AEB Error by EPBi" 6 "AEB Error by SAS" 7 "AEB Error by SRS" 8 "AEB Error by EMS" 9 "AEB Error by TCU" 10 "AEB Error by other" 11 "AEB Error by high temperature " 12 "reserved";
VAL_ 794 ACC_AEBStatus 0 "off" 1 "on" 2 " reserved" 3 "failure";
